VERSION "dbc-export 1 2026.26.6.5"

NS_ :

BS_:

BU_: APB APP APS DAS EPAS3S ESP GTW IBST PARK RADC RCM RCM2 RCM3 TPMS TRCM USM

BO_ 913 EPAS3S_alertMatrix: 8 EPAS3S
 SG_ EPAS3S_matrixIndex M : 0|4@1+ (1,0) [0|15] "" Vector__XXX
 SG_ EPAS3S_a001_sent1Mia m0 : 4|1@1+ (1,0) [0|1] "" Vector__XXX
 SG_ EPAS3S_a002_sent1Error m0 : 5|1@1+ (1,0) [0|1] "" Vector__XXX
 SG_ EPAS3S_a003_trqSens1Supply m0 : 6|1@1+ (1,0) [0|1] "" Vector__XXX
 SG_ EPAS3S_a004_trqSens1Eeprom m0 : 7|1@1+ (1,0) [0|1] "" Vector__XXX
 SG_ EPAS3S_a005_sent2Mia m0 : 8|1@1+ (1,0) [0|1] "" Vector__XXX
 SG_ EPAS3S_a006_sent2Error m0 : 9|1@1+ (1,0) [0|1] "" Vector__XXX
 SG_ EPAS3S_a007_trqSens2Supply m0 : 10|1@1+ (1,0) [0|1] "" Vector__XXX
 SG_ EPAS3S_a008_trqSens2Eeprom m0 : 11|1@1+ (1,0) [0|1] "" Vector__XXX
 SG_ EPAS3S_a009_sentDiff m0 : 12|1@1+ (1,0) [0|1] "" Vector__XXX
 SG_ EPAS3S_a010_trqSensCalError m0 : 13|1@1+ (1,0) [0|1] "" Vector__XXX
 SG_ EPAS3S_a011_currentSensError m0 : 14|1@1+ (1,0) [0|1] "" Vector__XXX
 SG_ EPAS3S_a012_currentSensCalError m0 : 15|1@1+ (1,0) [0|1] "" Vector__XXX
 SG_ EPAS3S_a013_gateDriveError m0 : 16|1@1+ (1,0) [0|1] "" Vector__XXX
 SG_ EPAS3S_a014_gateDriveTxError m0 : 17|1@1+ (1,0) [0|1] "" Vector__XXX
 SG_ EPAS3S_a015_gateDriveEeprom m0 : 18|1@1+ (1,0) [0|1] "" Vector__XXX
 SG_ EPAS3S_a016_phaseUhighUv m0 : 19|1@1+ (1,0) [0|1] "" Vector__XXX
 SG_ EPAS3S_a017_phaseUlowUv m0 : 20|1@1+ (1,0) [0|1] "" Vector__XXX
 SG_ EPAS3S_a018_phaseVhighUv m0 : 21|1@1+ (1,0) [0|1] "" Vector__XXX
 SG_ EPAS3S_a019_phaseVlowUv m0 : 22|1@1+ (1,0) [0|1] "" Vector__XXX
 SG_ EPAS3S_a020_phaseWhighUv m0 : 23|1@1+ (1,0) [0|1] "" Vector__XXX
 SG_ EPAS3S_a021_phaseWlowUv m0 : 24|1@1+ (1,0) [0|1] "" Vector__XXX
 SG_ EPAS3S_a022_phaseUhighOv m0 : 25|1@1+ (1,0) [0|1] "" Vector__XXX
 SG_ EPAS3S_a023_phaseUlowOv m0 : 26|1@1+ (1,0) [0|1] "" Vector__XXX
 SG_ EPAS3S_a024_phaseVhighOv m0 : 27|1@1+ (1,0) [0|1] "" Vector__XXX
 SG_ EPAS3S_a025_phaseVlowOv m0 : 28|1@1+ (1,0) [0|1] "" Vector__XXX
 SG_ EPAS3S_a026_phaseWhighOv m0 : 29|1@1+ (1,0) [0|1] "" Vector__XXX
 SG_ EPAS3S_a027_phaseWlowOv m0 : 30|1@1+ (1,0) [0|1] "" Vector__XXX
 SG_ EPAS3S_a028_phaseUbootUv m0 : 31|1@1+ (1,0) [0|1] "" Vector__XXX
 SG_ EPAS3S_a029_phaseVbootUv m0 : 32|1@1+ (1,0) [0|1] "" Vector__XXX
 SG_ EPAS3S_a030_phaseWbootUv m0 : 33|1@1+ (1,0) [0|1] "" Vector__XXX
 SG_ EPAS3S_a031_abnormalShutdown m0 : 34|1@1+ (1,0) [0|1] "" Vector__XXX
 SG_ EPAS3S_a032_vRegOutputUv m0 : 35|1@1+ (1,0) [0|1] "" Vector__XXX
 SG_ EPAS3S_a033_vRegOutputOv m0 : 36|1@1+ (1,0) [0|1] "" Vector__XXX
 SG_ EPAS3S_a034_vRegError m0 : 37|1@1+ (1,0) [0|1] "" Vector__XXX
 SG_ EPAS3S_a035_vbbSupplyUv m0 : 38|1@1+ (1,0) [0|1] "" Vector__XXX
 SG_ EPAS3S_a036_vbbSupplyOv m0 : 39|1@1+ (1,0) [0|1] "" Vector__XXX
 SG_ EPAS3S_a037_motPos1ParityError m0 : 40|1@1+ (1,0) [0|1] "" Vector__XXX
 SG_ EPAS3S_a038_motPos1Uv m0 : 41|1@1+ (1,0) [0|1] "" Vector__XXX
 SG_ EPAS3S_a039_motPos1MagnetMia m0 : 42|1@1+ (1,0) [0|1] "" Vector__XXX
 SG_ EPAS3S_a040_motPos1LogicError m0 : 43|1@1+ (1,0) [0|1] "" Vector__XXX
 SG_ EPAS3S_a041_motPos1tempError m0 : 44|1@1+ (1,0) [0|1] "" Vector__XXX
 SG_ EPAS3S_a042_motPos2ParityError m0 : 45|1@1+ (1,0) [0|1] "" Vector__XXX
 SG_ EPAS3S_a043_motPos2Uv m0 : 46|1@1+ (1,0) [0|1] "" Vector__XXX
 SG_ EPAS3S_a044_motPos2MagnetMia m0 : 47|1@1+ (1,0) [0|1] "" Vector__XXX
 SG_ EPAS3S_a045_motPos2LogicError m0 : 48|1@1+ (1,0) [0|1] "" Vector__XXX
 SG_ EPAS3S_a046_motPos2tempError m0 : 49|1@1+ (1,0) [0|1] "" Vector__XXX
 SG_ EPAS3S_a047_motPosCorrError m0 : 50|1@1+ (1,0) [0|1] "" Vector__XXX
 SG_ EPAS3S_a048_motPosCalError m0 : 51|1@1+ (1,0) [0|1] "" Vector__XXX
 SG_ EPAS3S_a049_piCtrlError m0 : 52|1@1+ (1,0) [0|1] "" Vector__XXX
 SG_ EPAS3S_a050_mcuSmuError m0 : 53|1@1+ (1,0) [0|1] "" Vector__XXX
 SG_ EPAS3S_a051_mcuSupError m0 : 54|1@1+ (1,0) [0|1] "" Vector__XXX
 SG_ EPAS3S_a052_intWatchdogError m0 : 55|1@1+ (1,0) [0|1] "" Vector__XXX
 SG_ EPAS3S_a053_extWatchdogError m0 : 56|1@1+ (1,0) [0|1] "" Vector__XXX
 SG_ EPAS3S_a054_memoryProtectError m0 : 57|1@1+ (1,0) [0|1] "" Vector__XXX
 SG_ EPAS3S_a055_floatPointError m0 : 58|1@1+ (1,0) [0|1] "" Vector__XXX
 SG_ EPAS3S_a056_battUv m0 : 59|1@1+ (1,0) [0|1] "" Vector__XXX
 SG_ EPAS3S_a057_battUvReduced m0 : 60|1@1+ (1,0) [0|1] "" Vector__XXX
 SG_ EPAS3S_a058_battOv m0 : 61|1@1+ (1,0) [0|1] "" Vector__XXX
 SG_ EPAS3S_a059_battOvReduced m0 : 62|1@1+ (1,0) [0|1] "" Vector__XXX
 SG_ EPAS3S_a060_battBridgeDiff m0 : 63|1@1+ (1,0) [0|1] "" Vector__XXX
 SG_ EPAS3S_a061_bridgeUv m1 : 4|1@1+ (1,0) [0|1] "" Vector__XXX
 SG_ EPAS3S_a062_assistCorrError m1 : 5|1@1+ (1,0) [0|1] "" Vector__XXX
 SG_ EPAS3S_a063_dampCorrError m1 : 6|1@1+ (1,0) [0|1] "" Vector__XXX
 SG_ EPAS3S_a064_phaseCompCorrError m1 : 7|1@1+ (1,0) [0|1] "" Vector__XXX
 SG_ EPAS3S_a065_trqTarCorrError m1 : 8|1@1+ (1,0) [0|1] "" Vector__XXX
 SG_ EPAS3S_a066_returnCorrError m1 : 9|1@1+ (1,0) [0|1] "" Vector__XXX
 SG_ EPAS3S_a067_yawDampCorrError m1 : 10|1@1+ (1,0) [0|1] "" Vector__XXX
 SG_ EPAS3S_a068_hystCorrError m1 : 11|1@1+ (1,0) [0|1] "" Vector__XXX
 SG_ EPAS3S_a069_eacCorrError m1 : 12|1@1+ (1,0) [0|1] "" Vector__XXX
 SG_ EPAS3S_a070_hodCorrError m1 : 13|1@1+ (1,0) [0|1] "" Vector__XXX
 SG_ EPAS3S_a071_vehSpdCorrError m1 : 14|1@1+ (1,0) [0|1] "" Vector__XXX
 SG_ EPAS3S_a072_motFeedFwdError m1 : 15|1@1+ (1,0) [0|1] "" Vector__XXX
 SG_ EPAS3S_a073_motParEstError m1 : 16|1@1+ (1,0) [0|1] "" Vector__XXX
 SG_ EPAS3S_a074_overHeatProtect m1 : 17|1@1+ (1,0) [0|1] "" Vector__XXX
 SG_ EPAS3S_a075_fspPwrCut m1 : 18|1@1+ (1,0) [0|1] "" Vector__XXX
 SG_ EPAS3S_a076_tempSensOutofRange m1 : 19|1@1+ (1,0) [0|1] "" Vector__XXX
 SG_ EPAS3S_a077_highSideFetError m1 : 20|1@1+ (1,0) [0|1] "" Vector__XXX
 SG_ EPAS3S_a078_phaseDisconnectError m1 : 21|1@1+ (1,0) [0|1] "" Vector__XXX
 SG_ EPAS3S_a079_backupCurrentPlaus m1 : 22|1@1+ (1,0) [0|1] "" Vector__XXX
 SG_ EPAS3S_a080_ecuInitArbError m1 : 23|1@1+ (1,0) [0|1] "" Vector__XXX
 SG_ EPAS3S_a081_coggCompError m1 : 24|1@1+ (1,0) [0|1] "" Vector__XXX
 SG_ EPAS3S_a082_polarityCalError m1 : 25|1@1+ (1,0) [0|1] "" Vector__XXX
 SG_ EPAS3S_a083_crcMismatch m1 : 26|1@1+ (1,0) [0|1] "" Vector__XXX
 SG_ EPAS3S_a084_eacCancelled m1 : 27|1@1+ (1,0) [0|1] "" Vector__XXX
 SG_ EPAS3S_a085_canBusOff m1 : 28|1@1+ (1,0) [0|1] "" Vector__XXX
 SG_ EPAS3S_a086_dasMia m1 : 29|1@1+ (1,0) [0|1] "" Vector__XXX
 SG_ EPAS3S_a087_dasCntError m1 : 30|1@1+ (1,0) [0|1] "" Vector__XXX
 SG_ EPAS3S_a088_dasCsError m1 : 31|1@1+ (1,0) [0|1] "" Vector__XXX
 SG_ EPAS3S_a089_espWsMia m1 : 32|1@1+ (1,0) [0|1] "" Vector__XXX
 SG_ EPAS3S_a090_espWsCntError m1 : 33|1@1+ (1,0) [0|1] "" Vector__XXX
 SG_ EPAS3S_a091_espWsCsError m1 : 34|1@1+ (1,0) [0|1] "" Vector__XXX
 SG_ EPAS3S_a092_espWrMia m1 : 35|1@1+ (1,0) [0|1] "" Vector__XXX
 SG_ EPAS3S_a093_espWrCntError m1 : 36|1@1+ (1,0) [0|1] "" Vector__XXX
 SG_ EPAS3S_a094_espWrCsError m1 : 37|1@1+ (1,0) [0|1] "" Vector__XXX
 SG_ EPAS3S_a095_espWsStatus m1 : 38|1@1+ (1,0) [0|1] "" Vector__XXX
 SG_ EPAS3S_a096_rcmMia m1 : 39|1@1+ (1,0) [0|1] "" Vector__XXX
 SG_ EPAS3S_a097_rcmCntError m1 : 40|1@1+ (1,0) [0|1] "" Vector__XXX
 SG_ EPAS3S_a098_rcmCsError m1 : 41|1@1+ (1,0) [0|1] "" Vector__XXX
 SG_ EPAS3S_a099_yawRateStatus m1 : 42|1@1+ (1,0) [0|1] "" Vector__XXX
 SG_ EPAS3S_a100_diMia m1 : 43|1@1+ (1,0) [0|1] "" Vector__XXX
 SG_ EPAS3S_a101_diCntError m1 : 44|1@1+ (1,0) [0|1] "" Vector__XXX
 SG_ EPAS3S_a102_diCsError m1 : 45|1@1+ (1,0) [0|1] "" Vector__XXX
 SG_ EPAS3S_a103_vcFrontMia m1 : 46|1@1+ (1,0) [0|1] "" Vector__XXX
 SG_ EPAS3S_a104_vcFrontCntError m1 : 47|1@1+ (1,0) [0|1] "" Vector__XXX
 SG_ EPAS3S_a105_vcFrontCsError m1 : 48|1@1+ (1,0) [0|1] "" Vector__XXX
 SG_ EPAS3S_a106_vcFrontTempMia m1 : 49|1@1+ (1,0) [0|1] "" Vector__XXX
 SG_ EPAS3S_a107_uiTuneReqMia m1 : 50|1@1+ (1,0) [0|1] "" Vector__XXX
 SG_ EPAS3S_a108_uiTuneReqCntError m1 : 51|1@1+ (1,0) [0|1] "" Vector__XXX
 SG_ EPAS3S_a109_uiTuneReqCsError m1 : 52|1@1+ (1,0) [0|1] "" Vector__XXX
 SG_ EPAS3S_a110_sasMia m1 : 53|1@1+ (1,0) [0|1] "" Vector__XXX
 SG_ EPAS3S_a111_sasCntError m1 : 54|1@1+ (1,0) [0|1] "" Vector__XXX
 SG_ EPAS3S_a112_sasCsError m1 : 55|1@1+ (1,0) [0|1] "" Vector__XXX
 SG_ EPAS3S_a113_sasStatusError m1 : 56|1@1+ (1,0) [0|1] "" Vector__XXX
 SG_ EPAS3S_a114_gtwConfigMia m1 : 57|1@1+ (1,0) [0|1] "" Vector__XXX
 SG_ EPAS3S_a115_ecuStatMia m1 : 58|1@1+ (1,0) [0|1] "" Vector__XXX
 SG_ EPAS3S_a116_ecuStatCntError m1 : 59|1@1+ (1,0) [0|1] "" Vector__XXX
 SG_ EPAS3S_a117_ecuStatCrcError m1 : 60|1@1+ (1,0) [0|1] "" Vector__XXX
 SG_ EPAS3S_a118_privateBusOff m1 : 61|1@1+ (1,0) [0|1] "" Vector__XXX
 SG_ EPAS3S_a119_pvtEcuStatMia m1 : 62|1@1+ (1,0) [0|1] "" Vector__XXX
 SG_ EPAS3S_a120_pvtEcuStatCntError m1 : 63|1@1+ (1,0) [0|1] "" Vector__XXX
 SG_ EPAS3S_a121_pvtEcuStatCrcError m2 : 4|1@1+ (1,0) [0|1] "" Vector__XXX
 SG_ EPAS3S_a122_olpActive m2 : 5|1@1+ (1,0) [0|1] "" Vector__XXX
 SG_ EPAS3S_a123_combEcu2StatFail m2 : 6|1@1+ (1,0) [0|1] "" Vector__XXX
 SG_ EPAS3S_a124_tempSensStuckInRange m2 : 7|1@1+ (1,0) [0|1] "" Vector__XXX
 SG_ EPAS3S_a125_trqSensTrimOutRange m2 : 8|1@1+ (1,0) [0|1] "" Vector__XXX
 SG_ EPAS3S_a126_apsMia m2 : 9|1@1+ (1,0) [0|1] "" Vector__XXX
 SG_ EPAS3S_a127_apsCntError m2 : 10|1@1+ (1,0) [0|1] "" Vector__XXX
 SG_ EPAS3S_a128_apsCsError m2 : 11|1@1+ (1,0) [0|1] "" Vector__XXX
 SG_ EPAS3S_a129_combEcu1StatFail m2 : 12|1@1+ (1,0) [0|1] "" Vector__XXX
 SG_ EPAS3S_a130_sasOffsetNotCal m2 : 13|1@1+ (1,0) [0|1] "" Vector__XXX
 SG_ EPAS3S_a131_phaseFeedbackError m2 : 14|1@1+ (1,0) [0|1] "" Vector__XXX
 SG_ EPAS3S_a132_motFeedFwdCounter25 m2 : 15|1@1+ (1,0) [0|1] "" Vector__XXX
 SG_ EPAS3S_a133_motFeedFwdCounter50 m2 : 16|1@1+ (1,0) [0|1] "" Vector__XXX
 SG_ EPAS3S_a134_motFeedFwdCounter85 m2 : 17|1@1+ (1,0) [0|1] "" Vector__XXX
 SG_ EPAS3S_a135_piCtrlCounter25 m2 : 18|1@1+ (1,0) [0|1] "" Vector__XXX
 SG_ EPAS3S_a136_piCtrlCounter50 m2 : 19|1@1+ (1,0) [0|1] "" Vector__XXX
 SG_ EPAS3S_a137_piCtrlCounter85 m2 : 20|1@1+ (1,0) [0|1] "" Vector__XXX
 SG_ EPAS3S_a144_diSpdMia m2 : 21|1@1+ (1,0) [0|1] "" Vector__XXX
 SG_ EPAS3S_a145_diSpdCntError m2 : 22|1@1+ (1,0) [0|1] "" Vector__XXX
 SG_ EPAS3S_a146_diSpdCsError m2 : 23|1@1+ (1,0) [0|1] "" Vector__XXX
 SG_ EPAS3S_a147_backupVehSpeed m2 : 24|1@1+ (1,0) [0|1] "" Vector__XXX
 SG_ EPAS3S_a148_vMaxAssist m2 : 25|1@1+ (1,0) [0|1] "" Vector__XXX
 SG_ EPAS3S_a149_currentSensPathSwitc m2 : 26|1@1+ (1,0) [0|1] "" Vector__XXX
 SG_ EPAS3S_a150_currentSensOffsetDet m2 : 27|1@1+ (1,0) [0|1] "" Vector__XXX
 SG_ EPAS3S_a151_dcsCboot m2 : 28|1@1+ (1,0) [0|1] "" Vector__XXX
 SG_ EPAS3S_a152_dcsDiagReg m2 : 29|1@1+ (1,0) [0|1] "" Vector__XXX
 SG_ EPAS3S_a153_dcsInitOffset m2 : 30|1@1+ (1,0) [0|1] "" Vector__XXX
 SG_ EPAS3S_a154_assistTorqueDisabled m2 : 31|1@1+ (1,0) [0|1] "" Vector__XXX
 SG_ EPAS3S_a155_backupEacActive m2 : 32|1@1+ (1,0) [0|1] "" Vector__XXX
 SG_ EPAS3S_a156_angleSensorDivergenc m2 : 33|1@1+ (1,0) [0|1] "" Vector__XXX
 SG_ EPAS3S_a157_pmState2Mia m2 : 34|1@1+ (1,0) [0|1] "" Vector__XXX
 SG_ EPAS3S_a158_pmState2CntError m2 : 35|1@1+ (1,0) [0|1] "" Vector__XXX
 SG_ EPAS3S_a159_pmState2CsError m2 : 36|1@1+ (1,0) [0|1] "" Vector__XXX
 SG_ EPAS3S_a160_latentFaultTestResul m2 : 37|1@1+ (1,0) [0|1] "" Vector__XXX
 SG_ EPAS3S_a161_initTestPhaDisconnIn m2 : 38|1@1+ (1,0) [0|1] "" Vector__XXX
 SG_ EPAS3S_a162_initTestHSDFetInfo m2 : 39|1@1+ (1,0) [0|1] "" Vector__XXX
 SG_ EPAS3S_a163_initTestGateDrvrInfo m2 : 40|1@1+ (1,0) [0|1] "" Vector__XXX
 SG_ EPAS3S_a164_initTestDCSInfo m2 : 41|1@1+ (1,0) [0|1] "" Vector__XXX
 SG_ EPAS3S_a165_epbStatusMia m2 : 42|1@1+ (1,0) [0|1] "" Vector__XXX
 SG_ EPAS3S_a166_epbStatusCntError m2 : 43|1@1+ (1,0) [0|1] "" Vector__XXX
 SG_ EPAS3S_a167_epbStatusCsError m2 : 44|1@1+ (1,0) [0|1] "" Vector__XXX
 SG_ EPAS3S_a168_torsionBarTorqueQfDe m2 : 45|1@1+ (1,0) [0|1] "" Vector__XXX

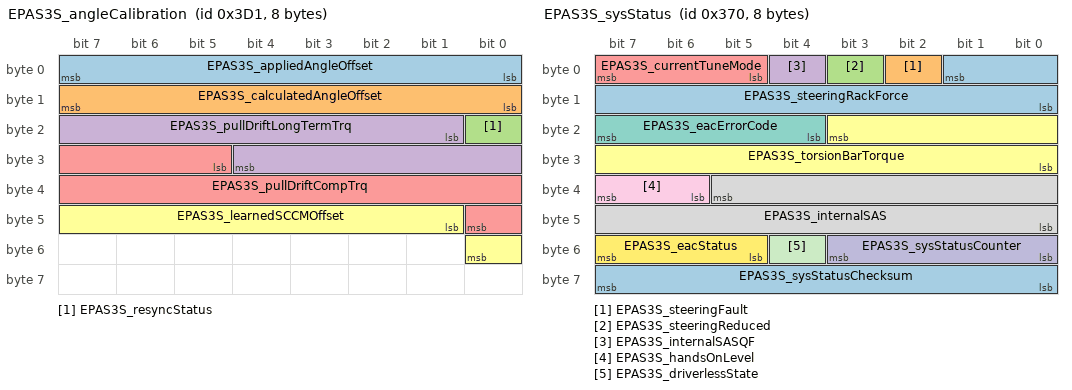
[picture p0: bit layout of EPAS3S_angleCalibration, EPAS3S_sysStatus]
BO_ 977 EPAS3S_angleCalibration: 8 EPAS3S
 SG_ EPAS3S_appliedAngleOffset : 0|8@1+ (0.1,-12.8) [-12.8|12.7] "deg" Vector__XXX
 SG_ EPAS3S_calculatedAngleOffset : 8|8@1+ (0.1,-12.8) [-12.8|12.7] "deg" Vector__XXX
 SG_ EPAS3S_resyncStatus : 16|1@1+ (1,0) [0|1] "" Vector__XXX
 SG_ EPAS3S_pullDriftLongTermTrq : 17|12@1+ (0.01,-10) [-10|10] "Nm" Vector__XXX
 SG_ EPAS3S_pullDriftCompTrq : 29|12@1+ (0.01,-10) [-10|10] "Nm" Vector__XXX
 SG_ EPAS3S_learnedSCCMOffset : 41|8@1+ (0.1,-12.8) [-12.8|12.7] "deg" Vector__XXX

BO_ 785 EPAS3S_info: 8 EPAS3S
 SG_ EPAS3S_infoIndex M : 0|8@1+ (1,0) [0|255] "" Vector__XXX
 SG_ EPAS3S_infoBuildType m10 : 8|8@1+ (1,0) [0|255] "" Vector__XXX
 SG_ EPAS3S_infoComponentID m10 : 48|16@1+ (1,0) [0|65535] "" Vector__XXX
 SG_ EPAS3S_infoPcbaID m11 : 16|8@1+ (1,0) [0|255] "" Vector__XXX
 SG_ EPAS3S_infoAssemblyID m11 : 24|8@1+ (1,0) [0|255] "" Vector__XXX
 SG_ EPAS3S_infoUsageID m11 : 32|16@1+ (1,0) [0|65535] "" Vector__XXX
 SG_ EPAS3S_infoApplicationCRC m13 : 32|32@1+ (1,0) [0|4294967295] "" Vector__XXX
 SG_ EPAS3S_infoBootUdsProtoVersion m20 : 8|8@1+ (1,0) [0|255] "" Vector__XXX
 SG_ EPAS3S_infoBootloaderCRC m20 : 32|32@1+ (1,0) [0|4294967295] "" Vector__XXX
 SG_ EPAS3S_infoSubcomponent2 m23 : 32|32@1+ (1,0) [0|4294967295] "" Vector__XXX

BO_ 880 EPAS3S_sysStatus: 8 EPAS3S
 SG_ EPAS3S_steeringRackForce : 1|10@0+ (50,-25575) [-25575|25525] "N" Vector__XXX
 SG_ EPAS3S_steeringFault : 2|1@1+ (1,0) [0|1] "" Vector__XXX
 SG_ EPAS3S_steeringReduced : 3|1@1+ (1,0) [0|1] "" Vector__XXX
 SG_ EPAS3S_internalSASQF : 4|1@1+ (1,0) [0|1] "" Vector__XXX
 SG_ EPAS3S_currentTuneMode : 5|3@1+ (1,0) [0|7] "" Vector__XXX
 SG_ EPAS3S_torsionBarTorque : 19|12@0+ (0.01,-20.5) [-20.5|20.44] "Nm" Vector__XXX
 SG_ EPAS3S_eacErrorCode : 20|4@1+ (1,0) [0|14] "" Vector__XXX
 SG_ EPAS3S_internalSAS : 37|14@0+ (0.1,-819.2) [-819.2|819] "deg" Vector__XXX
 SG_ EPAS3S_handsOnLevel : 38|2@1+ (1,0) [0|3] "" Vector__XXX
 SG_ EPAS3S_sysStatusCounter : 48|4@1+ (1,0) [0|15] "" Vector__XXX
 SG_ EPAS3S_driverlessState : 52|1@1+ (1,0) [0|1] "" Vector__XXX
 SG_ EPAS3S_eacStatus : 53|3@1+ (1,0) [0|7] "" Vector__XXX
 SG_ EPAS3S_sysStatusChecksum : 56|8@1+ (1,0) [0|255] "" Vector__XXX

BO_ 1848 EPAS3S_udsResponse: 8 EPAS3S
 SG_ EPAS3S_udsResponseData : 7|64@0+ (1,0) [0|1.84467440737e+19] "" Vector__XXX

BO_ 981 ESP_alertMatrix: 8 ESP
 SG_ ESP_matrixIndex M : 0|4@1+ (1,0) [0|15] "" Vector__XXX
 SG_ ESP_a001_ecuGenericFault m0 : 4|1@1+ (1,0) [0|1] "" Vector__XXX
 SG_ ESP_a002_valvesGenericFault m0 : 5|1@1+ (1,0) [0|1] "" Vector__XXX
 SG_ ESP_a003_outletValvesFault m0 : 6|1@1+ (1,0) [0|1] "" Vector__XXX
 SG_ ESP_a004_inletValvesFault m0 : 7|1@1+ (1,0) [0|1] "" Vector__XXX
 SG_ ESP_a005_HSVValvesFault m0 : 8|1@1+ (1,0) [0|1] "" Vector__XXX
 SG_ ESP_a006_USVValvesFault m0 : 9|1@1+ (1,0) [0|1] "" Vector__XXX
 SG_ ESP_a007_pumpMotorFault m0 : 10|1@1+ (1,0) [0|1] "" Vector__XXX
 SG_ ESP_a008_pumpMotor12VsupplyLow m0 : 11|1@1+ (1,0) [0|1] "" Vector__XXX
 SG_ ESP_a009_12VHardUndervoltage m0 : 12|1@1+ (1,0) [0|1] "" Vector__XXX
 SG_ ESP_a010_12VUndervoltage m0 : 13|1@1+ (1,0) [0|1] "" Vector__XXX
 SG_ ESP_a011_12VSystemUndervoltage m0 : 14|1@1+ (1,0) [0|1] "" Vector__XXX
 SG_ ESP_a012_netUndervoltage m0 : 15|1@1+ (1,0) [0|1] "" Vector__XXX
 SG_ ESP_a013_valveRelayUndervoltage m0 : 16|1@1+ (1,0) [0|1] "" Vector__XXX
 SG_ ESP_a014_WSSSupplyUndervoltage m0 : 17|1@1+ (1,0) [0|1] "" Vector__XXX
 SG_ ESP_a015_12VSupplyOvervoltage m0 : 18|1@1+ (1,0) [0|1] "" Vector__XXX
 SG_ ESP_a016_12VSystemOvervoltage m0 : 19|1@1+ (1,0) [0|1] "" Vector__XXX
 SG_ ESP_a017_netOvervoltage m0 : 20|1@1+ (1,0) [0|1] "" Vector__XXX
 SG_ ESP_a018_WSSSignFrontAxle m0 : 21|1@1+ (1,0) [0|1] "" Vector__XXX
 SG_ ESP_a019_WSSSignRearAxle m0 : 22|1@1+ (1,0) [0|1] "" Vector__XXX
 SG_ ESP_a020_WSSGenericTempFault m0 : 23|1@1+ (1,0) [0|1] "" Vector__XXX
 SG_ ESP_a021_WSSGeneralVDiffFault m0 : 24|1@1+ (1,0) [0|1] "" Vector__XXX
 SG_ ESP_a022_WSSDirectionFault m0 : 25|1@1+ (1,0) [0|1] "" Vector__XXX
 SG_ ESP_a023_WSSSeveralSuspected m0 : 26|1@1+ (1,0) [0|1] "" Vector__XXX
 SG_ ESP_a024_WSSReverseCurrent m0 : 27|1@1+ (1,0) [0|1] "" Vector__XXX
 SG_ ESP_a025_FrLWSSOpenOrShortToGnd m0 : 28|1@1+ (1,0) [0|1] "" Vector__XXX
 SG_ ESP_a026_FrLWSSShortTo12V m0 : 29|1@1+ (1,0) [0|1] "" Vector__XXX
 SG_ ESP_a027_FrLWSSLineInterruption m0 : 30|1@1+ (1,0) [0|1] "" Vector__XXX
 SG_ ESP_a028_FrLWSSMaxSpeedExceeded m0 : 31|1@1+ (1,0) [0|1] "" Vector__XXX
 SG_ ESP_a029_FrLWSSTooManyPulses m0 : 32|1@1+ (1,0) [0|1] "" Vector__XXX
 SG_ ESP_a030_FrLWSSLostSignal m0 : 33|1@1+ (1,0) [0|1] "" Vector__XXX
 SG_ ESP_a031_FrLWSSNoPulsesDetected m0 : 34|1@1+ (1,0) [0|1] "" Vector__XXX
 SG_ ESP_a032_FrLWSSWrongSensorType m0 : 35|1@1+ (1,0) [0|1] "" Vector__XXX
 SG_ ESP_a033_FrLWSSSignalNoise m0 : 36|1@1+ (1,0) [0|1] "" Vector__XXX
 SG_ ESP_a034_FrLWSSVDiffFault m0 : 37|1@1+ (1,0) [0|1] "" Vector__XXX
 SG_ ESP_a035_FrLWSSDirectionFault m0 : 38|1@1+ (1,0) [0|1] "" Vector__XXX
 SG_ ESP_a036_FrLWSSLargeAirGap m0 : 39|1@1+ (1,0) [0|1] "" Vector__XXX
 SG_ ESP_a037_FrLWSSSupplyShortToGnd m0 : 40|1@1+ (1,0) [0|1] "" Vector__XXX
 SG_ ESP_a038_FrLWSSGeneralFault m0 : 41|1@1+ (1,0) [0|1] "" Vector__XXX
 SG_ ESP_a039_FrRWSSOpenOrShortToGnd m0 : 42|1@1+ (1,0) [0|1] "" Vector__XXX
 SG_ ESP_a040_FrRWSSShortTo12V m0 : 43|1@1+ (1,0) [0|1] "" Vector__XXX
 SG_ ESP_a041_FrRWSSLineInterruption m0 : 44|1@1+ (1,0) [0|1] "" Vector__XXX
 SG_ ESP_a042_FrRWSSMaxSpeedExceeded m0 : 45|1@1+ (1,0) [0|1] "" Vector__XXX
 SG_ ESP_a043_FrRWSSTooManyPulses m0 : 46|1@1+ (1,0) [0|1] "" Vector__XXX
 SG_ ESP_a044_FrRWSSLostSignal m0 : 47|1@1+ (1,0) [0|1] "" Vector__XXX
 SG_ ESP_a045_FrRWSSNoPulsesDetected m0 : 48|1@1+ (1,0) [0|1] "" Vector__XXX
 SG_ ESP_a046_FrRWSSWrongSensorType m0 : 49|1@1+ (1,0) [0|1] "" Vector__XXX
 SG_ ESP_a047_FrRWSSSignalNoise m0 : 50|1@1+ (1,0) [0|1] "" Vector__XXX
 SG_ ESP_a048_FrRWSSVDiffFault m0 : 51|1@1+ (1,0) [0|1] "" Vector__XXX
 SG_ ESP_a049_FrRWSSDirectionFault m0 : 52|1@1+ (1,0) [0|1] "" Vector__XXX
 SG_ ESP_a050_FrRWSSLargeAirGap m0 : 53|1@1+ (1,0) [0|1] "" Vector__XXX
 SG_ ESP_a051_FrRWSSSupplyShortToGnd m0 : 54|1@1+ (1,0) [0|1] "" Vector__XXX
 SG_ ESP_a052_FrRWSSGeneralFault m0 : 55|1@1+ (1,0) [0|1] "" Vector__XXX
 SG_ ESP_a053_ReLWSSOpenOrShortToGnd m0 : 56|1@1+ (1,0) [0|1] "" Vector__XXX
 SG_ ESP_a054_ReLWSSShortTo12V m0 : 57|1@1+ (1,0) [0|1] "" Vector__XXX
 SG_ ESP_a055_ReLWSSLineInterruption m0 : 58|1@1+ (1,0) [0|1] "" Vector__XXX
 SG_ ESP_a056_ReLWSSMaxSpeedExceeded m0 : 59|1@1+ (1,0) [0|1] "" Vector__XXX
 SG_ ESP_a057_ReLWSSTooManyPulses m0 : 60|1@1+ (1,0) [0|1] "" Vector__XXX
 SG_ ESP_a058_ReLWSSLostSignal m0 : 61|1@1+ (1,0) [0|1] "" Vector__XXX
 SG_ ESP_a059_ReLWSSNoPulsesDetected m0 : 62|1@1+ (1,0) [0|1] "" Vector__XXX
 SG_ ESP_a060_ReLWSSWrongSensorType m0 : 63|1@1+ (1,0) [0|1] "" Vector__XXX
 SG_ ESP_a061_ReLWSSSignalNoise m1 : 4|1@1+ (1,0) [0|1] "" Vector__XXX
 SG_ ESP_a062_ReLWSSVDiffFault m1 : 5|1@1+ (1,0) [0|1] "" Vector__XXX
 SG_ ESP_a063_ReLWSSDirectionFault m1 : 6|1@1+ (1,0) [0|1] "" Vector__XXX
 SG_ ESP_a064_ReLWSSLargeAirGap m1 : 7|1@1+ (1,0) [0|1] "" Vector__XXX
 SG_ ESP_a065_ReLWSSSupplyShortToGnd m1 : 8|1@1+ (1,0) [0|1] "" Vector__XXX
 SG_ ESP_a066_ReLWSSGeneralFault m1 : 9|1@1+ (1,0) [0|1] "" Vector__XXX
 SG_ ESP_a067_ReRWSSOpenOrShortToGnd m1 : 10|1@1+ (1,0) [0|1] "" Vector__XXX
 SG_ ESP_a068_ReRWSSShortTo12V m1 : 11|1@1+ (1,0) [0|1] "" Vector__XXX
 SG_ ESP_a069_ReRWSSLineInterruption m1 : 12|1@1+ (1,0) [0|1] "" Vector__XXX
 SG_ ESP_a070_ReRWSSMaxSpeedExceeded m1 : 13|1@1+ (1,0) [0|1] "" Vector__XXX
 SG_ ESP_a071_ReRWSSTooManyPulses m1 : 14|1@1+ (1,0) [0|1] "" Vector__XXX
 SG_ ESP_a072_ReRWSSLostSignal m1 : 15|1@1+ (1,0) [0|1] "" Vector__XXX
 SG_ ESP_a073_ReRWSSNoPulsesDetected m1 : 16|1@1+ (1,0) [0|1] "" Vector__XXX
 SG_ ESP_a074_ReRWSSWrongSensorType m1 : 17|1@1+ (1,0) [0|1] "" Vector__XXX
 SG_ ESP_a075_ReRWSSSignalNoise m1 : 18|1@1+ (1,0) [0|1] "" Vector__XXX
 SG_ ESP_a076_ReRWSSVDiffFault m1 : 19|1@1+ (1,0) [0|1] "" Vector__XXX
 SG_ ESP_a077_ReRWSSDirectionFault m1 : 20|1@1+ (1,0) [0|1] "" Vector__XXX
 SG_ ESP_a078_ReRWSSLargeAirGap m1 : 21|1@1+ (1,0) [0|1] "" Vector__XXX
 SG_ ESP_a079_ReRWSSSupplyShortToGnd m1 : 22|1@1+ (1,0) [0|1] "" Vector__XXX
 SG_ ESP_a080_ReRWSSGeneralFault m1 : 23|1@1+ (1,0) [0|1] "" Vector__XXX
 SG_ ESP_a081_PressureSensorShort m1 : 24|1@1+ (1,0) [0|1] "" Vector__XXX
 SG_ ESP_a082_PMCSensorOffsetHigh m1 : 25|1@1+ (1,0) [0|1] "" Vector__XXX
 SG_ ESP_a083_PMCSensorFault m1 : 26|1@1+ (1,0) [0|1] "" Vector__XXX
 SG_ ESP_a084_BrakeFluidReservoirLow m1 : 27|1@1+ (1,0) [0|1] "" Vector__XXX
 SG_ ESP_a085_BrakeSwitchStuckHigh m1 : 28|1@1+ (1,0) [0|1] "" Vector__XXX
 SG_ ESP_a086_BrakeSwitchImplausible1 m1 : 29|1@1+ (1,0) [0|1] "" Vector__XXX
 SG_ ESP_a087_BrakeSwitchImplausible3 m1 : 30|1@1+ (1,0) [0|1] "" Vector__XXX
 SG_ ESP_a088_absContinuousControl m1 : 31|1@1+ (1,0) [0|1] "" Vector__XXX
 SG_ ESP_a089_absNoPressureIncrease m1 : 32|1@1+ (1,0) [0|1] "" Vector__XXX
 SG_ ESP_a090_vdcContinuousControl m1 : 33|1@1+ (1,0) [0|1] "" Vector__XXX
 SG_ ESP_a091_CANUndervoltage m1 : 34|1@1+ (1,0) [0|1] "" Vector__XXX
 SG_ ESP_a092_CANOvervoltage m1 : 35|1@1+ (1,0) [0|1] "" Vector__XXX
 SG_ ESP_a093_partyBusOff m1 : 36|1@1+ (1,0) [0|1] "" Vector__XXX
 SG_ ESP_a094_partyBusPassive m1 : 37|1@1+ (1,0) [0|1] "" Vector__XXX
 SG_ ESP_a095_chassisBusOff m1 : 38|1@1+ (1,0) [0|1] "" Vector__XXX
 SG_ ESP_a096_chassisBusPassive m1 : 39|1@1+ (1,0) [0|1] "" Vector__XXX
 SG_ ESP_a097_tcsRefSpeedNotInit m1 : 40|1@1+ (1,0) [0|1] "" Vector__XXX
 SG_ ESP_a098_vdcRefSpeedNotInit m1 : 41|1@1+ (1,0) [0|1] "" Vector__XXX
 SG_ ESP_a099_brakeTempModelOverheat m1 : 42|1@1+ (1,0) [0|1] "" Vector__XXX
 SG_ ESP_a100_brakeTempModelDisabled m1 : 43|1@1+ (1,0) [0|1] "" Vector__XXX
 SG_ ESP_a101_ebdFault m1 : 44|1@1+ (1,0) [0|1] "" Vector__XXX
 SG_ ESP_a102_absFault m1 : 45|1@1+ (1,0) [0|1] "" Vector__XXX
 SG_ ESP_a103_stabilityControlFault m1 : 46|1@1+ (1,0) [0|1] "" Vector__XXX
 SG_ ESP_a104_hbcEnabled m1 : 47|1@1+ (1,0) [0|1] "" Vector__XXX
 SG_ ESP_a105_ebrFault m1 : 48|1@1+ (1,0) [0|1] "" Vector__XXX
 SG_ ESP_a106_vdcActuatorFault m1 : 49|1@1+ (1,0) [0|1] "" Vector__XXX
 SG_ ESP_a107_reserved107 m1 : 50|1@1+ (1,0) [0|1] "" Vector__XXX
 SG_ ESP_a108_reserved108 m1 : 51|1@1+ (1,0) [0|1] "" Vector__XXX
 SG_ ESP_a109_reserved109 m1 : 52|1@1+ (1,0) [0|1] "" Vector__XXX
 SG_ ESP_a110_rollerBenchActive m1 : 53|1@1+ (1,0) [0|1] "" Vector__XXX
 SG_ ESP_a111_absActive m1 : 54|1@1+ (1,0) [0|1] "" Vector__XXX
 SG_ ESP_a112_espActive m1 : 55|1@1+ (1,0) [0|1] "" Vector__XXX
 SG_ ESP_a113_btcActive m1 : 56|1@1+ (1,0) [0|1] "" Vector__XXX
 SG_ ESP_a114_tvdcActive m1 : 57|1@1+ (1,0) [0|1] "" Vector__XXX
 SG_ ESP_a115_ebdActive m1 : 58|1@1+ (1,0) [0|1] "" Vector__XXX
 SG_ ESP_a116_tsmActive m1 : 59|1@1+ (1,0) [0|1] "" Vector__XXX
 SG_ ESP_a117_hbaActive m1 : 60|1@1+ (1,0) [0|1] "" Vector__XXX
 SG_ ESP_a118_hfcActive m1 : 61|1@1+ (1,0) [0|1] "" Vector__XXX
 SG_ ESP_a119_hbbActive m1 : 62|1@1+ (1,0) [0|1] "" Vector__XXX
 SG_ ESP_a120_rmiActive m1 : 63|1@1+ (1,0) [0|1] "" Vector__XXX
 SG_ ESP_a121_regenTcActive m2 : 4|1@1+ (1,0) [0|1] "" Vector__XXX
 SG_ ESP_a122_bdwActive m2 : 5|1@1+ (1,0) [0|1] "" Vector__XXX
 SG_ ESP_a123_ebrActive m2 : 6|1@1+ (1,0) [0|1] "" Vector__XXX
 SG_ ESP_a124_ebrSkidActive m2 : 7|1@1+ (1,0) [0|1] "" Vector__XXX
 SG_ ESP_a125_reserved125 m2 : 8|1@1+ (1,0) [0|1] "" Vector__XXX
 SG_ ESP_a126_reserved126 m2 : 9|1@1+ (1,0) [0|1] "" Vector__XXX
 SG_ ESP_a127_reserved127 m2 : 10|1@1+ (1,0) [0|1] "" Vector__XXX
 SG_ ESP_a128_reserved128 m2 : 11|1@1+ (1,0) [0|1] "" Vector__XXX
 SG_ ESP_a129_reserved129 m2 : 12|1@1+ (1,0) [0|1] "" Vector__XXX
 SG_ ESP_a130_EPAS3PsysStatusTimeout m2 : 13|1@1+ (1,0) [0|1] "" Vector__XXX
 SG_ ESP_a131_EPAS3PsysStatusDLC m2 : 14|1@1+ (1,0) [0|1] "" Vector__XXX
 SG_ ESP_a132_EPAS3PsysStatusChecksum m2 : 15|1@1+ (1,0) [0|1] "" Vector__XXX
 SG_ ESP_a133_EPAS3PsysStatusCounter m2 : 16|1@1+ (1,0) [0|1] "" Vector__XXX
 SG_ ESP_a134_steeringAngleInvalid m2 : 17|1@1+ (1,0) [0|1] "" Vector__XXX
 SG_ ESP_a135_steeringAngleNoCenter m2 : 18|1@1+ (1,0) [0|1] "" Vector__XXX
 SG_ ESP_a136_steeringAngleFrozen m2 : 19|1@1+ (1,0) [0|1] "" Vector__XXX
 SG_ ESP_a137_steeringOffsetTooLarge m2 : 20|1@1+ (1,0) [0|1] "" Vector__XXX
 SG_ ESP_a138_steeringAngleImplaus m2 : 21|1@1+ (1,0) [0|1] "" Vector__XXX
 SG_ ESP_a139_steeringAngleWrongSign m2 : 22|1@1+ (1,0) [0|1] "" Vector__XXX
 SG_ ESP_a140_RCMInertial1Timeout m2 : 23|1@1+ (1,0) [0|1] "" Vector__XXX
 SG_ ESP_a141_RCMInertial1DLC m2 : 24|1@1+ (1,0) [0|1] "" Vector__XXX
 SG_ ESP_a142_RCMInertial1Checksum m2 : 25|1@1+ (1,0) [0|1] "" Vector__XXX
 SG_ ESP_a143_RCMInertial1Counter m2 : 26|1@1+ (1,0) [0|1] "" Vector__XXX
 SG_ ESP_a144_yawMaxLatency m2 : 27|1@1+ (1,0) [0|1] "" Vector__XXX
 SG_ ESP_a145_yawInitFault m2 : 28|1@1+ (1,0) [0|1] "" Vector__XXX
 SG_ ESP_a146_yawInvalidValue m2 : 29|1@1+ (1,0) [0|1] "" Vector__XXX
 SG_ ESP_a147_yawSensorNotAvailable m2 : 30|1@1+ (1,0) [0|1] "" Vector__XXX
 SG_ ESP_a148_yawSignalFault m2 : 31|1@1+ (1,0) [0|1] "" Vector__XXX
 SG_ ESP_a149_yawInvalidSign m2 : 32|1@1+ (1,0) [0|1] "" Vector__XXX
 SG_ ESP_a150_yawImplausible m2 : 33|1@1+ (1,0) [0|1] "" Vector__XXX
 SG_ ESP_a151_RCMInertial2Timeout m2 : 34|1@1+ (1,0) [0|1] "" Vector__XXX
 SG_ ESP_a152_RCMInertial2DLC m2 : 35|1@1+ (1,0) [0|1] "" Vector__XXX
 SG_ ESP_a153_RCMInertial2Checksum m2 : 36|1@1+ (1,0) [0|1] "" Vector__XXX
 SG_ ESP_a154_RCMInertial2Counter m2 : 37|1@1+ (1,0) [0|1] "" Vector__XXX
 SG_ ESP_a155_ayMaxLatency m2 : 38|1@1+ (1,0) [0|1] "" Vector__XXX
 SG_ ESP_a156_ayInitFault m2 : 39|1@1+ (1,0) [0|1] "" Vector__XXX
 SG_ ESP_a157_ayInvalidValue m2 : 40|1@1+ (1,0) [0|1] "" Vector__XXX
 SG_ ESP_a158_aySensorNotAvailable m2 : 41|1@1+ (1,0) [0|1] "" Vector__XXX
 SG_ ESP_a159_aySignalFault m2 : 42|1@1+ (1,0) [0|1] "" Vector__XXX
 SG_ ESP_a160_ayRangeExceeded m2 : 43|1@1+ (1,0) [0|1] "" Vector__XXX
 SG_ ESP_a161_ayOffsetExceeded m2 : 44|1@1+ (1,0) [0|1] "" Vector__XXX
 SG_ ESP_a162_ayImplausible m2 : 45|1@1+ (1,0) [0|1] "" Vector__XXX
 SG_ ESP_a163_axMaxLatency m2 : 46|1@1+ (1,0) [0|1] "" Vector__XXX
 SG_ ESP_a164_axInitFault m2 : 47|1@1+ (1,0) [0|1] "" Vector__XXX
 SG_ ESP_a165_axInvalidValue m2 : 48|1@1+ (1,0) [0|1] "" Vector__XXX
 SG_ ESP_a166_axSensorNotAvailable m2 : 49|1@1+ (1,0) [0|1] "" Vector__XXX
 SG_ ESP_a167_axSignalFault m2 : 50|1@1+ (1,0) [0|1] "" Vector__XXX
 SG_ ESP_a168_axRangeExceeded m2 : 51|1@1+ (1,0) [0|1] "" Vector__XXX
 SG_ ESP_a169_axOffsetExceeded m2 : 52|1@1+ (1,0) [0|1] "" Vector__XXX
 SG_ ESP_a170_axSignalFrozen m2 : 53|1@1+ (1,0) [0|1] "" Vector__XXX
 SG_ ESP_a171_axImplausible m2 : 54|1@1+ (1,0) [0|1] "" Vector__XXX
 SG_ ESP_a172_IBSTparty1Timeout m2 : 55|1@1+ (1,0) [0|1] "" Vector__XXX
 SG_ ESP_a173_IBSTparty1DLC m2 : 56|1@1+ (1,0) [0|1] "" Vector__XXX
 SG_ ESP_a174_IBSTparty1Checksum m2 : 57|1@1+ (1,0) [0|1] "" Vector__XXX
 SG_ ESP_a175_IBSTparty1Counter m2 : 58|1@1+ (1,0) [0|1] "" Vector__XXX
 SG_ ESP_a176_IBSTEBRNotAvailable m2 : 59|1@1+ (1,0) [0|1] "" Vector__XXX
 SG_ ESP_a177_IBSTOutputRodDrvInvalid m2 : 60|1@1+ (1,0) [0|1] "" Vector__XXX
 SG_ ESP_a178_IBSTOutputRodActInvalid m2 : 61|1@1+ (1,0) [0|1] "" Vector__XXX
 SG_ ESP_a179_IBSTparty2Timeout m2 : 62|1@1+ (1,0) [0|1] "" Vector__XXX
 SG_ ESP_a180_IBSTparty2Checksum m2 : 63|1@1+ (1,0) [0|1] "" Vector__XXX
 SG_ ESP_a181_IBSTparty2DLC m3 : 4|1@1+ (1,0) [0|1] "" Vector__XXX
 SG_ ESP_a182_IBSTparty2Counter m3 : 5|1@1+ (1,0) [0|1] "" Vector__XXX
 SG_ ESP_a183_IBSTStatusOff m3 : 6|1@1+ (1,0) [0|1] "" Vector__XXX
 SG_ ESP_a184_IBSTpRunoutInvalid m3 : 7|1@1+ (1,0) [0|1] "" Vector__XXX
 SG_ ESP_a185_IBSTFeedforwardBackup m3 : 8|1@1+ (1,0) [0|1] "" Vector__XXX
 SG_ ESP_a186_IBSTBrakeAppliedInvalid m3 : 9|1@1+ (1,0) [0|1] "" Vector__XXX
 SG_ ESP_a187_DIbtcRequestTimeout m3 : 10|1@1+ (1,0) [0|1] "" Vector__XXX
 SG_ ESP_a188_DIbtcRequestDLC m3 : 11|1@1+ (1,0) [0|1] "" Vector__XXX
 SG_ ESP_a189_DIbtcRequestChecksum m3 : 12|1@1+ (1,0) [0|1] "" Vector__XXX
 SG_ ESP_a190_DIbtcRequestCounter m3 : 13|1@1+ (1,0) [0|1] "" Vector__XXX
 SG_ ESP_a191_DIchassisControlTimeout m3 : 14|1@1+ (1,0) [0|1] "" Vector__XXX
 SG_ ESP_a192_DIchassisControlDLC m3 : 15|1@1+ (1,0) [0|1] "" Vector__XXX
 SG_ ESP_a193_DIchassisControlChecksu m3 : 16|1@1+ (1,0) [0|1] "" Vector__XXX
 SG_ ESP_a194_DIchassisControlCounter m3 : 17|1@1+ (1,0) [0|1] "" Vector__XXX
 SG_ ESP_a195_ptcStateInvalid m3 : 18|1@1+ (1,0) [0|1] "" Vector__XXX
 SG_ ESP_a196_DIsystemStatusTimeout m3 : 19|1@1+ (1,0) [0|1] "" Vector__XXX
 SG_ ESP_a197_DIsystemStatusDLC m3 : 20|1@1+ (1,0) [0|1] "" Vector__XXX
 SG_ ESP_a198_DIsystemStatusChecksum m3 : 21|1@1+ (1,0) [0|1] "" Vector__XXX
 SG_ ESP_a199_DIsystemStatusCounter m3 : 22|1@1+ (1,0) [0|1] "" Vector__XXX
 SG_ ESP_a200_reverseGearStuckHigh m3 : 23|1@1+ (1,0) [0|1] "" Vector__XXX
 SG_ ESP_a201_reverseGearStuckLow m3 : 24|1@1+ (1,0) [0|1] "" Vector__XXX
 SG_ ESP_a202_accelPedalInvalid m3 : 25|1@1+ (1,0) [0|1] "" Vector__XXX
 SG_ ESP_a203_DItorqueTimeout m3 : 26|1@1+ (1,0) [0|1] "" Vector__XXX
 SG_ ESP_a204_DItorqueDLC m3 : 27|1@1+ (1,0) [0|1] "" Vector__XXX
 SG_ ESP_a205_DItorqueChecksum m3 : 28|1@1+ (1,0) [0|1] "" Vector__XXX
 SG_ ESP_a206_DItorqueCounter m3 : 29|1@1+ (1,0) [0|1] "" Vector__XXX
 SG_ ESP_a207_DITorqueCommandInvalid m3 : 30|1@1+ (1,0) [0|1] "" Vector__XXX
 SG_ ESP_a208_DIRPMInvalid m3 : 31|1@1+ (1,0) [0|1] "" Vector__XXX
 SG_ ESP_a209_DITorqueActualInvalid m3 : 32|1@1+ (1,0) [0|1] "" Vector__XXX
 SG_ ESP_a210_DIStorqueTimeout m3 : 33|1@1+ (1,0) [0|1] "" Vector__XXX
 SG_ ESP_a211_DIStorqueDLC m3 : 34|1@1+ (1,0) [0|1] "" Vector__XXX
 SG_ ESP_a212_DIStorqueChecksum m3 : 35|1@1+ (1,0) [0|1] "" Vector__XXX
 SG_ ESP_a213_DIStorqueCounter m3 : 36|1@1+ (1,0) [0|1] "" Vector__XXX
 SG_ ESP_a214_DISTorqueCommandInvalid m3 : 37|1@1+ (1,0) [0|1] "" Vector__XXX
 SG_ ESP_a215_DISRPMInvalid m3 : 38|1@1+ (1,0) [0|1] "" Vector__XXX
 SG_ ESP_a216_DISTorqueActualInvalid m3 : 39|1@1+ (1,0) [0|1] "" Vector__XXX
 SG_ ESP_a217_DIvdcLeftTimeout m3 : 40|1@1+ (1,0) [0|1] "" Vector__XXX
 SG_ ESP_a218_DIvdcLeftDLC m3 : 41|1@1+ (1,0) [0|1] "" Vector__XXX
 SG_ ESP_a219_DIvdcLeftChecksum m3 : 42|1@1+ (1,0) [0|1] "" Vector__XXX
 SG_ ESP_a220_DIvdcLeftCounter m3 : 43|1@1+ (1,0) [0|1] "" Vector__XXX
 SG_ ESP_a221_DIvdcRightTimeout m3 : 44|1@1+ (1,0) [0|1] "" Vector__XXX
 SG_ ESP_a222_DIvdcRightDLC m3 : 45|1@1+ (1,0) [0|1] "" Vector__XXX
 SG_ ESP_a223_DIvdcRightChecksum m3 : 46|1@1+ (1,0) [0|1] "" Vector__XXX
 SG_ ESP_a224_DIvdcRightCounter m3 : 47|1@1+ (1,0) [0|1] "" Vector__XXX
 SG_ ESP_a225_configMismatch m3 : 48|1@1+ (1,0) [0|1] "" Vector__XXX
 SG_ ESP_a226_bdwRequestInvalid m3 : 49|1@1+ (1,0) [0|1] "" Vector__XXX
 SG_ ESP_a227_bdwRequestActiveInvalid m3 : 50|1@1+ (1,0) [0|1] "" Vector__XXX
 SG_ ESP_a228_GTWvinTimeout m3 : 51|1@1+ (1,0) [0|1] "" Vector__XXX
 SG_ ESP_a229_GTWvinDLC m3 : 52|1@1+ (1,0) [0|1] "" Vector__XXX
 SG_ ESP_a230_vinNotLearned m3 : 53|1@1+ (1,0) [0|1] "" Vector__XXX
 SG_ ESP_a231_storedVINMismatch m3 : 54|1@1+ (1,0) [0|1] "" Vector__XXX
 SG_ ESP_a232_PMstate2Timeout m3 : 55|1@1+ (1,0) [0|1] "" Vector__XXX
 SG_ ESP_a233_PMstate2Checksum m3 : 56|1@1+ (1,0) [0|1] "" Vector__XXX
 SG_ ESP_a234_PMstate2DLC m3 : 57|1@1+ (1,0) [0|1] "" Vector__XXX
 SG_ ESP_a235_PMstate2Counter m3 : 58|1@1+ (1,0) [0|1] "" Vector__XXX
 SG_ ESP_a236_ebrCommandStateInvalid m3 : 59|1@1+ (1,0) [0|1] "" Vector__XXX
 SG_ ESP_a237_vdcCommandStateInvalid m3 : 60|1@1+ (1,0) [0|1] "" Vector__XXX
 SG_ ESP_a238_UIodoTimeout m3 : 61|1@1+ (1,0) [0|1] "" Vector__XXX
 SG_ ESP_a239_UIodoDLC m3 : 62|1@1+ (1,0) [0|1] "" Vector__XXX
 SG_ ESP_a240_LVPowerStateTimeout m3 : 63|1@1+ (1,0) [0|1] "" Vector__XXX
 SG_ ESP_a241_LVPowerStateChecksum m4 : 4|1@1+ (1,0) [0|1] "" Vector__XXX
 SG_ ESP_a242_LVPowerStateDLC m4 : 5|1@1+ (1,0) [0|1] "" Vector__XXX
 SG_ ESP_a243_LVPowerStateCounter m4 : 6|1@1+ (1,0) [0|1] "" Vector__XXX
 SG_ ESP_a244_LVOffStateInvalid m4 : 7|1@1+ (1,0) [0|1] "" Vector__XXX
 SG_ ESP_a245_LVGoingDownStateInvalid m4 : 8|1@1+ (1,0) [0|1] "" Vector__XXX
 SG_ ESP_a246_VCFRONTsensorTimeout m4 : 9|1@1+ (1,0) [0|1] "" Vector__XXX
 SG_ ESP_a247_VCFRONTsensorDLC m4 : 10|1@1+ (1,0) [0|1] "" Vector__XXX
 SG_ ESP_a248_vdcBrkeTrqTarFrLInvalid m4 : 11|1@1+ (1,0) [0|1] "" Vector__XXX
 SG_ ESP_a249_vdcBrkeTrqTarFrRInvalid m4 : 12|1@1+ (1,0) [0|1] "" Vector__XXX
 SG_ ESP_a250_vdcBrkeTrqTarReLInvalid m4 : 13|1@1+ (1,0) [0|1] "" Vector__XXX
 SG_ ESP_a251_vdcBrkeTrqTarReRInvalid m4 : 14|1@1+ (1,0) [0|1] "" Vector__XXX
 SG_ ESP_a252_vdcWhlSlipLimFrLInvalid m4 : 15|1@1+ (1,0) [0|1] "" Vector__XXX
 SG_ ESP_a253_vdcWhlSlipLimFrRInvalid m4 : 16|1@1+ (1,0) [0|1] "" Vector__XXX
 SG_ ESP_a254_vdcWhlSlipLimReLInvalid m4 : 17|1@1+ (1,0) [0|1] "" Vector__XXX
 SG_ ESP_a255_vdcWhlSlipLimReRInvalid m4 : 18|1@1+ (1,0) [0|1] "" Vector__XXX
 SG_ ESP_a256_epbmStatusTimeout m4 : 19|1@1+ (1,0) [0|1] "" Vector__XXX
 SG_ ESP_a257_epbmStatusChecksum m4 : 20|1@1+ (1,0) [0|1] "" Vector__XXX
 SG_ ESP_a258_epbmStatusDLC m4 : 21|1@1+ (1,0) [0|1] "" Vector__XXX
 SG_ ESP_a259_epbmStatusCounter m4 : 22|1@1+ (1,0) [0|1] "" Vector__XXX
 SG_ ESP_a260_epblStatusTimeout m4 : 23|1@1+ (1,0) [0|1] "" Vector__XXX
 SG_ ESP_a261_epblStatusChecksum m4 : 24|1@1+ (1,0) [0|1] "" Vector__XXX
 SG_ ESP_a262_epblStatusDLC m4 : 25|1@1+ (1,0) [0|1] "" Vector__XXX
 SG_ ESP_a263_epblStatusCounter m4 : 26|1@1+ (1,0) [0|1] "" Vector__XXX
 SG_ ESP_a264_pumpSpeedLimitInvalid m4 : 27|1@1+ (1,0) [0|1] "" Vector__XXX
 SG_ ESP_a265_DIRELtorqueTimeout m4 : 28|1@1+ (1,0) [0|1] "" Vector__XXX
 SG_ ESP_a266_DIRELtorqueDLC m4 : 29|1@1+ (1,0) [0|1] "" Vector__XXX
 SG_ ESP_a267_DIRELtorqueChecksum m4 : 30|1@1+ (1,0) [0|1] "" Vector__XXX
 SG_ ESP_a268_DIRELtorqueCounter m4 : 31|1@1+ (1,0) [0|1] "" Vector__XXX
 SG_ ESP_a269_DIRELTorqueCommandInval m4 : 32|1@1+ (1,0) [0|1] "" Vector__XXX
 SG_ ESP_a270_DIRELRPMInvalid m4 : 33|1@1+ (1,0) [0|1] "" Vector__XXX
 SG_ ESP_a271_DIRELTorqueActualInvali m4 : 34|1@1+ (1,0) [0|1] "" Vector__XXX
 SG_ ESP_a272_DIRERtorqueTimeout m4 : 35|1@1+ (1,0) [0|1] "" Vector__XXX
 SG_ ESP_a273_DIRERtorqueDLC m4 : 36|1@1+ (1,0) [0|1] "" Vector__XXX
 SG_ ESP_a274_DIRERtorqueChecksum m4 : 37|1@1+ (1,0) [0|1] "" Vector__XXX
 SG_ ESP_a275_DIRERtorqueCounter m4 : 38|1@1+ (1,0) [0|1] "" Vector__XXX
 SG_ ESP_a276_DIRERTorqueCommandInval m4 : 39|1@1+ (1,0) [0|1] "" Vector__XXX
 SG_ ESP_a277_DIRERRPMInvalid m4 : 40|1@1+ (1,0) [0|1] "" Vector__XXX
 SG_ ESP_a278_DIRERTorqueActualInvali m4 : 41|1@1+ (1,0) [0|1] "" Vector__XXX
 SG_ ESP_a279_lifetimeManagementOverr m4 : 42|1@1+ (1,0) [0|1] "" Vector__XXX
 SG_ ESP_a280_trackModeABSEnabled m4 : 43|1@1+ (1,0) [0|1] "" Vector__XXX
 SG_ ESP_a281_trackModeABSdisabled m4 : 44|1@1+ (1,0) [0|1] "" Vector__XXX
 SG_ ESP_a282_trackModeABSRequestInva m4 : 45|1@1+ (1,0) [0|1] "" Vector__XXX
 SG_ ESP_a283_secondaryCollisionMitig m4 : 46|1@1+ (1,0) [0|1] "" Vector__XXX
 SG_ ESP_a284_scmRequestInvalidChecks m4 : 47|1@1+ (1,0) [0|1] "" Vector__XXX
 SG_ ESP_a285_scmRequestDLC m4 : 48|1@1+ (1,0) [0|1] "" Vector__XXX
 SG_ ESP_a286_hydroplaneDetected m4 : 49|1@1+ (1,0) [0|1] "" Vector__XXX
 SG_ ESP_a287_failedBrakeCircuitDetec m4 : 50|1@1+ (1,0) [0|1] "" Vector__XXX
 SG_ ESP_a288_leftBusOff m4 : 51|1@1+ (1,0) [0|1] "" Vector__XXX
 SG_ ESP_a289_leftBusPassive m4 : 52|1@1+ (1,0) [0|1] "" Vector__XXX
 SG_ ESP_a290_brakeBusOff m4 : 53|1@1+ (1,0) [0|1] "" Vector__XXX
 SG_ ESP_a291_brakeBusPassive m4 : 54|1@1+ (1,0) [0|1] "" Vector__XXX
 SG_ ESP_a292_PEPSstatusTimeout m4 : 55|1@1+ (1,0) [0|1] "" Vector__XXX
 SG_ ESP_a293_PEPSstatusDLC m4 : 56|1@1+ (1,0) [0|1] "" Vector__XXX
 SG_ ESP_a294_PEPSstatusChecksum m4 : 57|1@1+ (1,0) [0|1] "" Vector__XXX
 SG_ ESP_a295_PEPSstatusCounter m4 : 58|1@1+ (1,0) [0|1] "" Vector__XXX
 SG_ ESP_a296_roadWheelAngleHealthDeg m4 : 59|1@1+ (1,0) [0|1] "" Vector__XXX
 SG_ ESP_a297_roadWheelAngleHealthFau m4 : 60|1@1+ (1,0) [0|1] "" Vector__XXX
 SG_ ESP_a298_RSArearSteerStatusTimeo m4 : 61|1@1+ (1,0) [0|1] "" Vector__XXX
 SG_ ESP_a299_RSArearSteerStatusDLC m4 : 62|1@1+ (1,0) [0|1] "" Vector__XXX
 SG_ ESP_a300_RSArearSteerStatusCheck m4 : 63|1@1+ (1,0) [0|1] "" Vector__XXX
 SG_ ESP_a301_PEPSstatusCounter m5 : 4|1@1+ (1,0) [0|1] "" Vector__XXX
 SG_ ESP_a302_rearRoadWheelAngleHealt m5 : 5|1@1+ (1,0) [0|1] "" Vector__XXX
 SG_ ESP_a303_rearRoadWheelAngleHealt m5 : 6|1@1+ (1,0) [0|1] "" Vector__XXX
 SG_ ESP_a304_rearVCLVPowerStateTimeo m5 : 7|1@1+ (1,0) [0|1] "" Vector__XXX
 SG_ ESP_a305_rearVCLVPowerStateDLC m5 : 8|1@1+ (1,0) [0|1] "" Vector__XXX
 SG_ ESP_a306_rearVCLVPowerStateCheck m5 : 9|1@1+ (1,0) [0|1] "" Vector__XXX
 SG_ ESP_a307_rearVCLVPowerStateCount m5 : 10|1@1+ (1,0) [0|1] "" Vector__XXX
 SG_ ESP_a308_evacFillNotComplete m5 : 11|1@1+ (1,0) [0|1] "" Vector__XXX
 SG_ ESP_a309_factoryModeActive m5 : 12|1@1+ (1,0) [0|1] "" Vector__XXX
 SG_ ESP_a310_brakeLatencyReductionAc m5 : 13|1@1+ (1,0) [0|1] "" Vector__XXX
 SG_ ESP_a311_aesActive m5 : 14|1@1+ (1,0) [0|1] "" Vector__XXX
 SG_ ESP_a312_undefinedAlertDetected m5 : 15|1@1+ (1,0) [0|1] "" Vector__XXX
 SG_ ESP_a313_cdpRequestStateInvalid m5 : 16|1@1+ (1,0) [0|1] "" Vector__XXX
 SG_ ESP_a314_aesFault m5 : 17|1@1+ (1,0) [0|1] "" Vector__XXX
 SG_ ESP_a315_EMCBackup11Timeout m5 : 18|1@1+ (1,0) [0|1] "" Vector__XXX
 SG_ ESP_a316_EMCBackup11DLC m5 : 19|1@1+ (1,0) [0|1] "" Vector__XXX
 SG_ ESP_a317_EMCBackup11Checksum m5 : 20|1@1+ (1,0) [0|1] "" Vector__XXX
 SG_ ESP_a318_EMCBackup11Counter m5 : 21|1@1+ (1,0) [0|1] "" Vector__XXX
 SG_ ESP_a319_AES_BackupActuatorActiv m5 : 22|1@1+ (1,0) [0|1] "" Vector__XXX
 SG_ ESP_a320_DPB_actuator1Counter m5 : 23|1@1+ (1,0) [0|1] "" Vector__XXX
 SG_ ESP_a321_DPB_actuator1Checksum m5 : 24|1@1+ (1,0) [0|1] "" Vector__XXX
 SG_ ESP_a322_DPB_actuator1DLC m5 : 25|1@1+ (1,0) [0|1] "" Vector__XXX
 SG_ ESP_a323_DPB_actuator1Timeout m5 : 26|1@1+ (1,0) [0|1] "" Vector__XXX
 SG_ ESP_a324_DPB_actuator2Counter m5 : 27|1@1+ (1,0) [0|1] "" Vector__XXX
 SG_ ESP_a325_DPB_actuator2Checksum m5 : 28|1@1+ (1,0) [0|1] "" Vector__XXX
 SG_ ESP_a326_DPB_actuator2DLC m5 : 29|1@1+ (1,0) [0|1] "" Vector__XXX
 SG_ ESP_a327_DPB_actuator2Timeout m5 : 30|1@1+ (1,0) [0|1] "" Vector__XXX
 SG_ ESP_a328_DPB_actuator3Counter m5 : 31|1@1+ (1,0) [0|1] "" Vector__XXX
 SG_ ESP_a329_DPB_actuator3Checksum m5 : 32|1@1+ (1,0) [0|1] "" Vector__XXX
 SG_ ESP_a330_DPB_actuator3DLC m5 : 33|1@1+ (1,0) [0|1] "" Vector__XXX
 SG_ ESP_a331_DPB_actuator3Timeout m5 : 34|1@1+ (1,0) [0|1] "" Vector__XXX
 SG_ ESP_a332_PressureSensorValHigh m5 : 35|1@1+ (1,0) [0|1] "" Vector__XXX
 SG_ ESP_a333_ActCircuitNoPressure m5 : 36|1@1+ (1,0) [0|1] "" Vector__XXX
 SG_ ESP_a334_BrakePedalAppliedInvali m5 : 37|1@1+ (1,0) [0|1] "" Vector__XXX
 SG_ ESP_a335_LdmFxTarBrakeActInvalid m5 : 38|1@1+ (1,0) [0|1] "" Vector__XXX
 SG_ ESP_a336_FxTargetDriverInvalid m5 : 39|1@1+ (1,0) [0|1] "" Vector__XXX
 SG_ ESP_a337_pReductionPotentialInva m5 : 40|1@1+ (1,0) [0|1] "" Vector__XXX
 SG_ ESP_a338_pRunoutInvalid m5 : 41|1@1+ (1,0) [0|1] "" Vector__XXX
 SG_ ESP_a339_sInputRodInvalid m5 : 42|1@1+ (1,0) [0|1] "" Vector__XXX
 SG_ ESP_a340_RollerBenchMisuse m5 : 43|1@1+ (1,0) [0|1] "" Vector__XXX
 SG_ ESP_a341_EnhancedPressureBuildAc m5 : 44|1@1+ (1,0) [0|1] "" Vector__XXX
 SG_ ESP_a342_EnhancedPressureBuildNo m5 : 45|1@1+ (1,0) [0|1] "" Vector__XXX
 SG_ ESP_a343_EnhancedPressureBuildLt m5 : 46|1@1+ (1,0) [0|1] "" Vector__XXX
 SG_ ESP_a344_DIbrakeCommandCounter m5 : 47|1@1+ (1,0) [0|1] "" Vector__XXX
 SG_ ESP_a345_DIbrakeCommandChecksum m5 : 48|1@1+ (1,0) [0|1] "" Vector__XXX
 SG_ ESP_a346_DIbrakeCommandDLC m5 : 49|1@1+ (1,0) [0|1] "" Vector__XXX
 SG_ ESP_a347_DIbrakeCommandTimeout m5 : 50|1@1+ (1,0) [0|1] "" Vector__XXX
 SG_ ESP_a348_brakeCmdStateInvalid m5 : 51|1@1+ (1,0) [0|1] "" Vector__XXX
 SG_ ESP_a349_ForceLampToRed m5 : 52|1@1+ (1,0) [0|1] "" Vector__XXX
 SG_ ESP_a350_ActuatorOff m5 : 53|1@1+ (1,0) [0|1] "" Vector__XXX
 SG_ ESP_a351_ActuatorYellowLampReque m5 : 54|1@1+ (1,0) [0|1] "" Vector__XXX
 SG_ ESP_a352_ActuatorLDMFailure m5 : 55|1@1+ (1,0) [0|1] "" Vector__XXX
 SG_ ESP_a353_PressureSensorImplausHi m5 : 56|1@1+ (1,0) [0|1] "" Vector__XXX
 SG_ ESP_a354_HBCRequestInvalid m5 : 57|1@1+ (1,0) [0|1] "" Vector__XXX
 SG_ ESP_a355_RecuStatusActInvalid m5 : 58|1@1+ (1,0) [0|1] "" Vector__XXX
 SG_ ESP_a356_DIFAxleTorqueInvalid m5 : 59|1@1+ (1,0) [0|1] "" Vector__XXX
 SG_ ESP_a357_DIRAxleTorqueInvalid m5 : 60|1@1+ (1,0) [0|1] "" Vector__XXX
 SG_ ESP_a358_externalActuatorFallbac m5 : 61|1@1+ (1,0) [0|1] "" Vector__XXX
 SG_ ESP_a359_externalActuatorNoExtRe m5 : 62|1@1+ (1,0) [0|1] "" Vector__XXX
 SG_ ESP_a360_BBbrakeActuationTimeout m5 : 63|1@1+ (1,0) [0|1] "" Vector__XXX
 SG_ ESP_a361_BBbrakeActuationDLC m6 : 4|1@1+ (1,0) [0|1] "" Vector__XXX
 SG_ ESP_a362_BBbrakeActuationChecksu m6 : 5|1@1+ (1,0) [0|1] "" Vector__XXX
 SG_ ESP_a363_BBbrakeActuationCounter m6 : 6|1@1+ (1,0) [0|1] "" Vector__XXX
 SG_ ESP_a364_DIgearInvalid m6 : 7|1@1+ (1,0) [0|1] "" Vector__XXX
 SG_ ESP_a365_TCSInputQualityTooLow m6 : 8|1@1+ (1,0) [0|1] "" Vector__XXX
 SG_ ESP_a366_ActuatorBlendingModeReq m6 : 9|1@1+ (1,0) [0|1] "" Vector__XXX
 SG_ ESP_a367_CBDS_fillBufferThreshol m6 : 10|1@1+ (1,0) [0|1] "" Vector__XXX
 SG_ ESP_a368_CBDS_fmeInternalEvent m6 : 11|1@1+ (1,0) [0|1] "" Vector__XXX
 SG_ ESP_a369_LargeLeakageDetectedByD m6 : 12|1@1+ (1,0) [0|1] "" Vector__XXX
 SG_ ESP_a370_DPB_actuator4Timeout m6 : 13|1@1+ (1,0) [0|1] "" Vector__XXX
 SG_ ESP_a371_DPB_actuator4DLC m6 : 14|1@1+ (1,0) [0|1] "" Vector__XXX
 SG_ ESP_a372_DPB_actuator4Checksum m6 : 15|1@1+ (1,0) [0|1] "" Vector__XXX
 SG_ ESP_a373_DPB_actuator4Counter m6 : 16|1@1+ (1,0) [0|1] "" Vector__XXX
 SG_ ESP_a374_StatInvalid_DI_FullSNA m6 : 17|1@1+ (1,0) [0|1] "" Vector__XXX
 SG_ ESP_a375_PM_locStateCounter m6 : 18|1@1+ (1,0) [0|1] "" Vector__XXX
 SG_ ESP_a376_PM_locStateChecksum m6 : 19|1@1+ (1,0) [0|1] "" Vector__XXX
 SG_ ESP_a377_PM_locStateDLC m6 : 20|1@1+ (1,0) [0|1] "" Vector__XXX
 SG_ ESP_a378_PM_locStateTimeout m6 : 21|1@1+ (1,0) [0|1] "" Vector__XXX
 SG_ ESP_a379_DASredundantBrakingCont m6 : 22|1@1+ (1,0) [0|1] "" Vector__XXX
 SG_ ESP_a380_DASredundantBrakingCont m6 : 23|1@1+ (1,0) [0|1] "" Vector__XXX
 SG_ ESP_a381_DASredundantBrakingCont m6 : 24|1@1+ (1,0) [0|1] "" Vector__XXX
 SG_ ESP_a382_DASredundantBrakingCont m6 : 25|1@1+ (1,0) [0|1] "" Vector__XXX
 SG_ ESP_a383_DASredundantBrakingCont m6 : 26|1@1+ (1,0) [0|1] "" Vector__XXX
 SG_ ESP_a384_DASredundantBrakingCont m6 : 27|1@1+ (1,0) [0|1] "" Vector__XXX
 SG_ ESP_a385_DASredundantBrakingCont m6 : 28|1@1+ (1,0) [0|1] "" Vector__XXX
 SG_ ESP_a386_DASredundantBrakingCont m6 : 29|1@1+ (1,0) [0|1] "" Vector__XXX
 SG_ ESP_a387_DIlocStatus2Checksum m6 : 30|1@1+ (1,0) [0|1] "" Vector__XXX
 SG_ ESP_a388_DIlocStatus2Counter m6 : 31|1@1+ (1,0) [0|1] "" Vector__XXX
 SG_ ESP_a389_DIlocStatus2DLC m6 : 32|1@1+ (1,0) [0|1] "" Vector__XXX
 SG_ ESP_a390_DIlocStatus2Timeout m6 : 33|1@1+ (1,0) [0|1] "" Vector__XXX
 SG_ ESP_a391_standaloneEBRActive m6 : 34|1@1+ (1,0) [0|1] "" Vector__XXX
 SG_ ESP_a392_driverlessArmingUnavail m6 : 35|1@1+ (1,0) [0|1] "" Vector__XXX
 SG_ ESP_a393_EMCBackup21Checksum m6 : 36|1@1+ (1,0) [0|1] "" Vector__XXX
 SG_ ESP_a394_EMCBackup21Counter m6 : 37|1@1+ (1,0) [0|1] "" Vector__XXX
 SG_ ESP_a395_EMCBackup21DLC m6 : 38|1@1+ (1,0) [0|1] "" Vector__XXX
 SG_ ESP_a396_EMCBackup21Timeout m6 : 39|1@1+ (1,0) [0|1] "" Vector__XXX
 SG_ ESP_a397_epbrStatusTimeout m6 : 40|1@1+ (1,0) [0|1] "" Vector__XXX
 SG_ ESP_a398_epbrStatusChecksum m6 : 41|1@1+ (1,0) [0|1] "" Vector__XXX
 SG_ ESP_a399_epbrStatusDLC m6 : 42|1@1+ (1,0) [0|1] "" Vector__XXX
 SG_ ESP_a400_epbrStatusCounter m6 : 43|1@1+ (1,0) [0|1] "" Vector__XXX
 SG_ ESP_a401_bsmCircuitFailure m6 : 44|1@1+ (1,0) [0|1] "" Vector__XXX
 SG_ ESP_a402_bsmPtsPlausToPsTooHigh m6 : 45|1@1+ (1,0) [0|1] "" Vector__XXX
 SG_ ESP_a403_batMotorVoltage m6 : 46|1@1+ (1,0) [0|1] "" Vector__XXX
 SG_ ESP_a404_batPressureCircuit1 m6 : 47|1@1+ (1,0) [0|1] "" Vector__XXX
 SG_ ESP_a405_batPressureCircuit2 m6 : 48|1@1+ (1,0) [0|1] "" Vector__XXX
 SG_ ESP_a406_DIespActuatorTestTimeou m6 : 49|1@1+ (1,0) [0|1] "" Vector__XXX
 SG_ ESP_a407_DIespActuatorTestChecks m6 : 50|1@1+ (1,0) [0|1] "" Vector__XXX
 SG_ ESP_a408_DIespActuatorTestDLC m6 : 51|1@1+ (1,0) [0|1] "" Vector__XXX
 SG_ ESP_a409_DIespActuatorTestCounte m6 : 52|1@1+ (1,0) [0|1] "" Vector__XXX

BO_ 805 ESP_info: 8 ESP
 SG_ ESP_infoIndex M : 0|8@1+ (1,0) [0|255] "" Vector__XXX
 SG_ ESP_infoBuildType m10 : 8|8@1+ (1,0) [0|255] "" Vector__XXX
 SG_ ESP_vehFlashMode m10 : 24|1@1+ (1,0) [0|1] "" Vector__XXX
 SG_ ESP_infoComponentID m10 : 48|16@1+ (1,0) [0|65535] "" Vector__XXX
 SG_ ESP_infoPcbaID m11 : 16|8@1+ (1,0) [0|255] "" Vector__XXX
 SG_ ESP_infoAssemblyID m11 : 24|8@1+ (1,0) [0|255] "" Vector__XXX
 SG_ ESP_infoUsageID m11 : 32|16@1+ (1,0) [0|65535] "" Vector__XXX
 SG_ ESP_infoSubUsageID m11 : 48|16@1+ (1,0) [0|65535] "" Vector__XXX
 SG_ ESP_infoApplicationCRC m13 : 39|32@0+ (1,0) [0|4294967295] "" Vector__XXX
 SG_ ESP_infoVehicleVariant m16 : 16|8@1+ (1,0) [0|255] "" Vector__XXX
 SG_ ESP_infoSubcomponent1 m16 : 32|32@1+ (1,0) [0|4294967295] "" Vector__XXX
 SG_ ESP_infoBootUdsProtoVersion m20 : 8|8@1+ (1,0) [0|255] "" Vector__XXX
 SG_ ESP_infoBootloaderCRC m20 : 32|32@1+ (1,0) [0|4294967295] "" Vector__XXX
 SG_ ESP_infoVariantCRC m22 : 39|32@0+ (1,0) [0|4294967295] "" Vector__XXX

BO_ 1621 ESP_udsResponse: 8 ESP
 SG_ ESP_udsResponseData : 7|64@0+ (1,0) [0|1.84467440737e+19] "" Vector__XXX

BO_ 861 IBST_alertMatrix: 8 IBST
 SG_ IBST_matrixIndex M : 0|4@1+ (1,0) [0|15] "" Vector__XXX
 SG_ IBST_a001_microSupplyError m0 : 4|1@1+ (1,0) [0|1] "" Vector__XXX
 SG_ IBST_a002_HWBISTError m0 : 5|1@1+ (1,0) [0|1] "" Vector__XXX
 SG_ IBST_a003_RAMFault m0 : 6|1@1+ (1,0) [0|1] "" Vector__XXX
 SG_ IBST_a004_flashFault m0 : 7|1@1+ (1,0) [0|1] "" Vector__XXX
 SG_ IBST_a005_microSafetyFault m0 : 8|1@1+ (1,0) [0|1] "" Vector__XXX
 SG_ IBST_a006_microSafetyLogicFault m0 : 9|1@1+ (1,0) [0|1] "" Vector__XXX
 SG_ IBST_a007_RBCPUException m0 : 10|1@1+ (1,0) [0|1] "" Vector__XXX
 SG_ IBST_a008_stackOverUnderFlow m0 : 11|1@1+ (1,0) [0|1] "" Vector__XXX
 SG_ IBST_a009_systemErrorHook m0 : 12|1@1+ (1,0) [0|1] "" Vector__XXX
 SG_ IBST_a010_OSErrorHook m0 : 13|1@1+ (1,0) [0|1] "" Vector__XXX
 SG_ IBST_a011_systemTaskOverRun m0 : 14|1@1+ (1,0) [0|1] "" Vector__XXX
 SG_ IBST_a012_OSTaskSchemeError m0 : 15|1@1+ (1,0) [0|1] "" Vector__XXX
 SG_ IBST_a013_systemTaskJitter m0 : 16|1@1+ (1,0) [0|1] "" Vector__XXX
 SG_ IBST_a014_DMATransferError m0 : 17|1@1+ (1,0) [0|1] "" Vector__XXX
 SG_ IBST_a015_asicOscillatorError m0 : 18|1@1+ (1,0) [0|1] "" Vector__XXX
 SG_ IBST_a016_RBBLMShaftShiftError m0 : 19|1@1+ (1,0) [0|1] "" Vector__XXX
 SG_ IBST_a017_assertionFault m0 : 20|1@1+ (1,0) [0|1] "" Vector__XXX
 SG_ IBST_a018_unsupportedHW m0 : 21|1@1+ (1,0) [0|1] "" Vector__XXX
 SG_ IBST_a019_supplyASICInitFault m0 : 22|1@1+ (1,0) [0|1] "" Vector__XXX
 SG_ IBST_a020_VPREU5VOutOfRange m0 : 23|1@1+ (1,0) [0|1] "" Vector__XXX
 SG_ IBST_a021_IREFOutOfRange m0 : 24|1@1+ (1,0) [0|1] "" Vector__XXX
 SG_ IBST_a022_U5VTestFault m0 : 25|1@1+ (1,0) [0|1] "" Vector__XXX
 SG_ IBST_a023_U5VOutOfRange m0 : 26|1@1+ (1,0) [0|1] "" Vector__XXX
 SG_ IBST_a024_chargePumpFault m0 : 27|1@1+ (1,0) [0|1] "" Vector__XXX
 SG_ IBST_a025_ecuClockTestFault m0 : 28|1@1+ (1,0) [0|1] "" Vector__XXX
 SG_ IBST_a026_ecuBistCmdTestFault m0 : 29|1@1+ (1,0) [0|1] "" Vector__XXX
 SG_ IBST_a027_ecuFastWdTestFault m0 : 30|1@1+ (1,0) [0|1] "" Vector__XXX
 SG_ IBST_a028_ecuBistFaultCtrFault m0 : 31|1@1+ (1,0) [0|1] "" Vector__XXX
 SG_ IBST_a029_ecuErrpinCounterFault m0 : 32|1@1+ (1,0) [0|1] "" Vector__XXX
 SG_ IBST_a030_ecuEnableElLowFault m0 : 33|1@1+ (1,0) [0|1] "" Vector__XXX
 SG_ IBST_a031_decoupleBitTestFault m0 : 34|1@1+ (1,0) [0|1] "" Vector__XXX
 SG_ IBST_a032_ecuEnableElHighFault m0 : 35|1@1+ (1,0) [0|1] "" Vector__XXX
 SG_ IBST_a033_ecuWdStartuptestFault m0 : 36|1@1+ (1,0) [0|1] "" Vector__XXX
 SG_ IBST_a034_ecuEnableHyHighFault m0 : 37|1@1+ (1,0) [0|1] "" Vector__XXX
 SG_ IBST_a035_ecuEnableHyLowFault m0 : 38|1@1+ (1,0) [0|1] "" Vector__XXX
 SG_ IBST_a036_MRGPathTestFault m0 : 39|1@1+ (1,0) [0|1] "" Vector__XXX
 SG_ IBST_a037_ecuWdSContinuousError m0 : 40|1@1+ (1,0) [0|1] "" Vector__XXX
 SG_ IBST_a038_ecuEnContinuousError m0 : 41|1@1+ (1,0) [0|1] "" Vector__XXX
 SG_ IBST_a039_GTMRefFrequencyError m0 : 42|1@1+ (1,0) [0|1] "" Vector__XXX
 SG_ IBST_a040_GTMTbuMonError m0 : 43|1@1+ (1,0) [0|1] "" Vector__XXX
 SG_ IBST_a041_micAsicClkInError m0 : 44|1@1+ (1,0) [0|1] "" Vector__XXX
 SG_ IBST_a042_micAsicInitTestError m0 : 45|1@1+ (1,0) [0|1] "" Vector__XXX
 SG_ IBST_a043_micSpiTransferError m0 : 46|1@1+ (1,0) [0|1] "" Vector__XXX
 SG_ IBST_a044_NvMEepromWIP m0 : 47|1@1+ (1,0) [0|1] "" Vector__XXX
 SG_ IBST_a045_WdhAsicWdErrorCntStuck m0 : 48|1@1+ (1,0) [0|1] "" Vector__XXX
 SG_ IBST_a046_WdhAsicWdErrorCntLimit m0 : 49|1@1+ (1,0) [0|1] "" Vector__XXX
 SG_ IBST_a047_WdhAsicWdCmdMissing m0 : 50|1@1+ (1,0) [0|1] "" Vector__XXX
 SG_ IBST_a048_WdhSwBistConCnt m0 : 51|1@1+ (1,0) [0|1] "" Vector__XXX
 SG_ IBST_a049_WdhTaskMonConCnt m0 : 52|1@1+ (1,0) [0|1] "" Vector__XXX
 SG_ IBST_a050_VPreExternalFeeding m0 : 53|1@1+ (1,0) [0|1] "" Vector__XXX
 SG_ IBST_a051_ecuBandgap m0 : 54|1@1+ (1,0) [0|1] "" Vector__XXX
 SG_ IBST_a052_AdcPinTest m0 : 55|1@1+ (1,0) [0|1] "" Vector__XXX
 SG_ IBST_a053_AdcSelftestC5P m0 : 56|1@1+ (1,0) [0|1] "" Vector__XXX
 SG_ IBST_a054_AdcPeripheralFault m0 : 57|1@1+ (1,0) [0|1] "" Vector__XXX
 SG_ IBST_a055_UB6SupplyPathFault m0 : 58|1@1+ (1,0) [0|1] "" Vector__XXX
 SG_ IBST_a056_UB6PlausiMonFault m0 : 59|1@1+ (1,0) [0|1] "" Vector__XXX
 SG_ IBST_a057_microRegisterFault m0 : 60|1@1+ (1,0) [0|1] "" Vector__XXX
 SG_ IBST_a058_NvMWriteCycleExceed m0 : 61|1@1+ (1,0) [0|1] "" Vector__XXX
 SG_ IBST_a059_NvMEepromSize m0 : 62|1@1+ (1,0) [0|1] "" Vector__XXX
 SG_ IBST_a060_NvMMigrationFault m0 : 63|1@1+ (1,0) [0|1] "" Vector__XXX
 SG_ IBST_a061_AswSystemTimeOut m1 : 4|1@1+ (1,0) [0|1] "" Vector__XXX
 SG_ IBST_a062_MICB6TransferError m1 : 5|1@1+ (1,0) [0|1] "" Vector__XXX
 SG_ IBST_a063_tempSens2ShortToSupply m1 : 6|1@1+ (1,0) [0|1] "" Vector__XXX
 SG_ IBST_a064_tempSens1ShortToGround m1 : 7|1@1+ (1,0) [0|1] "" Vector__XXX
 SG_ IBST_a065_tempSens2ShortToGround m1 : 8|1@1+ (1,0) [0|1] "" Vector__XXX
 SG_ IBST_a066_tempSens1ShortToSupply m1 : 9|1@1+ (1,0) [0|1] "" Vector__XXX
 SG_ IBST_a067_tempSensImplausVoltage m1 : 10|1@1+ (1,0) [0|1] "" Vector__XXX
 SG_ IBST_a068_chargePumpUndervoltage m1 : 11|1@1+ (1,0) [0|1] "" Vector__XXX
 SG_ IBST_a069_greasingRoutineFault m1 : 12|1@1+ (1,0) [0|1] "" Vector__XXX
 SG_ IBST_a070_notShutDownNvMWrite m1 : 13|1@1+ (1,0) [0|1] "" Vector__XXX
 SG_ IBST_a071_notShutDownNvMRead m1 : 14|1@1+ (1,0) [0|1] "" Vector__XXX
 SG_ IBST_a072_notShutDownRight m1 : 15|1@1+ (1,0) [0|1] "" Vector__XXX
 SG_ IBST_a073_jumpInAdjustNvMRead m1 : 16|1@1+ (1,0) [0|1] "" Vector__XXX
 SG_ IBST_a074_FindIdleDataNvMWrite m1 : 17|1@1+ (1,0) [0|1] "" Vector__XXX
 SG_ IBST_a075_FindIdleRoutineFault m1 : 18|1@1+ (1,0) [0|1] "" Vector__XXX
 SG_ IBST_a076_masterCylLengthRead m1 : 19|1@1+ (1,0) [0|1] "" Vector__XXX
 SG_ IBST_a077_runOutMotorSaturated m1 : 20|1@1+ (1,0) [0|1] "" Vector__XXX
 SG_ IBST_a078_wearOffsetCompNVMRead m1 : 21|1@1+ (1,0) [0|1] "" Vector__XXX
 SG_ IBST_a079_motorTempHighLevel1 m1 : 22|1@1+ (1,0) [0|1] "" Vector__XXX
 SG_ IBST_a080_motorTempHighLevel2 m1 : 23|1@1+ (1,0) [0|1] "" Vector__XXX
 SG_ IBST_a081_travelDeviation m1 : 24|1@1+ (1,0) [0|1] "" Vector__XXX
 SG_ IBST_a082_motorSpeedDeviation m1 : 25|1@1+ (1,0) [0|1] "" Vector__XXX
 SG_ IBST_a083_spindlePositionTooHigh m1 : 26|1@1+ (1,0) [0|1] "" Vector__XXX
 SG_ IBST_a084_CANTransceiverHWFault m1 : 27|1@1+ (1,0) [0|1] "" Vector__XXX
 SG_ IBST_a085_supplyUndervoltageLvl3 m1 : 28|1@1+ (1,0) [0|1] "" Vector__XXX
 SG_ IBST_a086_supplyOvervoltageLvl3 m1 : 29|1@1+ (1,0) [0|1] "" Vector__XXX
 SG_ IBST_a087_rotorSinOutOfRangeLow m1 : 30|1@1+ (1,0) [0|1] "" Vector__XXX
 SG_ IBST_a088_rotorCosOutOfRangeLow m1 : 31|1@1+ (1,0) [0|1] "" Vector__XXX
 SG_ IBST_a089_rotorSinOutOfRangeHigh m1 : 32|1@1+ (1,0) [0|1] "" Vector__XXX
 SG_ IBST_a090_rotorCosOutOfRangeHigh m1 : 33|1@1+ (1,0) [0|1] "" Vector__XXX
 SG_ IBST_a091_SMMOneRequestsInit m1 : 34|1@1+ (1,0) [0|1] "" Vector__XXX
 SG_ IBST_a092_systemStartTimeOut m1 : 35|1@1+ (1,0) [0|1] "" Vector__XXX
 SG_ IBST_a093_UEXSOvertemperature m1 : 36|1@1+ (1,0) [0|1] "" Vector__XXX
 SG_ IBST_a094_XPASSEchoTimeDeviation m1 : 37|1@1+ (1,0) [0|1] "" Vector__XXX
 SG_ IBST_a095_XPASSTimeOut m1 : 38|1@1+ (1,0) [0|1] "" Vector__XXX
 SG_ IBST_a096_bridgeDriverMonError m1 : 39|1@1+ (1,0) [0|1] "" Vector__XXX
 SG_ IBST_a097_bridgeDriverError m1 : 40|1@1+ (1,0) [0|1] "" Vector__XXX
 SG_ IBST_a098_bridgeShortedPhase m1 : 41|1@1+ (1,0) [0|1] "" Vector__XXX
 SG_ IBST_a099_bridgeSwitchInitError m1 : 42|1@1+ (1,0) [0|1] "" Vector__XXX
 SG_ IBST_a100_current2OffsetHigh m1 : 43|1@1+ (1,0) [0|1] "" Vector__XXX
 SG_ IBST_a101_current2OffsetLow m1 : 44|1@1+ (1,0) [0|1] "" Vector__XXX
 SG_ IBST_a102_current1OffsetHigh m1 : 45|1@1+ (1,0) [0|1] "" Vector__XXX
 SG_ IBST_a103_current1OffsetLow m1 : 46|1@1+ (1,0) [0|1] "" Vector__XXX
 SG_ IBST_a104_bridgeDriverShort m1 : 47|1@1+ (1,0) [0|1] "" Vector__XXX
 SG_ IBST_a105_LiPSUndervoltage m1 : 48|1@1+ (1,0) [0|1] "" Vector__XXX
 SG_ IBST_a106_LiPS5VSupply m1 : 49|1@1+ (1,0) [0|1] "" Vector__XXX
 SG_ IBST_a107_LiPS2PwmLineHigh m1 : 50|1@1+ (1,0) [0|1] "" Vector__XXX
 SG_ IBST_a108_LiPS2PwmLineLow m1 : 51|1@1+ (1,0) [0|1] "" Vector__XXX
 SG_ IBST_a109_LiPS2PwmTransmission m1 : 52|1@1+ (1,0) [0|1] "" Vector__XXX
 SG_ IBST_a110_LiPS1SentLineHigh m1 : 53|1@1+ (1,0) [0|1] "" Vector__XXX
 SG_ IBST_a111_LiPS1SentLineLow m1 : 54|1@1+ (1,0) [0|1] "" Vector__XXX
 SG_ IBST_a112_LiPS1SentTransmission m1 : 55|1@1+ (1,0) [0|1] "" Vector__XXX
 SG_ IBST_a113_LiPS1SentSensor m1 : 56|1@1+ (1,0) [0|1] "" Vector__XXX
 SG_ IBST_a114_partyBusOff m1 : 57|1@1+ (1,0) [0|1] "" Vector__XXX
 SG_ IBST_a115_chassisBusOff m1 : 58|1@1+ (1,0) [0|1] "" Vector__XXX
 SG_ IBST_a116_supplyUndervoltageLvl2 m1 : 59|1@1+ (1,0) [0|1] "" Vector__XXX
 SG_ IBST_a117_supplyOvervoltageLvl2 m1 : 60|1@1+ (1,0) [0|1] "" Vector__XXX
 SG_ IBST_a118_RPSNvMReadFault m1 : 61|1@1+ (1,0) [0|1] "" Vector__XXX
 SG_ IBST_a119_RPSWrongCalibData m1 : 62|1@1+ (1,0) [0|1] "" Vector__XXX
 SG_ IBST_a120_RPSVectorRangeHigh m1 : 63|1@1+ (1,0) [0|1] "" Vector__XXX
 SG_ IBST_a121_RPSVectorRangeLow m2 : 4|1@1+ (1,0) [0|1] "" Vector__XXX
 SG_ IBST_a122_RPSVectorOscillating m2 : 5|1@1+ (1,0) [0|1] "" Vector__XXX
 SG_ IBST_a123_bridgeDriverUnavail m2 : 6|1@1+ (1,0) [0|1] "" Vector__XXX
 SG_ IBST_a124_OBDCurrent1OORHigh m2 : 7|1@1+ (1,0) [0|1] "" Vector__XXX
 SG_ IBST_a125_OBDCurrent2OORHigh m2 : 8|1@1+ (1,0) [0|1] "" Vector__XXX
 SG_ IBST_a126_OBDCurrent1OORLow m2 : 9|1@1+ (1,0) [0|1] "" Vector__XXX
 SG_ IBST_a127_OBDCurrent2OORLow m2 : 10|1@1+ (1,0) [0|1] "" Vector__XXX
 SG_ IBST_a128_BLMMuxerTimeoutError m2 : 11|1@1+ (1,0) [0|1] "" Vector__XXX
 SG_ IBST_a129_loadDumpOnFSLTest m2 : 12|1@1+ (1,0) [0|1] "" Vector__XXX
 SG_ IBST_a130_DTSFunctionalRangeLow m2 : 13|1@1+ (1,0) [0|1] "" Vector__XXX
 SG_ IBST_a131_DTSFunctionalRangeHigh m2 : 14|1@1+ (1,0) [0|1] "" Vector__XXX
 SG_ IBST_a132_DTSPlausiCheck1vs2 m2 : 15|1@1+ (1,0) [0|1] "" Vector__XXX
 SG_ IBST_a133_DTSOffsetTooLow m2 : 16|1@1+ (1,0) [0|1] "" Vector__XXX
 SG_ IBST_a134_DTSOffsetTooHigh m2 : 17|1@1+ (1,0) [0|1] "" Vector__XXX
 SG_ IBST_a135_ESPparty1DLC m2 : 18|1@1+ (1,0) [0|1] "" Vector__XXX
 SG_ IBST_a136_ESPparty1Timeout m2 : 19|1@1+ (1,0) [0|1] "" Vector__XXX
 SG_ IBST_a137_ESPparty1Checksum m2 : 20|1@1+ (1,0) [0|1] "" Vector__XXX
 SG_ IBST_a138_ESPparty1Counter m2 : 21|1@1+ (1,0) [0|1] "" Vector__XXX
 SG_ IBST_a139_ESPparty2DLC m2 : 22|1@1+ (1,0) [0|1] "" Vector__XXX
 SG_ IBST_a140_ESPparty2Timeout m2 : 23|1@1+ (1,0) [0|1] "" Vector__XXX
 SG_ IBST_a141_ESPparty2Checksum m2 : 24|1@1+ (1,0) [0|1] "" Vector__XXX
 SG_ IBST_a142_ESPparty2Counter m2 : 25|1@1+ (1,0) [0|1] "" Vector__XXX
 SG_ IBST_a143_ESPparty3DLC m2 : 26|1@1+ (1,0) [0|1] "" Vector__XXX
 SG_ IBST_a144_ESPparty3Timeout m2 : 27|1@1+ (1,0) [0|1] "" Vector__XXX
 SG_ IBST_a145_ESPparty3Checksum m2 : 28|1@1+ (1,0) [0|1] "" Vector__XXX
 SG_ IBST_a146_ESPparty3Counter m2 : 29|1@1+ (1,0) [0|1] "" Vector__XXX
 SG_ IBST_a147_PSCMotorSizeReadFault m2 : 30|1@1+ (1,0) [0|1] "" Vector__XXX
 SG_ IBST_a148_MLIGainMechReadFault m2 : 31|1@1+ (1,0) [0|1] "" Vector__XXX
 SG_ IBST_a149_MLITMCAreaReadFault m2 : 32|1@1+ (1,0) [0|1] "" Vector__XXX
 SG_ IBST_a150_motorTestFault m2 : 33|1@1+ (1,0) [0|1] "" Vector__XXX
 SG_ IBST_a151_PSCGearRatioReadFault m2 : 34|1@1+ (1,0) [0|1] "" Vector__XXX
 SG_ IBST_a152_PSCVoltageImplausible m2 : 35|1@1+ (1,0) [0|1] "" Vector__XXX
 SG_ IBST_a153_unused m2 : 36|1@1+ (1,0) [0|1] "" Vector__XXX
 SG_ IBST_a154_unused m2 : 37|1@1+ (1,0) [0|1] "" Vector__XXX
 SG_ IBST_a155_supplyUndervoltageLvl1 m2 : 38|1@1+ (1,0) [0|1] "" Vector__XXX
 SG_ IBST_a156_supplyOvervoltageLvl1 m2 : 39|1@1+ (1,0) [0|1] "" Vector__XXX
 SG_ IBST_a157_masterCylPressInvalid m2 : 40|1@1+ (1,0) [0|1] "" Vector__XXX
 SG_ IBST_a158_DTSOffsHighSuspicious m2 : 41|1@1+ (1,0) [0|1] "" Vector__XXX
 SG_ IBST_a159_FindIdleNvMReadError m2 : 42|1@1+ (1,0) [0|1] "" Vector__XXX
 SG_ IBST_a160_DTSIDTimeOut m2 : 43|1@1+ (1,0) [0|1] "" Vector__XXX
 SG_ IBST_a161_powerPackMismatch m2 : 44|1@1+ (1,0) [0|1] "" Vector__XXX
 SG_ IBST_a162_idlePosNotDetected m2 : 45|1@1+ (1,0) [0|1] "" Vector__XXX
 SG_ IBST_a163_ESPpEstMaxInvalid m2 : 46|1@1+ (1,0) [0|1] "" Vector__XXX
 SG_ IBST_a164_ESPVehicleSpeedInvalid m2 : 47|1@1+ (1,0) [0|1] "" Vector__XXX
 SG_ IBST_a165_ESPpForceBlendInvalid m2 : 48|1@1+ (1,0) [0|1] "" Vector__XXX
 SG_ IBST_a166_ESPpMcVirtualInvalid m2 : 49|1@1+ (1,0) [0|1] "" Vector__XXX
 SG_ IBST_a167_ESPqTargetExterInvalid m2 : 50|1@1+ (1,0) [0|1] "" Vector__XXX
 SG_ IBST_a168_CANOvervoltage m2 : 51|1@1+ (1,0) [0|1] "" Vector__XXX
 SG_ IBST_a169_CANUndervoltage m2 : 52|1@1+ (1,0) [0|1] "" Vector__XXX
 SG_ IBST_a170_LVPowerStateTimeout m2 : 53|1@1+ (1,0) [0|1] "" Vector__XXX
 SG_ IBST_a171_LVPowerStateChecksum m2 : 54|1@1+ (1,0) [0|1] "" Vector__XXX
 SG_ IBST_a172_LVPowerStateDLC m2 : 55|1@1+ (1,0) [0|1] "" Vector__XXX
 SG_ IBST_a173_LVPowerStateCounter m2 : 56|1@1+ (1,0) [0|1] "" Vector__XXX
 SG_ IBST_a174_LVOffStateInvalid m2 : 57|1@1+ (1,0) [0|1] "" Vector__XXX
 SG_ IBST_a175_LVGoingDownInvalid m2 : 58|1@1+ (1,0) [0|1] "" Vector__XXX
 SG_ IBST_a176_blockedPedalDetected m2 : 59|1@1+ (1,0) [0|1] "" Vector__XXX
 SG_ IBST_a177_EPBLsystemStatusMIA m2 : 60|1@1+ (1,0) [0|1] "" Vector__XXX
 SG_ IBST_a178_EPBRsystemStatusMIA m2 : 61|1@1+ (1,0) [0|1] "" Vector__XXX
 SG_ IBST_a179_VCLEFTepbmStatusMIA m2 : 62|1@1+ (1,0) [0|1] "" Vector__XXX
 SG_ IBST_a180_VCRIGHTepbmStatusMIA m2 : 63|1@1+ (1,0) [0|1] "" Vector__XXX
 SG_ IBST_a181_DIchassisControlDLC m3 : 4|1@1+ (1,0) [0|1] "" Vector__XXX
 SG_ IBST_a182_DIchassisControlTimeou m3 : 5|1@1+ (1,0) [0|1] "" Vector__XXX
 SG_ IBST_a183_DIchassisControlChecks m3 : 6|1@1+ (1,0) [0|1] "" Vector__XXX
 SG_ IBST_a184_DIchassisControlCounte m3 : 7|1@1+ (1,0) [0|1] "" Vector__XXX
 SG_ IBST_a185_rightBusOff m3 : 8|1@1+ (1,0) [0|1] "" Vector__XXX
 SG_ IBST_a186_rightBusPassive m3 : 9|1@1+ (1,0) [0|1] "" Vector__XXX
 SG_ IBST_a187_brakeBusOff m3 : 10|1@1+ (1,0) [0|1] "" Vector__XXX
 SG_ IBST_a188_brakeBusPassive m3 : 11|1@1+ (1,0) [0|1] "" Vector__XXX
 SG_ IBST_a189_rightVCLVPowerStateTim m3 : 12|1@1+ (1,0) [0|1] "" Vector__XXX
 SG_ IBST_a190_rightVCLVPowerStateDLC m3 : 13|1@1+ (1,0) [0|1] "" Vector__XXX
 SG_ IBST_a191_rightVCLVPowerStateChe m3 : 14|1@1+ (1,0) [0|1] "" Vector__XXX
 SG_ IBST_a192_rightVCLVPowerStateCou m3 : 15|1@1+ (1,0) [0|1] "" Vector__XXX
 SG_ IBST_a193_leftVCLVPowerStateTime m3 : 16|1@1+ (1,0) [0|1] "" Vector__XXX
 SG_ IBST_a194_leftVCLVPowerStateChec m3 : 17|1@1+ (1,0) [0|1] "" Vector__XXX
 SG_ IBST_a195_leftVCLVPowerStateDLC m3 : 18|1@1+ (1,0) [0|1] "" Vector__XXX
 SG_ IBST_a196_leftVCLVPowerStateCoun m3 : 19|1@1+ (1,0) [0|1] "" Vector__XXX
 SG_ IBST_a197_brakeLatencyReductionA m3 : 20|1@1+ (1,0) [0|1] "" Vector__XXX
 SG_ IBST_a198_aesActive m3 : 21|1@1+ (1,0) [0|1] "" Vector__XXX
 SG_ IBST_a199_undefinedAlertDetected m3 : 22|1@1+ (1,0) [0|1] "" Vector__XXX
 SG_ IBST_a200_aesFault m3 : 23|1@1+ (1,0) [0|1] "" Vector__XXX
 SG_ IBST_a201_EGGREAR1wheelSpeedsRea m3 : 24|1@1+ (1,0) [0|1] "" Vector__XXX
 SG_ IBST_a202_EGGREAR1wheelSpeedsRea m3 : 25|1@1+ (1,0) [0|1] "" Vector__XXX
 SG_ IBST_a203_EGGREAR1wheelSpeedsRea m3 : 26|1@1+ (1,0) [0|1] "" Vector__XXX
 SG_ IBST_a204_EGGREAR1wheelSpeedsRea m3 : 27|1@1+ (1,0) [0|1] "" Vector__XXX
 SG_ IBST_a205_EGGRIGHT1wheelSpeedsFr m3 : 28|1@1+ (1,0) [0|1] "" Vector__XXX
 SG_ IBST_a206_EGGRIGHT1wheelSpeedsFr m3 : 29|1@1+ (1,0) [0|1] "" Vector__XXX
 SG_ IBST_a207_EGGRIGHT1wheelSpeedsFr m3 : 30|1@1+ (1,0) [0|1] "" Vector__XXX
 SG_ IBST_a208_EGGRIGHT1wheelSpeedsFr m3 : 31|1@1+ (1,0) [0|1] "" Vector__XXX
 SG_ IBST_a209_reducedBrakePowerActiv m3 : 32|1@1+ (1,0) [0|1] "" Vector__XXX
 SG_ IBST_a210_reducedBrakePowerNotAv m3 : 33|1@1+ (1,0) [0|1] "" Vector__XXX
 SG_ IBST_a211_DETReportError m3 : 34|1@1+ (1,0) [0|1] "" Vector__XXX
 SG_ IBST_a212_infoFailureWrongCUBASH m3 : 35|1@1+ (1,0) [0|1] "" Vector__XXX
 SG_ IBST_a213_PDURouterinitializatio m3 : 36|1@1+ (1,0) [0|1] "" Vector__XXX
 SG_ IBST_a214_LossOfPDUInstanceDetec m3 : 37|1@1+ (1,0) [0|1] "" Vector__XXX
 SG_ IBST_a215_UnsupportedSeriesHWDet m3 : 38|1@1+ (1,0) [0|1] "" Vector__XXX
 SG_ IBST_a216_AsicMalfunctionDetecte m3 : 39|1@1+ (1,0) [0|1] "" Vector__XXX
 SG_ IBST_a217_AsicTrimmingNotComplet m3 : 40|1@1+ (1,0) [0|1] "" Vector__XXX
 SG_ IBST_a218_uCSafetyNotificationGR m3 : 41|1@1+ (1,0) [0|1] "" Vector__XXX
 SG_ IBST_a219_uCSafetyNotification m3 : 42|1@1+ (1,0) [0|1] "" Vector__XXX
 SG_ IBST_a220_ASICOvercurrentOnGPIO2 m3 : 43|1@1+ (1,0) [0|1] "" Vector__XXX
 SG_ IBST_a221_ASICOvercurrentOnGPIO2 m3 : 44|1@1+ (1,0) [0|1] "" Vector__XXX
 SG_ IBST_a222_ASICOvercurrentOnGPIO5 m3 : 45|1@1+ (1,0) [0|1] "" Vector__XXX
 SG_ IBST_a223_ASICOvercurrentOnGPIO5 m3 : 46|1@1+ (1,0) [0|1] "" Vector__XXX
 SG_ IBST_a224_ASICOvercurrentOnGPIO5 m3 : 47|1@1+ (1,0) [0|1] "" Vector__XXX
 SG_ IBST_a225_ASICOvercurrentOnGPIO5 m3 : 48|1@1+ (1,0) [0|1] "" Vector__XXX
 SG_ IBST_a226_ASICOvercurrentOnWRHS m3 : 49|1@1+ (1,0) [0|1] "" Vector__XXX
 SG_ IBST_a227_wakeRequestMismatchDet m3 : 50|1@1+ (1,0) [0|1] "" Vector__XXX
 SG_ IBST_a228_BlockedPedalDetectedDu m3 : 51|1@1+ (1,0) [0|1] "" Vector__XXX
 SG_ IBST_a229_BlockedPedalDetected m3 : 52|1@1+ (1,0) [0|1] "" Vector__XXX
 SG_ IBST_a230_DTS2FunctionalRangeLow m3 : 53|1@1+ (1,0) [0|1] "" Vector__XXX
 SG_ IBST_a231_DTS2FunctionalRangeLow m3 : 54|1@1+ (1,0) [0|1] "" Vector__XXX
 SG_ IBST_a232_PostAssemblyRoutineFai m3 : 55|1@1+ (1,0) [0|1] "" Vector__XXX
 SG_ IBST_a233_ReferenceRunAbortByECU m3 : 56|1@1+ (1,0) [0|1] "" Vector__XXX
 SG_ IBST_a234_LiPSOutOfRangeHigh m3 : 57|1@1+ (1,0) [0|1] "" Vector__XXX
 SG_ IBST_a235_LiPSOutOfRangeLow m3 : 58|1@1+ (1,0) [0|1] "" Vector__XXX
 SG_ IBST_a246_DASredundantBrakingCon m4 : 9|1@1+ (1,0) [0|1] "" Vector__XXX
 SG_ IBST_a247_DASredundantBrakingCon m4 : 10|1@1+ (1,0) [0|1] "" Vector__XXX
 SG_ IBST_a248_DASredundantBrakingCon m4 : 11|1@1+ (1,0) [0|1] "" Vector__XXX
 SG_ IBST_a249_DASredundantBrakingCon m4 : 12|1@1+ (1,0) [0|1] "" Vector__XXX
 SG_ IBST_a250_DASredundantBrakingCon m4 : 13|1@1+ (1,0) [0|1] "" Vector__XXX
 SG_ IBST_a251_DASredundantBrakingCon m4 : 14|1@1+ (1,0) [0|1] "" Vector__XXX
 SG_ IBST_a252_DASredundantBrakingCon m4 : 15|1@1+ (1,0) [0|1] "" Vector__XXX
 SG_ IBST_a253_DASredundantBrakingCon m4 : 16|1@1+ (1,0) [0|1] "" Vector__XXX
 SG_ IBST_a254_DIlocStatus2Checksum m4 : 17|1@1+ (1,0) [0|1] "" Vector__XXX
 SG_ IBST_a255_DIlocStatus2Counter m4 : 18|1@1+ (1,0) [0|1] "" Vector__XXX
 SG_ IBST_a256_DIlocStatus2DLC m4 : 19|1@1+ (1,0) [0|1] "" Vector__XXX
 SG_ IBST_a257_DIlocStatus2Timeout m4 : 20|1@1+ (1,0) [0|1] "" Vector__XXX
 SG_ IBST_a258_standaloneEBRActive m4 : 21|1@1+ (1,0) [0|1] "" Vector__XXX
 SG_ IBST_a259_EMCMain11Checksum m4 : 22|1@1+ (1,0) [0|1] "" Vector__XXX
 SG_ IBST_a260_EMCMain11Counter m4 : 23|1@1+ (1,0) [0|1] "" Vector__XXX
 SG_ IBST_a261_EMCMain11DLC m4 : 24|1@1+ (1,0) [0|1] "" Vector__XXX
 SG_ IBST_a262_EMCMain11Timeout m4 : 25|1@1+ (1,0) [0|1] "" Vector__XXX
 SG_ IBST_a263_EMCMain21Checksum m4 : 26|1@1+ (1,0) [0|1] "" Vector__XXX
 SG_ IBST_a264_EMCMain21Counter m4 : 27|1@1+ (1,0) [0|1] "" Vector__XXX
 SG_ IBST_a265_EMCMain21DLC m4 : 28|1@1+ (1,0) [0|1] "" Vector__XXX
 SG_ IBST_a266_EMCMain21Timeout m4 : 29|1@1+ (1,0) [0|1] "" Vector__XXX

BO_ 813 IBST_info: 8 IBST
 SG_ IBST_infoIndex M : 0|8@1+ (1,0) [0|255] "" Vector__XXX
 SG_ IBST_infoBuildType m10 : 8|8@1+ (1,0) [0|255] "" Vector__XXX
 SG_ IBST_infoComponentID m10 : 55|16@0+ (1,0) [0|65535] "" Vector__XXX
 SG_ IBST_infoPcbaID m11 : 16|8@1+ (1,0) [0|255] "" Vector__XXX
 SG_ IBST_infoAssemblyID m11 : 24|8@1+ (1,0) [0|255] "" Vector__XXX
 SG_ IBST_infoUsageID m11 : 32|16@1+ (1,0) [0|65535] "" Vector__XXX
 SG_ IBST_infoSubUsageID m11 : 48|16@1+ (1,0) [0|65535] "" Vector__XXX
 SG_ IBST_infoApplicationCRC m13 : 32|32@1+ (1,0) [0|4294967295] "" Vector__XXX
 SG_ IBST_infoBootUdsProtoVersion m20 : 8|8@1+ (1,0) [0|255] "" Vector__XXX
 SG_ IBST_infoBootloaderCRC m20 : 32|32@1+ (1,0) [0|4294967295] "" Vector__XXX
 SG_ IBST_infoVariantCRC m22 : 32|32@1+ (1,0) [0|4294967295] "" Vector__XXX

BO_ 1629 IBST_udsResponse: 8 IBST
 SG_ IBST_udsResponseData : 7|64@0+ (1,0) [0|1.84467440737e+19] "" Vector__XXX

BO_TX_BU_ 913 : EPAS3S;
BO_TX_BU_ 977 : EPAS3S;
BO_TX_BU_ 785 : EPAS3S;
BO_TX_BU_ 880 : EPAS3S;
BO_TX_BU_ 1848 : EPAS3S;
BO_TX_BU_ 981 : ESP;
BO_TX_BU_ 805 : ESP;
BO_TX_BU_ 1621 : ESP;
BO_TX_BU_ 861 : IBST;
BO_TX_BU_ 813 : IBST;
BO_TX_BU_ 1629 : IBST;
CM_ BO_ 913 "Electric power steering (secondary) message: alert matrix; frame length from the layout, not yet observed on a vehicle bus";
CM_ SG_ 913 EPAS3S_matrixIndex "Electric power steering (secondary): matrix index";
CM_ SG_ 913 EPAS3S_a001_sent1Mia "Electric power steering (secondary): a001 sent1 mia";
CM_ SG_ 913 EPAS3S_a002_sent1Error "Electric power steering (secondary): a002 sent1 error";
CM_ SG_ 913 EPAS3S_a003_trqSens1Supply "Electric power steering (secondary): a003 trq sens1 supply";
CM_ SG_ 913 EPAS3S_a004_trqSens1Eeprom "Electric power steering (secondary): a004 trq sens1 eeprom";
CM_ SG_ 913 EPAS3S_a005_sent2Mia "Electric power steering (secondary): a005 sent2 mia";
CM_ SG_ 913 EPAS3S_a006_sent2Error "Electric power steering (secondary): a006 sent2 error";
CM_ SG_ 913 EPAS3S_a007_trqSens2Supply "Electric power steering (secondary): a007 trq sens2 supply";
CM_ SG_ 913 EPAS3S_a008_trqSens2Eeprom "Electric power steering (secondary): a008 trq sens2 eeprom";
CM_ SG_ 913 EPAS3S_a009_sentDiff "Electric power steering (secondary): a009 sent diff";
CM_ SG_ 913 EPAS3S_a010_trqSensCalError "Electric power steering (secondary): a010 trq sens cal error";
CM_ SG_ 913 EPAS3S_a011_currentSensError "Electric power steering (secondary): a011 current sens error";
CM_ SG_ 913 EPAS3S_a012_currentSensCalError "Electric power steering (secondary): a012 current sens cal error";
CM_ SG_ 913 EPAS3S_a013_gateDriveError "Electric power steering (secondary): a013 gate drive error";
CM_ SG_ 913 EPAS3S_a014_gateDriveTxError "Electric power steering (secondary): a014 gate drive tx error";
CM_ SG_ 913 EPAS3S_a015_gateDriveEeprom "Electric power steering (secondary): a015 gate drive eeprom";
CM_ SG_ 913 EPAS3S_a016_phaseUhighUv "Electric power steering (secondary): a016 phase uhigh uv";
CM_ SG_ 913 EPAS3S_a017_phaseUlowUv "Electric power steering (secondary): a017 phase ulow uv";
CM_ SG_ 913 EPAS3S_a018_phaseVhighUv "Electric power steering (secondary): a018 phase vhigh uv";
CM_ SG_ 913 EPAS3S_a019_phaseVlowUv "Electric power steering (secondary): a019 phase vlow uv";
CM_ SG_ 913 EPAS3S_a020_phaseWhighUv "Electric power steering (secondary): a020 phase whigh uv";
CM_ SG_ 913 EPAS3S_a021_phaseWlowUv "Electric power steering (secondary): a021 phase wlow uv";
CM_ SG_ 913 EPAS3S_a022_phaseUhighOv "Electric power steering (secondary): a022 phase uhigh ov";
CM_ SG_ 913 EPAS3S_a023_phaseUlowOv "Electric power steering (secondary): a023 phase ulow ov";
CM_ SG_ 913 EPAS3S_a024_phaseVhighOv "Electric power steering (secondary): a024 phase vhigh ov";
CM_ SG_ 913 EPAS3S_a025_phaseVlowOv "Electric power steering (secondary): a025 phase vlow ov";
CM_ SG_ 913 EPAS3S_a026_phaseWhighOv "Electric power steering (secondary): a026 phase whigh ov";
CM_ SG_ 913 EPAS3S_a027_phaseWlowOv "Electric power steering (secondary): a027 phase wlow ov";
CM_ SG_ 913 EPAS3S_a028_phaseUbootUv "Electric power steering (secondary): a028 phase uboot uv";
CM_ SG_ 913 EPAS3S_a029_phaseVbootUv "Electric power steering (secondary): a029 phase vboot uv";
CM_ SG_ 913 EPAS3S_a030_phaseWbootUv "Electric power steering (secondary): a030 phase wboot uv";
CM_ SG_ 913 EPAS3S_a031_abnormalShutdown "Electric power steering (secondary): a031 abnormal shutdown";
CM_ SG_ 913 EPAS3S_a032_vRegOutputUv "Electric power steering (secondary): a032 v reg output uv";
CM_ SG_ 913 EPAS3S_a033_vRegOutputOv "Electric power steering (secondary): a033 v reg output ov";
CM_ SG_ 913 EPAS3S_a034_vRegError "Electric power steering (secondary): a034 v reg error";
CM_ SG_ 913 EPAS3S_a035_vbbSupplyUv "Electric power steering (secondary): a035 vbb supply uv";
CM_ SG_ 913 EPAS3S_a036_vbbSupplyOv "Electric power steering (secondary): a036 vbb supply ov";
CM_ SG_ 913 EPAS3S_a037_motPos1ParityError "Electric power steering (secondary): a037 mot pos1 parity error";
CM_ SG_ 913 EPAS3S_a038_motPos1Uv "Electric power steering (secondary): a038 mot pos1 uv";
CM_ SG_ 913 EPAS3S_a039_motPos1MagnetMia "Electric power steering (secondary): a039 mot pos1 magnet mia";
CM_ SG_ 913 EPAS3S_a040_motPos1LogicError "Electric power steering (secondary): a040 mot pos1 logic error";
CM_ SG_ 913 EPAS3S_a041_motPos1tempError "Electric power steering (secondary): a041 mot pos1temp error";
CM_ SG_ 913 EPAS3S_a042_motPos2ParityError "Electric power steering (secondary): a042 mot pos2 parity error";
CM_ SG_ 913 EPAS3S_a043_motPos2Uv "Electric power steering (secondary): a043 mot pos2 uv";
CM_ SG_ 913 EPAS3S_a044_motPos2MagnetMia "Electric power steering (secondary): a044 mot pos2 magnet mia";
CM_ SG_ 913 EPAS3S_a045_motPos2LogicError "Electric power steering (secondary): a045 mot pos2 logic error";
CM_ SG_ 913 EPAS3S_a046_motPos2tempError "Electric power steering (secondary): a046 mot pos2temp error";
CM_ SG_ 913 EPAS3S_a047_motPosCorrError "Electric power steering (secondary): a047 mot pos corr error";
CM_ SG_ 913 EPAS3S_a048_motPosCalError "Electric power steering (secondary): a048 mot pos cal error";
CM_ SG_ 913 EPAS3S_a049_piCtrlError "Electric power steering (secondary): a049 pi ctrl error";
CM_ SG_ 913 EPAS3S_a050_mcuSmuError "Electric power steering (secondary): a050 mcu smu error";
CM_ SG_ 913 EPAS3S_a051_mcuSupError "Electric power steering (secondary): a051 mcu sup error";
CM_ SG_ 913 EPAS3S_a052_intWatchdogError "Electric power steering (secondary): a052 int watchdog error";
CM_ SG_ 913 EPAS3S_a053_extWatchdogError "Electric power steering (secondary): a053 ext watchdog error";
CM_ SG_ 913 EPAS3S_a054_memoryProtectError "Electric power steering (secondary): a054 memory protect error";
CM_ SG_ 913 EPAS3S_a055_floatPointError "Electric power steering (secondary): a055 float point error";
CM_ SG_ 913 EPAS3S_a056_battUv "Electric power steering (secondary): a056 batt uv";
CM_ SG_ 913 EPAS3S_a057_battUvReduced "Electric power steering (secondary): a057 batt uv reduced";
CM_ SG_ 913 EPAS3S_a058_battOv "Electric power steering (secondary): a058 batt ov";
CM_ SG_ 913 EPAS3S_a059_battOvReduced "Electric power steering (secondary): a059 batt ov reduced";
CM_ SG_ 913 EPAS3S_a060_battBridgeDiff "Electric power steering (secondary): a060 batt bridge diff";
CM_ SG_ 913 EPAS3S_a061_bridgeUv "Electric power steering (secondary): a061 bridge uv";
CM_ SG_ 913 EPAS3S_a062_assistCorrError "Electric power steering (secondary): a062 assist corr error";
CM_ SG_ 913 EPAS3S_a063_dampCorrError "Electric power steering (secondary): a063 damp corr error";
CM_ SG_ 913 EPAS3S_a064_phaseCompCorrError "Electric power steering (secondary): a064 phase comp corr error";
CM_ SG_ 913 EPAS3S_a065_trqTarCorrError "Electric power steering (secondary): a065 trq tar corr error";
CM_ SG_ 913 EPAS3S_a066_returnCorrError "Electric power steering (secondary): a066 return corr error";
CM_ SG_ 913 EPAS3S_a067_yawDampCorrError "Electric power steering (secondary): a067 yaw damp corr error";
CM_ SG_ 913 EPAS3S_a068_hystCorrError "Electric power steering (secondary): a068 hyst corr error";
CM_ SG_ 913 EPAS3S_a069_eacCorrError "Electric power steering (secondary): a069 eac corr error";
CM_ SG_ 913 EPAS3S_a070_hodCorrError "Electric power steering (secondary): a070 hod corr error";
CM_ SG_ 913 EPAS3S_a071_vehSpdCorrError "Electric power steering (secondary): a071 veh spd corr error";
CM_ SG_ 913 EPAS3S_a072_motFeedFwdError "Electric power steering (secondary): a072 mot feed fwd error";
CM_ SG_ 913 EPAS3S_a073_motParEstError "Electric power steering (secondary): a073 mot par est error";
CM_ SG_ 913 EPAS3S_a074_overHeatProtect "Electric power steering (secondary): a074 over heat protect";
CM_ SG_ 913 EPAS3S_a075_fspPwrCut "Electric power steering (secondary): a075 fsp pwr cut";
CM_ SG_ 913 EPAS3S_a076_tempSensOutofRange "Electric power steering (secondary): a076 temp sens outof range";
CM_ SG_ 913 EPAS3S_a077_highSideFetError "Electric power steering (secondary): a077 high side fet error";
CM_ SG_ 913 EPAS3S_a078_phaseDisconnectError "Electric power steering (secondary): a078 phase disconnect error";
CM_ SG_ 913 EPAS3S_a079_backupCurrentPlaus "Electric power steering (secondary): a079 backup current plaus";
CM_ SG_ 913 EPAS3S_a080_ecuInitArbError "Electric power steering (secondary): a080 ecu init arb error";
CM_ SG_ 913 EPAS3S_a081_coggCompError "Electric power steering (secondary): a081 cogg comp error";
CM_ SG_ 913 EPAS3S_a082_polarityCalError "Electric power steering (secondary): a082 polarity cal error";
CM_ SG_ 913 EPAS3S_a083_crcMismatch "Electric power steering (secondary): a083 crc mismatch";
CM_ SG_ 913 EPAS3S_a084_eacCancelled "Electric power steering (secondary): a084 eac cancelled";
CM_ SG_ 913 EPAS3S_a085_canBusOff "Electric power steering (secondary): a085 can bus off";
CM_ SG_ 913 EPAS3S_a086_dasMia "Electric power steering (secondary): a086 das mia";
CM_ SG_ 913 EPAS3S_a087_dasCntError "Electric power steering (secondary): a087 das cnt error";
CM_ SG_ 913 EPAS3S_a088_dasCsError "Electric power steering (secondary): a088 das cs error";
CM_ SG_ 913 EPAS3S_a089_espWsMia "Electric power steering (secondary): a089 esp ws mia";
CM_ SG_ 913 EPAS3S_a090_espWsCntError "Electric power steering (secondary): a090 esp ws cnt error";
CM_ SG_ 913 EPAS3S_a091_espWsCsError "Electric power steering (secondary): a091 esp ws cs error";
CM_ SG_ 913 EPAS3S_a092_espWrMia "Electric power steering (secondary): a092 esp wr mia";
CM_ SG_ 913 EPAS3S_a093_espWrCntError "Electric power steering (secondary): a093 esp wr cnt error";
CM_ SG_ 913 EPAS3S_a094_espWrCsError "Electric power steering (secondary): a094 esp wr cs error";
CM_ SG_ 913 EPAS3S_a095_espWsStatus "Electric power steering (secondary): a095 esp ws status";
CM_ SG_ 913 EPAS3S_a096_rcmMia "Electric power steering (secondary): a096 rcm mia";
CM_ SG_ 913 EPAS3S_a097_rcmCntError "Electric power steering (secondary): a097 rcm cnt error";
CM_ SG_ 913 EPAS3S_a098_rcmCsError "Electric power steering (secondary): a098 rcm cs error";
CM_ SG_ 913 EPAS3S_a099_yawRateStatus "Electric power steering (secondary): a099 yaw rate status";
CM_ SG_ 913 EPAS3S_a100_diMia "Electric power steering (secondary): a100 di mia";
CM_ SG_ 913 EPAS3S_a101_diCntError "Electric power steering (secondary): a101 di cnt error";
CM_ SG_ 913 EPAS3S_a102_diCsError "Electric power steering (secondary): a102 di cs error";
CM_ SG_ 913 EPAS3S_a103_vcFrontMia "Electric power steering (secondary): a103 vc front mia";
CM_ SG_ 913 EPAS3S_a104_vcFrontCntError "Electric power steering (secondary): a104 vc front cnt error";
CM_ SG_ 913 EPAS3S_a105_vcFrontCsError "Electric power steering (secondary): a105 vc front cs error";
CM_ SG_ 913 EPAS3S_a106_vcFrontTempMia "Electric power steering (secondary): a106 vc front temp mia";
CM_ SG_ 913 EPAS3S_a107_uiTuneReqMia "Electric power steering (secondary): a107 ui tune req mia";
CM_ SG_ 913 EPAS3S_a108_uiTuneReqCntError "Electric power steering (secondary): a108 ui tune req cnt error";
CM_ SG_ 913 EPAS3S_a109_uiTuneReqCsError "Electric power steering (secondary): a109 ui tune req cs error";
CM_ SG_ 913 EPAS3S_a110_sasMia "Electric power steering (secondary): a110 sas mia";
CM_ SG_ 913 EPAS3S_a111_sasCntError "Electric power steering (secondary): a111 sas cnt error";
CM_ SG_ 913 EPAS3S_a112_sasCsError "Electric power steering (secondary): a112 sas cs error";
CM_ SG_ 913 EPAS3S_a113_sasStatusError "Electric power steering (secondary): a113 sas status error";
CM_ SG_ 913 EPAS3S_a114_gtwConfigMia "Electric power steering (secondary): a114 gtw config mia";
CM_ SG_ 913 EPAS3S_a115_ecuStatMia "Electric power steering (secondary): a115 ecu stat mia";
CM_ SG_ 913 EPAS3S_a116_ecuStatCntError "Electric power steering (secondary): a116 ecu stat cnt error";
CM_ SG_ 913 EPAS3S_a117_ecuStatCrcError "Electric power steering (secondary): a117 ecu stat crc error";
CM_ SG_ 913 EPAS3S_a118_privateBusOff "Electric power steering (secondary): a118 private bus off";
CM_ SG_ 913 EPAS3S_a119_pvtEcuStatMia "Electric power steering (secondary): a119 pvt ecu stat mia";
CM_ SG_ 913 EPAS3S_a120_pvtEcuStatCntError "Electric power steering (secondary): a120 pvt ecu stat cnt error";
CM_ SG_ 913 EPAS3S_a121_pvtEcuStatCrcError "Electric power steering (secondary): a121 pvt ecu stat crc error";
CM_ SG_ 913 EPAS3S_a122_olpActive "Electric power steering (secondary): a122 olp active";
CM_ SG_ 913 EPAS3S_a123_combEcu2StatFail "Electric power steering (secondary): a123 comb ecu2 stat fail";
CM_ SG_ 913 EPAS3S_a124_tempSensStuckInRange "Electric power steering (secondary): a124 temp sens stuck in range";
CM_ SG_ 913 EPAS3S_a125_trqSensTrimOutRange "Electric power steering (secondary): a125 trq sens trim out range";
CM_ SG_ 913 EPAS3S_a126_apsMia "Electric power steering (secondary): a126 aps mia";
CM_ SG_ 913 EPAS3S_a127_apsCntError "Electric power steering (secondary): a127 aps cnt error";
CM_ SG_ 913 EPAS3S_a128_apsCsError "Electric power steering (secondary): a128 aps cs error";
CM_ SG_ 913 EPAS3S_a129_combEcu1StatFail "Electric power steering (secondary): a129 comb ecu1 stat fail";
CM_ SG_ 913 EPAS3S_a130_sasOffsetNotCal "Electric power steering (secondary): a130 sas offset not cal";
CM_ SG_ 913 EPAS3S_a131_phaseFeedbackError "Electric power steering (secondary): a131 phase feedback error";
CM_ SG_ 913 EPAS3S_a132_motFeedFwdCounter25 "Electric power steering (secondary): a132 mot feed fwd counter25";
CM_ SG_ 913 EPAS3S_a133_motFeedFwdCounter50 "Electric power steering (secondary): a133 mot feed fwd counter50";
CM_ SG_ 913 EPAS3S_a134_motFeedFwdCounter85 "Electric power steering (secondary): a134 mot feed fwd counter85";
CM_ SG_ 913 EPAS3S_a135_piCtrlCounter25 "Electric power steering (secondary): a135 pi ctrl counter25";
CM_ SG_ 913 EPAS3S_a136_piCtrlCounter50 "Electric power steering (secondary): a136 pi ctrl counter50";
CM_ SG_ 913 EPAS3S_a137_piCtrlCounter85 "Electric power steering (secondary): a137 pi ctrl counter85";
CM_ SG_ 913 EPAS3S_a144_diSpdMia "Electric power steering (secondary): a144 di spd mia";
CM_ SG_ 913 EPAS3S_a145_diSpdCntError "Electric power steering (secondary): a145 di spd cnt error";
CM_ SG_ 913 EPAS3S_a146_diSpdCsError "Electric power steering (secondary): a146 di spd cs error";
CM_ SG_ 913 EPAS3S_a147_backupVehSpeed "Electric power steering (secondary): a147 backup veh speed";
CM_ SG_ 913 EPAS3S_a148_vMaxAssist "Electric power steering (secondary): a148 v max assist";
CM_ SG_ 913 EPAS3S_a149_currentSensPathSwitc "Electric power steering (secondary): a149 current sens path switch";
CM_ SG_ 913 EPAS3S_a150_currentSensOffsetDet "Electric power steering (secondary): a150 current sens offset detect";
CM_ SG_ 913 EPAS3S_a151_dcsCboot "Electric power steering (secondary): a151 dcs cboot";
CM_ SG_ 913 EPAS3S_a152_dcsDiagReg "Electric power steering (secondary): a152 dcs diag reg";
CM_ SG_ 913 EPAS3S_a153_dcsInitOffset "Electric power steering (secondary): a153 dcs init offset";
CM_ SG_ 913 EPAS3S_a154_assistTorqueDisabled "Electric power steering (secondary): a154 assist torque disabled";
CM_ SG_ 913 EPAS3S_a155_backupEacActive "Electric power steering (secondary): a155 backup eac active";
CM_ SG_ 913 EPAS3S_a156_angleSensorDivergenc "Electric power steering (secondary): a156 angle sensor divergence";
CM_ SG_ 913 EPAS3S_a157_pmState2Mia "Electric power steering (secondary): a157 pm state2 mia";
CM_ SG_ 913 EPAS3S_a158_pmState2CntError "Electric power steering (secondary): a158 pm state2 cnt error";
CM_ SG_ 913 EPAS3S_a159_pmState2CsError "Electric power steering (secondary): a159 pm state2 cs error";
CM_ SG_ 913 EPAS3S_a160_latentFaultTestResul "Electric power steering (secondary): a160 latent fault test result";
CM_ SG_ 913 EPAS3S_a161_initTestPhaDisconnIn "Electric power steering (secondary): a161 init test pha disconn info";
CM_ SG_ 913 EPAS3S_a162_initTestHSDFetInfo "Electric power steering (secondary): a162 init test HSD fet info";
CM_ SG_ 913 EPAS3S_a163_initTestGateDrvrInfo "Electric power steering (secondary): a163 init test gate drvr info";
CM_ SG_ 913 EPAS3S_a164_initTestDCSInfo "Electric power steering (secondary): a164 init test DCS info";
CM_ SG_ 913 EPAS3S_a165_epbStatusMia "Electric power steering (secondary): a165 epb status mia";
CM_ SG_ 913 EPAS3S_a166_epbStatusCntError "Electric power steering (secondary): a166 epb status cnt error";
CM_ SG_ 913 EPAS3S_a167_epbStatusCsError "Electric power steering (secondary): a167 epb status cs error";
CM_ SG_ 913 EPAS3S_a168_torsionBarTorqueQfDe "Electric power steering (secondary): a168 torsion bar torque qf degraded";
CM_ BO_ 977 "Electric power steering (secondary) message: angle calibration; frame length from the layout, not yet observed on a vehicle bus";
CM_ SG_ 977 EPAS3S_appliedAngleOffset "This represents the angle delta between the absolute steering angle reference and what EPAS estimates to be straight ahead. The steering angle offset can change up to 5deg at the beginning of each drive cycle.";
CM_ SG_ 977 EPAS3S_calculatedAngleOffset "Reports the calculated steering angle offset learned between the Steering Column Control Module (SCCM) and the Electronic Power Assist Steering (EPAS) steering angle.";
CM_ SG_ 977 EPAS3S_resyncStatus "Electric power steering (secondary): resync status";
CM_ SG_ 977 EPAS3S_pullDriftLongTermTrq "The learned, long term pull drift or road crown compensation torque that the rack is applying to the steering wheel.";
CM_ SG_ 977 EPAS3S_pullDriftCompTrq "The current pull drift or road crown compensation torque that the rack is applying to the steering wheel.";
CM_ SG_ 977 EPAS3S_learnedSCCMOffset "Electric power steering (secondary): learned SCCM offset";
CM_ BO_ 785 "Electric power steering (secondary) message: info; frame length from the layout, not yet observed on a vehicle bus";
CM_ SG_ 785 EPAS3S_infoIndex "Electric power steering (secondary): info index";
CM_ SG_ 785 EPAS3S_infoBuildType "Electric power steering (secondary): info build type";
CM_ SG_ 785 EPAS3S_infoComponentID "Electric power steering (secondary): info component ID";
CM_ SG_ 785 EPAS3S_infoPcbaID "Electric power steering (secondary): info pcba ID";
CM_ SG_ 785 EPAS3S_infoAssemblyID "Electric power steering (secondary): info assembly ID";
CM_ SG_ 785 EPAS3S_infoUsageID "Electric power steering (secondary): info usage ID";
CM_ SG_ 785 EPAS3S_infoApplicationCRC "Electric power steering (secondary): info application CRC";
CM_ SG_ 785 EPAS3S_infoBootUdsProtoVersion "Electric power steering (secondary): info boot uds proto version";
CM_ SG_ 785 EPAS3S_infoBootloaderCRC "Electric power steering (secondary): info bootloader CRC";
CM_ SG_ 785 EPAS3S_infoSubcomponent2 "Electric power steering (secondary): info subcomponent2";
CM_ BO_ 880 "Electric power steering (secondary) message: sys status; frame length from the layout, not yet observed on a vehicle bus";
CM_ SG_ 880 EPAS3S_steeringRackForce "The real time, estimated force applied by the steering rack to the tie rods; raw 1023 = signal not available (SNA)";
CM_ SG_ 880 EPAS3S_steeringFault "Electric power steering (secondary): steering fault";
CM_ SG_ 880 EPAS3S_steeringReduced "Electric power steering (secondary): steering reduced";
CM_ SG_ 880 EPAS3S_internalSASQF "This signal identifies the validity of the EPAS3P_internalSAS signal.";
CM_ SG_ 880 EPAS3S_currentTuneMode "Electric power steering (secondary): current tune mode";
CM_ SG_ 880 EPAS3S_torsionBarTorque "The measurement of the steering wheel torque input. If the value is positive the steering wheel torque is applied in the clockwise direction; raw 4095 = signal not available (SNA)";
CM_ SG_ 880 EPAS3S_eacErrorCode "Electric power steering (secondary): eac error code; raw 15 = signal not available (SNA)";
CM_ SG_ 880 EPAS3S_internalSAS "The measurement of the steering wheel angle that is calculated by electronic power steering assist steering. Clockwise positive.";
CM_ SG_ 880 EPAS3S_handsOnLevel "Electric power steering (secondary): hands on level";
CM_ SG_ 880 EPAS3S_sysStatusCounter "Electric power steering (secondary): sys status counter";
CM_ SG_ 880 EPAS3S_driverlessState "Electric power steering (secondary): driverless state";
CM_ SG_ 880 EPAS3S_eacStatus "Electric power steering (secondary): eac status";
CM_ SG_ 880 EPAS3S_sysStatusChecksum "Electric power steering (secondary): sys status checksum";
CM_ BO_ 1848 "Electric power steering (secondary) message: uds response; frame length from the layout, not yet observed on a vehicle bus";
CM_ SG_ 1848 EPAS3S_udsResponseData "Electric power steering (secondary): uds response data";
CM_ BO_ 981 "Electronic stability control message: alert matrix; frame length from the layout, not yet observed on a vehicle bus";
CM_ SG_ 981 ESP_matrixIndex "Electronic stability control: matrix index";
CM_ SG_ 981 ESP_a001_ecuGenericFault "Electronic stability control: a001 ecu generic fault";
CM_ SG_ 981 ESP_a002_valvesGenericFault "Electronic stability control: a002 valves generic fault";
CM_ SG_ 981 ESP_a003_outletValvesFault "Electronic stability control: a003 outlet valves fault";
CM_ SG_ 981 ESP_a004_inletValvesFault "Electronic stability control: a004 inlet valves fault";
CM_ SG_ 981 ESP_a005_HSVValvesFault "Electronic stability control: a005 HSV valves fault";
CM_ SG_ 981 ESP_a006_USVValvesFault "Electronic stability control: a006 USV valves fault";
CM_ SG_ 981 ESP_a007_pumpMotorFault "Electronic stability control: a007 pump motor fault";
CM_ SG_ 981 ESP_a008_pumpMotor12VsupplyLow "Electronic stability control: a008 pump motor12 vsupply low";
CM_ SG_ 981 ESP_a009_12VHardUndervoltage "Electronic stability control: a009 12 v hard undervoltage";
CM_ SG_ 981 ESP_a010_12VUndervoltage "Electronic stability control: a010 12 v undervoltage";
CM_ SG_ 981 ESP_a011_12VSystemUndervoltage "Electronic stability control: a011 12 v system undervoltage";
CM_ SG_ 981 ESP_a012_netUndervoltage "Electronic stability control: a012 net undervoltage";
CM_ SG_ 981 ESP_a013_valveRelayUndervoltage "Electronic stability control: a013 valve relay undervoltage";
CM_ SG_ 981 ESP_a014_WSSSupplyUndervoltage "Electronic stability control: a014 WSS supply undervoltage";
CM_ SG_ 981 ESP_a015_12VSupplyOvervoltage "Electronic stability control: a015 12 v supply overvoltage";
CM_ SG_ 981 ESP_a016_12VSystemOvervoltage "Electronic stability control: a016 12 v system overvoltage";
CM_ SG_ 981 ESP_a017_netOvervoltage "Electronic stability control: a017 net overvoltage";
CM_ SG_ 981 ESP_a018_WSSSignFrontAxle "Electronic stability control: a018 WSS sign front axle";
CM_ SG_ 981 ESP_a019_WSSSignRearAxle "Electronic stability control: a019 WSS sign rear axle";
CM_ SG_ 981 ESP_a020_WSSGenericTempFault "Electronic stability control: a020 WSS generic temp fault";
CM_ SG_ 981 ESP_a021_WSSGeneralVDiffFault "Electronic stability control: a021 WSS general v diff fault";
CM_ SG_ 981 ESP_a022_WSSDirectionFault "Electronic stability control: a022 WSS direction fault";
CM_ SG_ 981 ESP_a023_WSSSeveralSuspected "Electronic stability control: a023 WSS several suspected";
CM_ SG_ 981 ESP_a024_WSSReverseCurrent "Electronic stability control: a024 WSS reverse current";
CM_ SG_ 981 ESP_a025_FrLWSSOpenOrShortToGnd "Electronic stability control: a025 fr LWSS open or short to gnd";
CM_ SG_ 981 ESP_a026_FrLWSSShortTo12V "Electronic stability control: a026 fr LWSS short to12 v";
CM_ SG_ 981 ESP_a027_FrLWSSLineInterruption "Electronic stability control: a027 fr LWSS line interruption";
CM_ SG_ 981 ESP_a028_FrLWSSMaxSpeedExceeded "Electronic stability control: a028 fr LWSS max speed exceeded";
CM_ SG_ 981 ESP_a029_FrLWSSTooManyPulses "Electronic stability control: a029 fr LWSS too many pulses";
CM_ SG_ 981 ESP_a030_FrLWSSLostSignal "Electronic stability control: a030 fr LWSS lost signal";
CM_ SG_ 981 ESP_a031_FrLWSSNoPulsesDetected "Electronic stability control: a031 fr LWSS no pulses detected";
CM_ SG_ 981 ESP_a032_FrLWSSWrongSensorType "Electronic stability control: a032 fr LWSS wrong sensor type";
CM_ SG_ 981 ESP_a033_FrLWSSSignalNoise "Electronic stability control: a033 fr LWSS signal noise";
CM_ SG_ 981 ESP_a034_FrLWSSVDiffFault "Electronic stability control: a034 fr LWSSV diff fault";
CM_ SG_ 981 ESP_a035_FrLWSSDirectionFault "Electronic stability control: a035 fr LWSS direction fault";
CM_ SG_ 981 ESP_a036_FrLWSSLargeAirGap "Electronic stability control: a036 fr LWSS large air gap";
CM_ SG_ 981 ESP_a037_FrLWSSSupplyShortToGnd "Electronic stability control: a037 fr LWSS supply short to gnd";
CM_ SG_ 981 ESP_a038_FrLWSSGeneralFault "Electronic stability control: a038 fr LWSS general fault";
CM_ SG_ 981 ESP_a039_FrRWSSOpenOrShortToGnd "Electronic stability control: a039 fr RWSS open or short to gnd";
CM_ SG_ 981 ESP_a040_FrRWSSShortTo12V "Electronic stability control: a040 fr RWSS short to12 v";
CM_ SG_ 981 ESP_a041_FrRWSSLineInterruption "Electronic stability control: a041 fr RWSS line interruption";
CM_ SG_ 981 ESP_a042_FrRWSSMaxSpeedExceeded "Electronic stability control: a042 fr RWSS max speed exceeded";
CM_ SG_ 981 ESP_a043_FrRWSSTooManyPulses "Electronic stability control: a043 fr RWSS too many pulses";
CM_ SG_ 981 ESP_a044_FrRWSSLostSignal "Electronic stability control: a044 fr RWSS lost signal";
CM_ SG_ 981 ESP_a045_FrRWSSNoPulsesDetected "Electronic stability control: a045 fr RWSS no pulses detected";
CM_ SG_ 981 ESP_a046_FrRWSSWrongSensorType "Electronic stability control: a046 fr RWSS wrong sensor type";
CM_ SG_ 981 ESP_a047_FrRWSSSignalNoise "Electronic stability control: a047 fr RWSS signal noise";
CM_ SG_ 981 ESP_a048_FrRWSSVDiffFault "Electronic stability control: a048 fr RWSSV diff fault";
CM_ SG_ 981 ESP_a049_FrRWSSDirectionFault "Electronic stability control: a049 fr RWSS direction fault";
CM_ SG_ 981 ESP_a050_FrRWSSLargeAirGap "Electronic stability control: a050 fr RWSS large air gap";
CM_ SG_ 981 ESP_a051_FrRWSSSupplyShortToGnd "Electronic stability control: a051 fr RWSS supply short to gnd";
CM_ SG_ 981 ESP_a052_FrRWSSGeneralFault "Electronic stability control: a052 fr RWSS general fault";
CM_ SG_ 981 ESP_a053_ReLWSSOpenOrShortToGnd "Electronic stability control: a053 re LWSS open or short to gnd";
CM_ SG_ 981 ESP_a054_ReLWSSShortTo12V "Electronic stability control: a054 re LWSS short to12 v";
CM_ SG_ 981 ESP_a055_ReLWSSLineInterruption "Electronic stability control: a055 re LWSS line interruption";
CM_ SG_ 981 ESP_a056_ReLWSSMaxSpeedExceeded "Electronic stability control: a056 re LWSS max speed exceeded";
CM_ SG_ 981 ESP_a057_ReLWSSTooManyPulses "Electronic stability control: a057 re LWSS too many pulses";
CM_ SG_ 981 ESP_a058_ReLWSSLostSignal "Electronic stability control: a058 re LWSS lost signal";
CM_ SG_ 981 ESP_a059_ReLWSSNoPulsesDetected "Electronic stability control: a059 re LWSS no pulses detected";
CM_ SG_ 981 ESP_a060_ReLWSSWrongSensorType "Electronic stability control: a060 re LWSS wrong sensor type";
CM_ SG_ 981 ESP_a061_ReLWSSSignalNoise "Electronic stability control: a061 re LWSS signal noise";
CM_ SG_ 981 ESP_a062_ReLWSSVDiffFault "Electronic stability control: a062 re LWSSV diff fault";
CM_ SG_ 981 ESP_a063_ReLWSSDirectionFault "Electronic stability control: a063 re LWSS direction fault";
CM_ SG_ 981 ESP_a064_ReLWSSLargeAirGap "Electronic stability control: a064 re LWSS large air gap";
CM_ SG_ 981 ESP_a065_ReLWSSSupplyShortToGnd "Electronic stability control: a065 re LWSS supply short to gnd";
CM_ SG_ 981 ESP_a066_ReLWSSGeneralFault "Electronic stability control: a066 re LWSS general fault";
CM_ SG_ 981 ESP_a067_ReRWSSOpenOrShortToGnd "Electronic stability control: a067 re RWSS open or short to gnd";
CM_ SG_ 981 ESP_a068_ReRWSSShortTo12V "Electronic stability control: a068 re RWSS short to12 v";
CM_ SG_ 981 ESP_a069_ReRWSSLineInterruption "Electronic stability control: a069 re RWSS line interruption";
CM_ SG_ 981 ESP_a070_ReRWSSMaxSpeedExceeded "Electronic stability control: a070 re RWSS max speed exceeded";
CM_ SG_ 981 ESP_a071_ReRWSSTooManyPulses "Electronic stability control: a071 re RWSS too many pulses";
CM_ SG_ 981 ESP_a072_ReRWSSLostSignal "Electronic stability control: a072 re RWSS lost signal";
CM_ SG_ 981 ESP_a073_ReRWSSNoPulsesDetected "Electronic stability control: a073 re RWSS no pulses detected";
CM_ SG_ 981 ESP_a074_ReRWSSWrongSensorType "Electronic stability control: a074 re RWSS wrong sensor type";
CM_ SG_ 981 ESP_a075_ReRWSSSignalNoise "Electronic stability control: a075 re RWSS signal noise";
CM_ SG_ 981 ESP_a076_ReRWSSVDiffFault "Electronic stability control: a076 re RWSSV diff fault";
CM_ SG_ 981 ESP_a077_ReRWSSDirectionFault "Electronic stability control: a077 re RWSS direction fault";
CM_ SG_ 981 ESP_a078_ReRWSSLargeAirGap "Electronic stability control: a078 re RWSS large air gap";
CM_ SG_ 981 ESP_a079_ReRWSSSupplyShortToGnd "Electronic stability control: a079 re RWSS supply short to gnd";
CM_ SG_ 981 ESP_a080_ReRWSSGeneralFault "Electronic stability control: a080 re RWSS general fault";
CM_ SG_ 981 ESP_a081_PressureSensorShort "Electronic stability control: a081 pressure sensor short";
CM_ SG_ 981 ESP_a082_PMCSensorOffsetHigh "Electronic stability control: a082 PMC sensor offset high";
CM_ SG_ 981 ESP_a083_PMCSensorFault "Electronic stability control: a083 PMC sensor fault";
CM_ SG_ 981 ESP_a084_BrakeFluidReservoirLow "Electronic stability control: a084 brake fluid reservoir low";
CM_ SG_ 981 ESP_a085_BrakeSwitchStuckHigh "Electronic stability control: a085 brake switch stuck high";
CM_ SG_ 981 ESP_a086_BrakeSwitchImplausible1 "Electronic stability control: a086 brake switch implausible1";
CM_ SG_ 981 ESP_a087_BrakeSwitchImplausible3 "Electronic stability control: a087 brake switch implausible3";
CM_ SG_ 981 ESP_a088_absContinuousControl "Electronic stability control: a088 abs continuous control";
CM_ SG_ 981 ESP_a089_absNoPressureIncrease "Electronic stability control: a089 abs no pressure increase";
CM_ SG_ 981 ESP_a090_vdcContinuousControl "Electronic stability control: a090 vdc continuous control";
CM_ SG_ 981 ESP_a091_CANUndervoltage "Electronic stability control: a091 CAN undervoltage";
CM_ SG_ 981 ESP_a092_CANOvervoltage "Electronic stability control: a092 CAN overvoltage";
CM_ SG_ 981 ESP_a093_partyBusOff "Electronic stability control: a093 party bus off";
CM_ SG_ 981 ESP_a094_partyBusPassive "Electronic stability control: a094 party bus passive";
CM_ SG_ 981 ESP_a095_chassisBusOff "Electronic stability control: a095 chassis bus off";
CM_ SG_ 981 ESP_a096_chassisBusPassive "Electronic stability control: a096 chassis bus passive";
CM_ SG_ 981 ESP_a097_tcsRefSpeedNotInit "Electronic stability control: a097 tcs ref speed not init";
CM_ SG_ 981 ESP_a098_vdcRefSpeedNotInit "Electronic stability control: a098 vdc ref speed not init";
CM_ SG_ 981 ESP_a099_brakeTempModelOverheat "Electronic stability control: a099 brake temp model overheat";
CM_ SG_ 981 ESP_a100_brakeTempModelDisabled "Electronic stability control: a100 brake temp model disabled";
CM_ SG_ 981 ESP_a101_ebdFault "Electronic stability control: a101 ebd fault";
CM_ SG_ 981 ESP_a102_absFault "Electronic stability control: a102 abs fault";
CM_ SG_ 981 ESP_a103_stabilityControlFault "Electronic stability control: a103 stability control fault";
CM_ SG_ 981 ESP_a104_hbcEnabled "Electronic stability control: a104 hbc enabled";
CM_ SG_ 981 ESP_a105_ebrFault "Electronic stability control: a105 ebr fault";
CM_ SG_ 981 ESP_a106_vdcActuatorFault "Electronic stability control: a106 vdc actuator fault";
CM_ SG_ 981 ESP_a107_reserved107 "Electronic stability control: a107 reserved107";
CM_ SG_ 981 ESP_a108_reserved108 "Electronic stability control: a108 reserved108";
CM_ SG_ 981 ESP_a109_reserved109 "Electronic stability control: a109 reserved109";
CM_ SG_ 981 ESP_a110_rollerBenchActive "Electronic stability control: a110 roller bench active";
CM_ SG_ 981 ESP_a111_absActive "Electronic stability control: a111 abs active";
CM_ SG_ 981 ESP_a112_espActive "Electronic stability control: a112 esp active";
CM_ SG_ 981 ESP_a113_btcActive "Electronic stability control: a113 btc active";
CM_ SG_ 981 ESP_a114_tvdcActive "Electronic stability control: a114 tvdc active";
CM_ SG_ 981 ESP_a115_ebdActive "Electronic stability control: a115 ebd active";
CM_ SG_ 981 ESP_a116_tsmActive "Electronic stability control: a116 tsm active";
CM_ SG_ 981 ESP_a117_hbaActive "Electronic stability control: a117 hba active";
CM_ SG_ 981 ESP_a118_hfcActive "Electronic stability control: a118 hfc active";
CM_ SG_ 981 ESP_a119_hbbActive "Electronic stability control: a119 hbb active";
CM_ SG_ 981 ESP_a120_rmiActive "Electronic stability control: a120 rmi active";
CM_ SG_ 981 ESP_a121_regenTcActive "Electronic stability control: a121 regen tc active";
CM_ SG_ 981 ESP_a122_bdwActive "Electronic stability control: a122 bdw active";
CM_ SG_ 981 ESP_a123_ebrActive "Electronic stability control: a123 ebr active";
CM_ SG_ 981 ESP_a124_ebrSkidActive "Electronic stability control: a124 ebr skid active";
CM_ SG_ 981 ESP_a125_reserved125 "Electronic stability control: a125 reserved125";
CM_ SG_ 981 ESP_a126_reserved126 "Electronic stability control: a126 reserved126";
CM_ SG_ 981 ESP_a127_reserved127 "Electronic stability control: a127 reserved127";
CM_ SG_ 981 ESP_a128_reserved128 "Electronic stability control: a128 reserved128";
CM_ SG_ 981 ESP_a129_reserved129 "Electronic stability control: a129 reserved129";
CM_ SG_ 981 ESP_a130_EPAS3PsysStatusTimeout "Electronic stability control: a130 EPAS3 psys status timeout";
CM_ SG_ 981 ESP_a131_EPAS3PsysStatusDLC "Electronic stability control: a131 EPAS3 psys status DLC";
CM_ SG_ 981 ESP_a132_EPAS3PsysStatusChecksum "Electronic stability control: a132 EPAS3 psys status checksum";
CM_ SG_ 981 ESP_a133_EPAS3PsysStatusCounter "Electronic stability control: a133 EPAS3 psys status counter";
CM_ SG_ 981 ESP_a134_steeringAngleInvalid "Electronic stability control: a134 steering angle invalid";
CM_ SG_ 981 ESP_a135_steeringAngleNoCenter "Electronic stability control: a135 steering angle no center";
CM_ SG_ 981 ESP_a136_steeringAngleFrozen "Electronic stability control: a136 steering angle frozen";
CM_ SG_ 981 ESP_a137_steeringOffsetTooLarge "Electronic stability control: a137 steering offset too large";
CM_ SG_ 981 ESP_a138_steeringAngleImplaus "Electronic stability control: a138 steering angle implaus";
CM_ SG_ 981 ESP_a139_steeringAngleWrongSign "Electronic stability control: a139 steering angle wrong sign";
CM_ SG_ 981 ESP_a140_RCMInertial1Timeout "Electronic stability control: a140 RCM inertial1 timeout";
CM_ SG_ 981 ESP_a141_RCMInertial1DLC "Electronic stability control: a141 RCM inertial1 DLC";
CM_ SG_ 981 ESP_a142_RCMInertial1Checksum "Electronic stability control: a142 RCM inertial1 checksum";
CM_ SG_ 981 ESP_a143_RCMInertial1Counter "Electronic stability control: a143 RCM inertial1 counter";
CM_ SG_ 981 ESP_a144_yawMaxLatency "Electronic stability control: a144 yaw max latency";
CM_ SG_ 981 ESP_a145_yawInitFault "Electronic stability control: a145 yaw init fault";
CM_ SG_ 981 ESP_a146_yawInvalidValue "Electronic stability control: a146 yaw invalid value";
CM_ SG_ 981 ESP_a147_yawSensorNotAvailable "Electronic stability control: a147 yaw sensor not available";
CM_ SG_ 981 ESP_a148_yawSignalFault "Electronic stability control: a148 yaw signal fault";
CM_ SG_ 981 ESP_a149_yawInvalidSign "Electronic stability control: a149 yaw invalid sign";
CM_ SG_ 981 ESP_a150_yawImplausible "Electronic stability control: a150 yaw implausible";
CM_ SG_ 981 ESP_a151_RCMInertial2Timeout "Electronic stability control: a151 RCM inertial2 timeout";
CM_ SG_ 981 ESP_a152_RCMInertial2DLC "Electronic stability control: a152 RCM inertial2 DLC";
CM_ SG_ 981 ESP_a153_RCMInertial2Checksum "Electronic stability control: a153 RCM inertial2 checksum";
CM_ SG_ 981 ESP_a154_RCMInertial2Counter "Electronic stability control: a154 RCM inertial2 counter";
CM_ SG_ 981 ESP_a155_ayMaxLatency "Electronic stability control: a155 ay max latency";
CM_ SG_ 981 ESP_a156_ayInitFault "Electronic stability control: a156 ay init fault";
CM_ SG_ 981 ESP_a157_ayInvalidValue "Electronic stability control: a157 ay invalid value";
CM_ SG_ 981 ESP_a158_aySensorNotAvailable "Electronic stability control: a158 ay sensor not available";
CM_ SG_ 981 ESP_a159_aySignalFault "Electronic stability control: a159 ay signal fault";
CM_ SG_ 981 ESP_a160_ayRangeExceeded "Electronic stability control: a160 ay range exceeded";
CM_ SG_ 981 ESP_a161_ayOffsetExceeded "Electronic stability control: a161 ay offset exceeded";
CM_ SG_ 981 ESP_a162_ayImplausible "Electronic stability control: a162 ay implausible";
CM_ SG_ 981 ESP_a163_axMaxLatency "Electronic stability control: a163 ax max latency";
CM_ SG_ 981 ESP_a164_axInitFault "Electronic stability control: a164 ax init fault";
CM_ SG_ 981 ESP_a165_axInvalidValue "Electronic stability control: a165 ax invalid value";
CM_ SG_ 981 ESP_a166_axSensorNotAvailable "Electronic stability control: a166 ax sensor not available";
CM_ SG_ 981 ESP_a167_axSignalFault "Electronic stability control: a167 ax signal fault";
CM_ SG_ 981 ESP_a168_axRangeExceeded "Electronic stability control: a168 ax range exceeded";
CM_ SG_ 981 ESP_a169_axOffsetExceeded "Electronic stability control: a169 ax offset exceeded";
CM_ SG_ 981 ESP_a170_axSignalFrozen "Electronic stability control: a170 ax signal frozen";
CM_ SG_ 981 ESP_a171_axImplausible "Electronic stability control: a171 ax implausible";
CM_ SG_ 981 ESP_a172_IBSTparty1Timeout "Electronic stability control: a172 IBS tparty1 timeout";
CM_ SG_ 981 ESP_a173_IBSTparty1DLC "Electronic stability control: a173 IBS tparty1 DLC";
CM_ SG_ 981 ESP_a174_IBSTparty1Checksum "Electronic stability control: a174 IBS tparty1 checksum";
CM_ SG_ 981 ESP_a175_IBSTparty1Counter "Electronic stability control: a175 IBS tparty1 counter";
CM_ SG_ 981 ESP_a176_IBSTEBRNotAvailable "Electronic stability control: a176 IBSTEBR not available";
CM_ SG_ 981 ESP_a177_IBSTOutputRodDrvInvalid "Electronic stability control: a177 IBST output rod drv invalid";
CM_ SG_ 981 ESP_a178_IBSTOutputRodActInvalid "Electronic stability control: a178 IBST output rod act invalid";
CM_ SG_ 981 ESP_a179_IBSTparty2Timeout "Electronic stability control: a179 IBS tparty2 timeout";
CM_ SG_ 981 ESP_a180_IBSTparty2Checksum "Electronic stability control: a180 IBS tparty2 checksum";
CM_ SG_ 981 ESP_a181_IBSTparty2DLC "Electronic stability control: a181 IBS tparty2 DLC";
CM_ SG_ 981 ESP_a182_IBSTparty2Counter "Electronic stability control: a182 IBS tparty2 counter";
CM_ SG_ 981 ESP_a183_IBSTStatusOff "Electronic stability control: a183 IBST status off";
CM_ SG_ 981 ESP_a184_IBSTpRunoutInvalid "Electronic stability control: a184 IBS tp runout invalid";
CM_ SG_ 981 ESP_a185_IBSTFeedforwardBackup "Electronic stability control: a185 IBST feedforward backup";
CM_ SG_ 981 ESP_a186_IBSTBrakeAppliedInvalid "Electronic stability control: a186 IBST brake applied invalid";
CM_ SG_ 981 ESP_a187_DIbtcRequestTimeout "Electronic stability control: a187 d ibtc request timeout";
CM_ SG_ 981 ESP_a188_DIbtcRequestDLC "Electronic stability control: a188 d ibtc request DLC";
CM_ SG_ 981 ESP_a189_DIbtcRequestChecksum "Electronic stability control: a189 d ibtc request checksum";
CM_ SG_ 981 ESP_a190_DIbtcRequestCounter "Electronic stability control: a190 d ibtc request counter";
CM_ SG_ 981 ESP_a191_DIchassisControlTimeout "Electronic stability control: a191 d ichassis control timeout";
CM_ SG_ 981 ESP_a192_DIchassisControlDLC "Electronic stability control: a192 d ichassis control DLC";
CM_ SG_ 981 ESP_a193_DIchassisControlChecksu "Electronic stability control: a193 d ichassis control checksum";
CM_ SG_ 981 ESP_a194_DIchassisControlCounter "Electronic stability control: a194 d ichassis control counter";
CM_ SG_ 981 ESP_a195_ptcStateInvalid "Electronic stability control: a195 ptc state invalid";
CM_ SG_ 981 ESP_a196_DIsystemStatusTimeout "Electronic stability control: a196 d isystem status timeout";
CM_ SG_ 981 ESP_a197_DIsystemStatusDLC "Electronic stability control: a197 d isystem status DLC";
CM_ SG_ 981 ESP_a198_DIsystemStatusChecksum "Electronic stability control: a198 d isystem status checksum";
CM_ SG_ 981 ESP_a199_DIsystemStatusCounter "Electronic stability control: a199 d isystem status counter";
CM_ SG_ 981 ESP_a200_reverseGearStuckHigh "Electronic stability control: a200 reverse gear stuck high";
CM_ SG_ 981 ESP_a201_reverseGearStuckLow "Electronic stability control: a201 reverse gear stuck low";
CM_ SG_ 981 ESP_a202_accelPedalInvalid "Electronic stability control: a202 accel pedal invalid";
CM_ SG_ 981 ESP_a203_DItorqueTimeout "Electronic stability control: a203 d itorque timeout";
CM_ SG_ 981 ESP_a204_DItorqueDLC "Electronic stability control: a204 d itorque DLC";
CM_ SG_ 981 ESP_a205_DItorqueChecksum "Electronic stability control: a205 d itorque checksum";
CM_ SG_ 981 ESP_a206_DItorqueCounter "Electronic stability control: a206 d itorque counter";
CM_ SG_ 981 ESP_a207_DITorqueCommandInvalid "Electronic stability control: a207 DI torque command invalid";
CM_ SG_ 981 ESP_a208_DIRPMInvalid "Electronic stability control: a208 DIRPM invalid";
CM_ SG_ 981 ESP_a209_DITorqueActualInvalid "Electronic stability control: a209 DI torque actual invalid";
CM_ SG_ 981 ESP_a210_DIStorqueTimeout "Electronic stability control: a210 DI storque timeout";
CM_ SG_ 981 ESP_a211_DIStorqueDLC "Electronic stability control: a211 DI storque DLC";
CM_ SG_ 981 ESP_a212_DIStorqueChecksum "Electronic stability control: a212 DI storque checksum";
CM_ SG_ 981 ESP_a213_DIStorqueCounter "Electronic stability control: a213 DI storque counter";
CM_ SG_ 981 ESP_a214_DISTorqueCommandInvalid "Electronic stability control: a214 DIS torque command invalid";
CM_ SG_ 981 ESP_a215_DISRPMInvalid "Electronic stability control: a215 DISRPM invalid";
CM_ SG_ 981 ESP_a216_DISTorqueActualInvalid "Electronic stability control: a216 DIS torque actual invalid";
CM_ SG_ 981 ESP_a217_DIvdcLeftTimeout "Electronic stability control: a217 d ivdc left timeout";
CM_ SG_ 981 ESP_a218_DIvdcLeftDLC "Electronic stability control: a218 d ivdc left DLC";
CM_ SG_ 981 ESP_a219_DIvdcLeftChecksum "Electronic stability control: a219 d ivdc left checksum";
CM_ SG_ 981 ESP_a220_DIvdcLeftCounter "Electronic stability control: a220 d ivdc left counter";
CM_ SG_ 981 ESP_a221_DIvdcRightTimeout "Electronic stability control: a221 d ivdc right timeout";
CM_ SG_ 981 ESP_a222_DIvdcRightDLC "Electronic stability control: a222 d ivdc right DLC";
CM_ SG_ 981 ESP_a223_DIvdcRightChecksum "Electronic stability control: a223 d ivdc right checksum";
CM_ SG_ 981 ESP_a224_DIvdcRightCounter "Electronic stability control: a224 d ivdc right counter";
CM_ SG_ 981 ESP_a225_configMismatch "Electronic stability control: a225 config mismatch";
CM_ SG_ 981 ESP_a226_bdwRequestInvalid "Electronic stability control: a226 bdw request invalid";
CM_ SG_ 981 ESP_a227_bdwRequestActiveInvalid "Electronic stability control: a227 bdw request active invalid";
CM_ SG_ 981 ESP_a228_GTWvinTimeout "Electronic stability control: a228 GT wvin timeout";
CM_ SG_ 981 ESP_a229_GTWvinDLC "Electronic stability control: a229 GT wvin DLC";
CM_ SG_ 981 ESP_a230_vinNotLearned "Electronic stability control: a230 vin not learned";
CM_ SG_ 981 ESP_a231_storedVINMismatch "Electronic stability control: a231 stored VIN mismatch";
CM_ SG_ 981 ESP_a232_PMstate2Timeout "Electronic stability control: a232 p mstate2 timeout";
CM_ SG_ 981 ESP_a233_PMstate2Checksum "Electronic stability control: a233 p mstate2 checksum";
CM_ SG_ 981 ESP_a234_PMstate2DLC "Electronic stability control: a234 p mstate2 DLC";
CM_ SG_ 981 ESP_a235_PMstate2Counter "Electronic stability control: a235 p mstate2 counter";
CM_ SG_ 981 ESP_a236_ebrCommandStateInvalid "Electronic stability control: a236 ebr command state invalid";
CM_ SG_ 981 ESP_a237_vdcCommandStateInvalid "Electronic stability control: a237 vdc command state invalid";
CM_ SG_ 981 ESP_a238_UIodoTimeout "Electronic stability control: a238 u iodo timeout";
CM_ SG_ 981 ESP_a239_UIodoDLC "Electronic stability control: a239 u iodo DLC";
CM_ SG_ 981 ESP_a240_LVPowerStateTimeout "Electronic stability control: a240 LV power state timeout";
CM_ SG_ 981 ESP_a241_LVPowerStateChecksum "Electronic stability control: a241 LV power state checksum";
CM_ SG_ 981 ESP_a242_LVPowerStateDLC "Electronic stability control: a242 LV power state DLC";
CM_ SG_ 981 ESP_a243_LVPowerStateCounter "Electronic stability control: a243 LV power state counter";
CM_ SG_ 981 ESP_a244_LVOffStateInvalid "Electronic stability control: a244 LV off state invalid";
CM_ SG_ 981 ESP_a245_LVGoingDownStateInvalid "Electronic stability control: a245 LV going down state invalid";
CM_ SG_ 981 ESP_a246_VCFRONTsensorTimeout "Electronic stability control: a246 VCFRON tsensor timeout";
CM_ SG_ 981 ESP_a247_VCFRONTsensorDLC "Electronic stability control: a247 VCFRON tsensor DLC";
CM_ SG_ 981 ESP_a248_vdcBrkeTrqTarFrLInvalid "Electronic stability control: a248 vdc brke trq tar fr l invalid";
CM_ SG_ 981 ESP_a249_vdcBrkeTrqTarFrRInvalid "Electronic stability control: a249 vdc brke trq tar fr r invalid";
CM_ SG_ 981 ESP_a250_vdcBrkeTrqTarReLInvalid "Electronic stability control: a250 vdc brke trq tar re l invalid";
CM_ SG_ 981 ESP_a251_vdcBrkeTrqTarReRInvalid "Electronic stability control: a251 vdc brke trq tar re r invalid";
CM_ SG_ 981 ESP_a252_vdcWhlSlipLimFrLInvalid "Electronic stability control: a252 vdc whl slip lim fr l invalid";
CM_ SG_ 981 ESP_a253_vdcWhlSlipLimFrRInvalid "Electronic stability control: a253 vdc whl slip lim fr r invalid";
CM_ SG_ 981 ESP_a254_vdcWhlSlipLimReLInvalid "Electronic stability control: a254 vdc whl slip lim re l invalid";
CM_ SG_ 981 ESP_a255_vdcWhlSlipLimReRInvalid "Electronic stability control: a255 vdc whl slip lim re r invalid";
CM_ SG_ 981 ESP_a256_epbmStatusTimeout "Electronic stability control: a256 epbm status timeout";
CM_ SG_ 981 ESP_a257_epbmStatusChecksum "Electronic stability control: a257 epbm status checksum";
CM_ SG_ 981 ESP_a258_epbmStatusDLC "Electronic stability control: a258 epbm status DLC";
CM_ SG_ 981 ESP_a259_epbmStatusCounter "Electronic stability control: a259 epbm status counter";
CM_ SG_ 981 ESP_a260_epblStatusTimeout "Electronic stability control: a260 epbl status timeout";
CM_ SG_ 981 ESP_a261_epblStatusChecksum "Electronic stability control: a261 epbl status checksum";
CM_ SG_ 981 ESP_a262_epblStatusDLC "Electronic stability control: a262 epbl status DLC";
CM_ SG_ 981 ESP_a263_epblStatusCounter "Electronic stability control: a263 epbl status counter";
CM_ SG_ 981 ESP_a264_pumpSpeedLimitInvalid "Electronic stability control: a264 pump speed limit invalid";
CM_ SG_ 981 ESP_a265_DIRELtorqueTimeout "Electronic stability control: a265 DIRE ltorque timeout";
CM_ SG_ 981 ESP_a266_DIRELtorqueDLC "Electronic stability control: a266 DIRE ltorque DLC";
CM_ SG_ 981 ESP_a267_DIRELtorqueChecksum "Electronic stability control: a267 DIRE ltorque checksum";
CM_ SG_ 981 ESP_a268_DIRELtorqueCounter "Electronic stability control: a268 DIRE ltorque counter";
CM_ SG_ 981 ESP_a269_DIRELTorqueCommandInval "Electronic stability control: a269 DIREL torque command invalid";
CM_ SG_ 981 ESP_a270_DIRELRPMInvalid "Electronic stability control: a270 DIRELRPM invalid";
CM_ SG_ 981 ESP_a271_DIRELTorqueActualInvali "Electronic stability control: a271 DIREL torque actual invalid";
CM_ SG_ 981 ESP_a272_DIRERtorqueTimeout "Electronic stability control: a272 DIRE rtorque timeout";
CM_ SG_ 981 ESP_a273_DIRERtorqueDLC "Electronic stability control: a273 DIRE rtorque DLC";
CM_ SG_ 981 ESP_a274_DIRERtorqueChecksum "Electronic stability control: a274 DIRE rtorque checksum";
CM_ SG_ 981 ESP_a275_DIRERtorqueCounter "Electronic stability control: a275 DIRE rtorque counter";
CM_ SG_ 981 ESP_a276_DIRERTorqueCommandInval "Electronic stability control: a276 DIRER torque command invalid";
CM_ SG_ 981 ESP_a277_DIRERRPMInvalid "Electronic stability control: a277 DIRERRPM invalid";
CM_ SG_ 981 ESP_a278_DIRERTorqueActualInvali "Electronic stability control: a278 DIRER torque actual invalid";
CM_ SG_ 981 ESP_a279_lifetimeManagementOverr "Electronic stability control: a279 lifetime management overrun";
CM_ SG_ 981 ESP_a280_trackModeABSEnabled "Electronic stability control: a280 track mode ABS enabled";
CM_ SG_ 981 ESP_a281_trackModeABSdisabled "Electronic stability control: a281 track mode AB sdisabled";
CM_ SG_ 981 ESP_a282_trackModeABSRequestInva "Electronic stability control: a282 track mode ABS request invalid";
CM_ SG_ 981 ESP_a283_secondaryCollisionMitig "Electronic stability control: a283 secondary collision mitigation active";
CM_ SG_ 981 ESP_a284_scmRequestInvalidChecks "Electronic stability control: a284 scm request invalid checksum";
CM_ SG_ 981 ESP_a285_scmRequestDLC "Electronic stability control: a285 scm request DLC";
CM_ SG_ 981 ESP_a286_hydroplaneDetected "Electronic stability control: a286 hydroplane detected";
CM_ SG_ 981 ESP_a287_failedBrakeCircuitDetec "Electronic stability control: a287 failed brake circuit detected";
CM_ SG_ 981 ESP_a288_leftBusOff "Electronic stability control: a288 left bus off";
CM_ SG_ 981 ESP_a289_leftBusPassive "Electronic stability control: a289 left bus passive";
CM_ SG_ 981 ESP_a290_brakeBusOff "Electronic stability control: a290 brake bus off";
CM_ SG_ 981 ESP_a291_brakeBusPassive "Electronic stability control: a291 brake bus passive";
CM_ SG_ 981 ESP_a292_PEPSstatusTimeout "Electronic stability control: a292 PEP sstatus timeout";
CM_ SG_ 981 ESP_a293_PEPSstatusDLC "Electronic stability control: a293 PEP sstatus DLC";
CM_ SG_ 981 ESP_a294_PEPSstatusChecksum "Electronic stability control: a294 PEP sstatus checksum";
CM_ SG_ 981 ESP_a295_PEPSstatusCounter "Electronic stability control: a295 PEP sstatus counter";
CM_ SG_ 981 ESP_a296_roadWheelAngleHealthDeg "Electronic stability control: a296 road wheel angle health degraded";
CM_ SG_ 981 ESP_a297_roadWheelAngleHealthFau "Electronic stability control: a297 road wheel angle health faulted";
CM_ SG_ 981 ESP_a298_RSArearSteerStatusTimeo "Electronic stability control: a298 RS arear steer status timeout";
CM_ SG_ 981 ESP_a299_RSArearSteerStatusDLC "Electronic stability control: a299 RS arear steer status DLC";
CM_ SG_ 981 ESP_a300_RSArearSteerStatusCheck "Electronic stability control: a300 RS arear steer status checksum";
CM_ SG_ 981 ESP_a301_PEPSstatusCounter "Electronic stability control: a301 PEP sstatus counter";
CM_ SG_ 981 ESP_a302_rearRoadWheelAngleHealt "Electronic stability control: a302 rear road wheel angle health degraded";
CM_ SG_ 981 ESP_a303_rearRoadWheelAngleHealt "Electronic stability control: a303 rear road wheel angle health faulted";
CM_ SG_ 981 ESP_a304_rearVCLVPowerStateTimeo "Electronic stability control: a304 rear VCLV power state timeout";
CM_ SG_ 981 ESP_a305_rearVCLVPowerStateDLC "Electronic stability control: a305 rear VCLV power state DLC";
CM_ SG_ 981 ESP_a306_rearVCLVPowerStateCheck "Electronic stability control: a306 rear VCLV power state checksum";
CM_ SG_ 981 ESP_a307_rearVCLVPowerStateCount "Electronic stability control: a307 rear VCLV power state counter";
CM_ SG_ 981 ESP_a308_evacFillNotComplete "Electronic stability control: a308 evac fill not complete";
CM_ SG_ 981 ESP_a309_factoryModeActive "Electronic stability control: a309 factory mode active";
CM_ SG_ 981 ESP_a310_brakeLatencyReductionAc "Electronic stability control: a310 brake latency reduction active";
CM_ SG_ 981 ESP_a311_aesActive "Electronic stability control: a311 aes active";
CM_ SG_ 981 ESP_a312_undefinedAlertDetected "Electronic stability control: a312 undefined alert detected";
CM_ SG_ 981 ESP_a313_cdpRequestStateInvalid "Electronic stability control: a313 cdp request state invalid";
CM_ SG_ 981 ESP_a314_aesFault "Electronic stability control: a314 aes fault";
CM_ SG_ 981 ESP_a315_EMCBackup11Timeout "Electronic stability control: a315 EMC backup11 timeout";
CM_ SG_ 981 ESP_a316_EMCBackup11DLC "Electronic stability control: a316 EMC backup11 DLC";
CM_ SG_ 981 ESP_a317_EMCBackup11Checksum "Electronic stability control: a317 EMC backup11 checksum";
CM_ SG_ 981 ESP_a318_EMCBackup11Counter "Electronic stability control: a318 EMC backup11 counter";
CM_ SG_ 981 ESP_a319_AES_BackupActuatorActiv "Electronic stability control: a319 AES backup actuator active";
CM_ SG_ 981 ESP_a320_DPB_actuator1Counter "Electronic stability control: a320 DPB actuator1 counter";
CM_ SG_ 981 ESP_a321_DPB_actuator1Checksum "Electronic stability control: a321 DPB actuator1 checksum";
CM_ SG_ 981 ESP_a322_DPB_actuator1DLC "Electronic stability control: a322 DPB actuator1 DLC";
CM_ SG_ 981 ESP_a323_DPB_actuator1Timeout "Electronic stability control: a323 DPB actuator1 timeout";
CM_ SG_ 981 ESP_a324_DPB_actuator2Counter "Electronic stability control: a324 DPB actuator2 counter";
CM_ SG_ 981 ESP_a325_DPB_actuator2Checksum "Electronic stability control: a325 DPB actuator2 checksum";
CM_ SG_ 981 ESP_a326_DPB_actuator2DLC "Electronic stability control: a326 DPB actuator2 DLC";
CM_ SG_ 981 ESP_a327_DPB_actuator2Timeout "Electronic stability control: a327 DPB actuator2 timeout";
CM_ SG_ 981 ESP_a328_DPB_actuator3Counter "Electronic stability control: a328 DPB actuator3 counter";
CM_ SG_ 981 ESP_a329_DPB_actuator3Checksum "Electronic stability control: a329 DPB actuator3 checksum";
CM_ SG_ 981 ESP_a330_DPB_actuator3DLC "Electronic stability control: a330 DPB actuator3 DLC";
CM_ SG_ 981 ESP_a331_DPB_actuator3Timeout "Electronic stability control: a331 DPB actuator3 timeout";
CM_ SG_ 981 ESP_a332_PressureSensorValHigh "Electronic stability control: a332 pressure sensor val high";
CM_ SG_ 981 ESP_a333_ActCircuitNoPressure "Electronic stability control: a333 act circuit no pressure";
CM_ SG_ 981 ESP_a334_BrakePedalAppliedInvali "Electronic stability control: a334 brake pedal applied invalid";
CM_ SG_ 981 ESP_a335_LdmFxTarBrakeActInvalid "Electronic stability control: a335 ldm fx tar brake act invalid";
CM_ SG_ 981 ESP_a336_FxTargetDriverInvalid "Electronic stability control: a336 fx target driver invalid";
CM_ SG_ 981 ESP_a337_pReductionPotentialInva "Electronic stability control: a337 p reduction potential invalid";
CM_ SG_ 981 ESP_a338_pRunoutInvalid "Electronic stability control: a338 p runout invalid";
CM_ SG_ 981 ESP_a339_sInputRodInvalid "Electronic stability control: a339 s input rod invalid";
CM_ SG_ 981 ESP_a340_RollerBenchMisuse "Electronic stability control: a340 roller bench misuse";
CM_ SG_ 981 ESP_a341_EnhancedPressureBuildAc "Electronic stability control: a341 enhanced pressure build active";
CM_ SG_ 981 ESP_a342_EnhancedPressureBuildNo "Electronic stability control: a342 enhanced pressure build not available";
CM_ SG_ 981 ESP_a343_EnhancedPressureBuildLt "Electronic stability control: a343 enhanced pressure build ltm reached";
CM_ SG_ 981 ESP_a344_DIbrakeCommandCounter "Electronic stability control: a344 d ibrake command counter";
CM_ SG_ 981 ESP_a345_DIbrakeCommandChecksum "Electronic stability control: a345 d ibrake command checksum";
CM_ SG_ 981 ESP_a346_DIbrakeCommandDLC "Electronic stability control: a346 d ibrake command DLC";
CM_ SG_ 981 ESP_a347_DIbrakeCommandTimeout "Electronic stability control: a347 d ibrake command timeout";
CM_ SG_ 981 ESP_a348_brakeCmdStateInvalid "Electronic stability control: a348 brake cmd state invalid";
CM_ SG_ 981 ESP_a349_ForceLampToRed "Electronic stability control: a349 force lamp to red";
CM_ SG_ 981 ESP_a350_ActuatorOff "Electronic stability control: a350 actuator off";
CM_ SG_ 981 ESP_a351_ActuatorYellowLampReque "Electronic stability control: a351 actuator yellow lamp requested";
CM_ SG_ 981 ESP_a352_ActuatorLDMFailure "Electronic stability control: a352 actuator LDM failure";
CM_ SG_ 981 ESP_a353_PressureSensorImplausHi "Electronic stability control: a353 pressure sensor implaus high";
CM_ SG_ 981 ESP_a354_HBCRequestInvalid "Electronic stability control: a354 HBC request invalid";
CM_ SG_ 981 ESP_a355_RecuStatusActInvalid "Electronic stability control: a355 recu status act invalid";
CM_ SG_ 981 ESP_a356_DIFAxleTorqueInvalid "Electronic stability control: a356 DIF axle torque invalid";
CM_ SG_ 981 ESP_a357_DIRAxleTorqueInvalid "Electronic stability control: a357 DIR axle torque invalid";
CM_ SG_ 981 ESP_a358_externalActuatorFallbac "Electronic stability control: a358 external actuator fallback";
CM_ SG_ 981 ESP_a359_externalActuatorNoExtRe "Electronic stability control: a359 external actuator no ext req";
CM_ SG_ 981 ESP_a360_BBbrakeActuationTimeout "Electronic stability control: a360 b bbrake actuation timeout";
CM_ SG_ 981 ESP_a361_BBbrakeActuationDLC "Electronic stability control: a361 b bbrake actuation DLC";
CM_ SG_ 981 ESP_a362_BBbrakeActuationChecksu "Electronic stability control: a362 b bbrake actuation checksum";
CM_ SG_ 981 ESP_a363_BBbrakeActuationCounter "Electronic stability control: a363 b bbrake actuation counter";
CM_ SG_ 981 ESP_a364_DIgearInvalid "Electronic stability control: a364 d igear invalid";
CM_ SG_ 981 ESP_a365_TCSInputQualityTooLow "Electronic stability control: a365 TCS input quality too low";
CM_ SG_ 981 ESP_a366_ActuatorBlendingModeReq "Electronic stability control: a366 actuator blending mode req not available";
CM_ SG_ 981 ESP_a367_CBDS_fillBufferThreshol "Electronic stability control: a367 CBDS fill buffer threshold";
CM_ SG_ 981 ESP_a368_CBDS_fmeInternalEvent "Electronic stability control: a368 CBDS fme internal event";
CM_ SG_ 981 ESP_a369_LargeLeakageDetectedByD "Electronic stability control: a369 large leakage detected by DPB";
CM_ SG_ 981 ESP_a370_DPB_actuator4Timeout "Electronic stability control: a370 DPB actuator4 timeout";
CM_ SG_ 981 ESP_a371_DPB_actuator4DLC "Electronic stability control: a371 DPB actuator4 DLC";
CM_ SG_ 981 ESP_a372_DPB_actuator4Checksum "Electronic stability control: a372 DPB actuator4 checksum";
CM_ SG_ 981 ESP_a373_DPB_actuator4Counter "Electronic stability control: a373 DPB actuator4 counter";
CM_ SG_ 981 ESP_a374_StatInvalid_DI_FullSNA "Electronic stability control: a374 stat invalid DI full SNA";
CM_ SG_ 981 ESP_a375_PM_locStateCounter "Electronic stability control: a375 PM loc state counter";
CM_ SG_ 981 ESP_a376_PM_locStateChecksum "Electronic stability control: a376 PM loc state checksum";
CM_ SG_ 981 ESP_a377_PM_locStateDLC "Electronic stability control: a377 PM loc state DLC";
CM_ SG_ 981 ESP_a378_PM_locStateTimeout "Electronic stability control: a378 PM loc state timeout";
CM_ SG_ 981 ESP_a379_DASredundantBrakingCont "Electronic stability control: a379 DA sredundant braking control party checksum";
CM_ SG_ 981 ESP_a380_DASredundantBrakingCont "Electronic stability control: a380 DA sredundant braking control party counter";
CM_ SG_ 981 ESP_a381_DASredundantBrakingCont "Electronic stability control: a381 DA sredundant braking control party DLC";
CM_ SG_ 981 ESP_a382_DASredundantBrakingCont "Electronic stability control: a382 DA sredundant braking control party timeout";
CM_ SG_ 981 ESP_a383_DASredundantBrakingCont "Electronic stability control: a383 DA sredundant braking control chassis checksum";
CM_ SG_ 981 ESP_a384_DASredundantBrakingCont "Electronic stability control: a384 DA sredundant braking control chassis counter";
CM_ SG_ 981 ESP_a385_DASredundantBrakingCont "Electronic stability control: a385 DA sredundant braking control chassis DLC";
CM_ SG_ 981 ESP_a386_DASredundantBrakingCont "Electronic stability control: a386 DA sredundant braking control chassis timeout";
CM_ SG_ 981 ESP_a387_DIlocStatus2Checksum "Electronic stability control: a387 d iloc status2 checksum";
CM_ SG_ 981 ESP_a388_DIlocStatus2Counter "Electronic stability control: a388 d iloc status2 counter";
CM_ SG_ 981 ESP_a389_DIlocStatus2DLC "Electronic stability control: a389 d iloc status2 DLC";
CM_ SG_ 981 ESP_a390_DIlocStatus2Timeout "Electronic stability control: a390 d iloc status2 timeout";
CM_ SG_ 981 ESP_a391_standaloneEBRActive "Electronic stability control: a391 standalone EBR active";
CM_ SG_ 981 ESP_a392_driverlessArmingUnavail "Electronic stability control: a392 driverless arming unavailable";
CM_ SG_ 981 ESP_a393_EMCBackup21Checksum "Electronic stability control: a393 EMC backup21 checksum";
CM_ SG_ 981 ESP_a394_EMCBackup21Counter "Electronic stability control: a394 EMC backup21 counter";
CM_ SG_ 981 ESP_a395_EMCBackup21DLC "Electronic stability control: a395 EMC backup21 DLC";
CM_ SG_ 981 ESP_a396_EMCBackup21Timeout "Electronic stability control: a396 EMC backup21 timeout";
CM_ SG_ 981 ESP_a397_epbrStatusTimeout "Electronic stability control: a397 epbr status timeout";
CM_ SG_ 981 ESP_a398_epbrStatusChecksum "Electronic stability control: a398 epbr status checksum";
CM_ SG_ 981 ESP_a399_epbrStatusDLC "Electronic stability control: a399 epbr status DLC";
CM_ SG_ 981 ESP_a400_epbrStatusCounter "Electronic stability control: a400 epbr status counter";
CM_ SG_ 981 ESP_a401_bsmCircuitFailure "Electronic stability control: a401 bsm circuit failure";
CM_ SG_ 981 ESP_a402_bsmPtsPlausToPsTooHigh "Electronic stability control: a402 bsm pts plaus to ps too high";
CM_ SG_ 981 ESP_a403_batMotorVoltage "Electronic stability control: a403 bat motor voltage";
CM_ SG_ 981 ESP_a404_batPressureCircuit1 "Electronic stability control: a404 bat pressure circuit1";
CM_ SG_ 981 ESP_a405_batPressureCircuit2 "Electronic stability control: a405 bat pressure circuit2";
CM_ SG_ 981 ESP_a406_DIespActuatorTestTimeou "Electronic stability control: a406 d iesp actuator test timeout";
CM_ SG_ 981 ESP_a407_DIespActuatorTestChecks "Electronic stability control: a407 d iesp actuator test checksum";
CM_ SG_ 981 ESP_a408_DIespActuatorTestDLC "Electronic stability control: a408 d iesp actuator test DLC";
CM_ SG_ 981 ESP_a409_DIespActuatorTestCounte "Electronic stability control: a409 d iesp actuator test counter";
CM_ BO_ 805 "Electronic stability control message: info; frame length from the layout, not yet observed on a vehicle bus";
CM_ SG_ 805 ESP_infoIndex "Electronic stability control: info index";
CM_ SG_ 805 ESP_infoBuildType "Electronic stability control: info build type";
CM_ SG_ 805 ESP_vehFlashMode "Electronic stability control: veh flash mode";
CM_ SG_ 805 ESP_infoComponentID "Electronic stability control: info component ID";
CM_ SG_ 805 ESP_infoPcbaID "Electronic stability control: info pcba ID";
CM_ SG_ 805 ESP_infoAssemblyID "Electronic stability control: info assembly ID";
CM_ SG_ 805 ESP_infoUsageID "Electronic stability control: info usage ID";
CM_ SG_ 805 ESP_infoSubUsageID "Electronic stability control: info sub usage ID";
CM_ SG_ 805 ESP_infoApplicationCRC "Indicating the Application CRC value of firmware running in system.";
CM_ SG_ 805 ESP_infoVehicleVariant "Electronic stability control: info vehicle variant";
CM_ SG_ 805 ESP_infoSubcomponent1 "Electronic stability control: info subcomponent1";
CM_ SG_ 805 ESP_infoBootUdsProtoVersion "Electronic stability control: info boot uds proto version";
CM_ SG_ 805 ESP_infoBootloaderCRC "Electronic stability control: info bootloader CRC";
CM_ SG_ 805 ESP_infoVariantCRC "Indicating the Calibration CRC value of firmware running in system.";
CM_ BO_ 1621 "Electronic stability control message: uds response; frame length from the layout, not yet observed on a vehicle bus";
CM_ SG_ 1621 ESP_udsResponseData "Electronic stability control: uds response data";
CM_ BO_ 861 "Electric brake booster message: alert matrix; frame length from the layout, not yet observed on a vehicle bus";
CM_ SG_ 861 IBST_matrixIndex "Electric brake booster: matrix index";
CM_ SG_ 861 IBST_a001_microSupplyError "Electric brake booster: a001 micro supply error";
CM_ SG_ 861 IBST_a002_HWBISTError "Electric brake booster: a002 HWBIST error";
CM_ SG_ 861 IBST_a003_RAMFault "Electric brake booster: a003 RAM fault";
CM_ SG_ 861 IBST_a004_flashFault "Electric brake booster: a004 flash fault";
CM_ SG_ 861 IBST_a005_microSafetyFault "Electric brake booster: a005 micro safety fault";
CM_ SG_ 861 IBST_a006_microSafetyLogicFault "Electric brake booster: a006 micro safety logic fault";
CM_ SG_ 861 IBST_a007_RBCPUException "Electric brake booster: a007 RBCPU exception";
CM_ SG_ 861 IBST_a008_stackOverUnderFlow "Electric brake booster: a008 stack over under flow";
CM_ SG_ 861 IBST_a009_systemErrorHook "Electric brake booster: a009 system error hook";
CM_ SG_ 861 IBST_a010_OSErrorHook "Electric brake booster: a010 OS error hook";
CM_ SG_ 861 IBST_a011_systemTaskOverRun "Electric brake booster: a011 system task over run";
CM_ SG_ 861 IBST_a012_OSTaskSchemeError "Electric brake booster: a012 OS task scheme error";
CM_ SG_ 861 IBST_a013_systemTaskJitter "Electric brake booster: a013 system task jitter";
CM_ SG_ 861 IBST_a014_DMATransferError "Electric brake booster: a014 DMA transfer error";
CM_ SG_ 861 IBST_a015_asicOscillatorError "Electric brake booster: a015 asic oscillator error";
CM_ SG_ 861 IBST_a016_RBBLMShaftShiftError "Electric brake booster: a016 RBBLM shaft shift error";
CM_ SG_ 861 IBST_a017_assertionFault "Electric brake booster: a017 assertion fault";
CM_ SG_ 861 IBST_a018_unsupportedHW "Electric brake booster: a018 unsupported HW";
CM_ SG_ 861 IBST_a019_supplyASICInitFault "Electric brake booster: a019 supply ASIC init fault";
CM_ SG_ 861 IBST_a020_VPREU5VOutOfRange "Electric brake booster: a020 VPREU5 v out of range";
CM_ SG_ 861 IBST_a021_IREFOutOfRange "Electric brake booster: a021 IREF out of range";
CM_ SG_ 861 IBST_a022_U5VTestFault "Electric brake booster: a022 U5 v test fault";
CM_ SG_ 861 IBST_a023_U5VOutOfRange "Electric brake booster: a023 U5 v out of range";
CM_ SG_ 861 IBST_a024_chargePumpFault "Electric brake booster: a024 charge pump fault";
CM_ SG_ 861 IBST_a025_ecuClockTestFault "Electric brake booster: a025 ecu clock test fault";
CM_ SG_ 861 IBST_a026_ecuBistCmdTestFault "Electric brake booster: a026 ecu bist cmd test fault";
CM_ SG_ 861 IBST_a027_ecuFastWdTestFault "Electric brake booster: a027 ecu fast wd test fault";
CM_ SG_ 861 IBST_a028_ecuBistFaultCtrFault "Electric brake booster: a028 ecu bist fault ctr fault";
CM_ SG_ 861 IBST_a029_ecuErrpinCounterFault "Electric brake booster: a029 ecu errpin counter fault";
CM_ SG_ 861 IBST_a030_ecuEnableElLowFault "Electric brake booster: a030 ecu enable el low fault";
CM_ SG_ 861 IBST_a031_decoupleBitTestFault "Electric brake booster: a031 decouple bit test fault";
CM_ SG_ 861 IBST_a032_ecuEnableElHighFault "Electric brake booster: a032 ecu enable el high fault";
CM_ SG_ 861 IBST_a033_ecuWdStartuptestFault "Electric brake booster: a033 ecu wd startuptest fault";
CM_ SG_ 861 IBST_a034_ecuEnableHyHighFault "Electric brake booster: a034 ecu enable hy high fault";
CM_ SG_ 861 IBST_a035_ecuEnableHyLowFault "Electric brake booster: a035 ecu enable hy low fault";
CM_ SG_ 861 IBST_a036_MRGPathTestFault "Electric brake booster: a036 MRG path test fault";
CM_ SG_ 861 IBST_a037_ecuWdSContinuousError "Electric brake booster: a037 ecu wd s continuous error";
CM_ SG_ 861 IBST_a038_ecuEnContinuousError "Electric brake booster: a038 ecu en continuous error";
CM_ SG_ 861 IBST_a039_GTMRefFrequencyError "Electric brake booster: a039 GTM ref frequency error";
CM_ SG_ 861 IBST_a040_GTMTbuMonError "Electric brake booster: a040 GTM tbu mon error";
CM_ SG_ 861 IBST_a041_micAsicClkInError "Electric brake booster: a041 mic asic clk in error";
CM_ SG_ 861 IBST_a042_micAsicInitTestError "Electric brake booster: a042 mic asic init test error";
CM_ SG_ 861 IBST_a043_micSpiTransferError "Electric brake booster: a043 mic spi transfer error";
CM_ SG_ 861 IBST_a044_NvMEepromWIP "Electric brake booster: a044 nv m eeprom WIP";
CM_ SG_ 861 IBST_a045_WdhAsicWdErrorCntStuck "Electric brake booster: a045 wdh asic wd error cnt stuck";
CM_ SG_ 861 IBST_a046_WdhAsicWdErrorCntLimit "Electric brake booster: a046 wdh asic wd error cnt limit";
CM_ SG_ 861 IBST_a047_WdhAsicWdCmdMissing "Electric brake booster: a047 wdh asic wd cmd missing";
CM_ SG_ 861 IBST_a048_WdhSwBistConCnt "Electric brake booster: a048 wdh sw bist con cnt";
CM_ SG_ 861 IBST_a049_WdhTaskMonConCnt "Electric brake booster: a049 wdh task mon con cnt";
CM_ SG_ 861 IBST_a050_VPreExternalFeeding "Electric brake booster: a050 v pre external feeding";
CM_ SG_ 861 IBST_a051_ecuBandgap "Electric brake booster: a051 ecu bandgap";
CM_ SG_ 861 IBST_a052_AdcPinTest "Electric brake booster: a052 adc pin test";
CM_ SG_ 861 IBST_a053_AdcSelftestC5P "Electric brake booster: a053 adc selftest C5 p";
CM_ SG_ 861 IBST_a054_AdcPeripheralFault "Electric brake booster: a054 adc peripheral fault";
CM_ SG_ 861 IBST_a055_UB6SupplyPathFault "Electric brake booster: a055 UB6 supply path fault";
CM_ SG_ 861 IBST_a056_UB6PlausiMonFault "Electric brake booster: a056 UB6 plausi mon fault";
CM_ SG_ 861 IBST_a057_microRegisterFault "Electric brake booster: a057 micro register fault";
CM_ SG_ 861 IBST_a058_NvMWriteCycleExceed "Electric brake booster: a058 nv m write cycle exceed";
CM_ SG_ 861 IBST_a059_NvMEepromSize "Electric brake booster: a059 nv m eeprom size";
CM_ SG_ 861 IBST_a060_NvMMigrationFault "Electric brake booster: a060 nv m migration fault";
CM_ SG_ 861 IBST_a061_AswSystemTimeOut "Electric brake booster: a061 asw system time out";
CM_ SG_ 861 IBST_a062_MICB6TransferError "Electric brake booster: a062 MICB6 transfer error";
CM_ SG_ 861 IBST_a063_tempSens2ShortToSupply "Electric brake booster: a063 temp sens2 short to supply";
CM_ SG_ 861 IBST_a064_tempSens1ShortToGround "Electric brake booster: a064 temp sens1 short to ground";
CM_ SG_ 861 IBST_a065_tempSens2ShortToGround "Electric brake booster: a065 temp sens2 short to ground";
CM_ SG_ 861 IBST_a066_tempSens1ShortToSupply "Electric brake booster: a066 temp sens1 short to supply";
CM_ SG_ 861 IBST_a067_tempSensImplausVoltage "Electric brake booster: a067 temp sens implaus voltage";
CM_ SG_ 861 IBST_a068_chargePumpUndervoltage "Electric brake booster: a068 charge pump undervoltage";
CM_ SG_ 861 IBST_a069_greasingRoutineFault "Electric brake booster: a069 greasing routine fault";
CM_ SG_ 861 IBST_a070_notShutDownNvMWrite "Electric brake booster: a070 not shut down nv m write";
CM_ SG_ 861 IBST_a071_notShutDownNvMRead "Electric brake booster: a071 not shut down nv m read";
CM_ SG_ 861 IBST_a072_notShutDownRight "Electric brake booster: a072 not shut down right";
CM_ SG_ 861 IBST_a073_jumpInAdjustNvMRead "Electric brake booster: a073 jump in adjust nv m read";
CM_ SG_ 861 IBST_a074_FindIdleDataNvMWrite "Electric brake booster: a074 find idle data nv m write";
CM_ SG_ 861 IBST_a075_FindIdleRoutineFault "Electric brake booster: a075 find idle routine fault";
CM_ SG_ 861 IBST_a076_masterCylLengthRead "Electric brake booster: a076 master cyl length read";
CM_ SG_ 861 IBST_a077_runOutMotorSaturated "Electric brake booster: a077 run out motor saturated";
CM_ SG_ 861 IBST_a078_wearOffsetCompNVMRead "Electric brake booster: a078 wear offset comp NVM read";
CM_ SG_ 861 IBST_a079_motorTempHighLevel1 "Electric brake booster: a079 motor temp high level1";
CM_ SG_ 861 IBST_a080_motorTempHighLevel2 "Electric brake booster: a080 motor temp high level2";
CM_ SG_ 861 IBST_a081_travelDeviation "Electric brake booster: a081 travel deviation";
CM_ SG_ 861 IBST_a082_motorSpeedDeviation "Electric brake booster: a082 motor speed deviation";
CM_ SG_ 861 IBST_a083_spindlePositionTooHigh "Electric brake booster: a083 spindle position too high";
CM_ SG_ 861 IBST_a084_CANTransceiverHWFault "Electric brake booster: a084 CAN transceiver HW fault";
CM_ SG_ 861 IBST_a085_supplyUndervoltageLvl3 "Electric brake booster: a085 supply undervoltage lvl3";
CM_ SG_ 861 IBST_a086_supplyOvervoltageLvl3 "Electric brake booster: a086 supply overvoltage lvl3";
CM_ SG_ 861 IBST_a087_rotorSinOutOfRangeLow "Electric brake booster: a087 rotor sin out of range low";
CM_ SG_ 861 IBST_a088_rotorCosOutOfRangeLow "Electric brake booster: a088 rotor cos out of range low";
CM_ SG_ 861 IBST_a089_rotorSinOutOfRangeHigh "Electric brake booster: a089 rotor sin out of range high";
CM_ SG_ 861 IBST_a090_rotorCosOutOfRangeHigh "Electric brake booster: a090 rotor cos out of range high";
CM_ SG_ 861 IBST_a091_SMMOneRequestsInit "Electric brake booster: a091 SMM one requests init";
CM_ SG_ 861 IBST_a092_systemStartTimeOut "Electric brake booster: a092 system start time out";
CM_ SG_ 861 IBST_a093_UEXSOvertemperature "Electric brake booster: a093 UEXS overtemperature";
CM_ SG_ 861 IBST_a094_XPASSEchoTimeDeviation "Electric brake booster: a094 XPASS echo time deviation";
CM_ SG_ 861 IBST_a095_XPASSTimeOut "Electric brake booster: a095 XPASS time out";
CM_ SG_ 861 IBST_a096_bridgeDriverMonError "Electric brake booster: a096 bridge driver mon error";
CM_ SG_ 861 IBST_a097_bridgeDriverError "Electric brake booster: a097 bridge driver error";
CM_ SG_ 861 IBST_a098_bridgeShortedPhase "Electric brake booster: a098 bridge shorted phase";
CM_ SG_ 861 IBST_a099_bridgeSwitchInitError "Electric brake booster: a099 bridge switch init error";
CM_ SG_ 861 IBST_a100_current2OffsetHigh "Electric brake booster: a100 current2 offset high";
CM_ SG_ 861 IBST_a101_current2OffsetLow "Electric brake booster: a101 current2 offset low";
CM_ SG_ 861 IBST_a102_current1OffsetHigh "Electric brake booster: a102 current1 offset high";
CM_ SG_ 861 IBST_a103_current1OffsetLow "Electric brake booster: a103 current1 offset low";
CM_ SG_ 861 IBST_a104_bridgeDriverShort "Electric brake booster: a104 bridge driver short";
CM_ SG_ 861 IBST_a105_LiPSUndervoltage "Electric brake booster: a105 li PS undervoltage";
CM_ SG_ 861 IBST_a106_LiPS5VSupply "Electric brake booster: a106 li PS5 v supply";
CM_ SG_ 861 IBST_a107_LiPS2PwmLineHigh "Electric brake booster: a107 li PS2 pwm line high";
CM_ SG_ 861 IBST_a108_LiPS2PwmLineLow "Electric brake booster: a108 li PS2 pwm line low";
CM_ SG_ 861 IBST_a109_LiPS2PwmTransmission "Electric brake booster: a109 li PS2 pwm transmission";
CM_ SG_ 861 IBST_a110_LiPS1SentLineHigh "Electric brake booster: a110 li PS1 sent line high";
CM_ SG_ 861 IBST_a111_LiPS1SentLineLow "Electric brake booster: a111 li PS1 sent line low";
CM_ SG_ 861 IBST_a112_LiPS1SentTransmission "Electric brake booster: a112 li PS1 sent transmission";
CM_ SG_ 861 IBST_a113_LiPS1SentSensor "Electric brake booster: a113 li PS1 sent sensor";
CM_ SG_ 861 IBST_a114_partyBusOff "Electric brake booster: a114 party bus off";
CM_ SG_ 861 IBST_a115_chassisBusOff "Electric brake booster: a115 chassis bus off";
CM_ SG_ 861 IBST_a116_supplyUndervoltageLvl2 "Electric brake booster: a116 supply undervoltage lvl2";
CM_ SG_ 861 IBST_a117_supplyOvervoltageLvl2 "Electric brake booster: a117 supply overvoltage lvl2";
CM_ SG_ 861 IBST_a118_RPSNvMReadFault "Electric brake booster: a118 RPS nv m read fault";
CM_ SG_ 861 IBST_a119_RPSWrongCalibData "Electric brake booster: a119 RPS wrong calib data";
CM_ SG_ 861 IBST_a120_RPSVectorRangeHigh "Electric brake booster: a120 RPS vector range high";
CM_ SG_ 861 IBST_a121_RPSVectorRangeLow "Electric brake booster: a121 RPS vector range low";
CM_ SG_ 861 IBST_a122_RPSVectorOscillating "Electric brake booster: a122 RPS vector oscillating";
CM_ SG_ 861 IBST_a123_bridgeDriverUnavail "Electric brake booster: a123 bridge driver unavail";
CM_ SG_ 861 IBST_a124_OBDCurrent1OORHigh "Electric brake booster: a124 OBD current1 OOR high";
CM_ SG_ 861 IBST_a125_OBDCurrent2OORHigh "Electric brake booster: a125 OBD current2 OOR high";
CM_ SG_ 861 IBST_a126_OBDCurrent1OORLow "Electric brake booster: a126 OBD current1 OOR low";
CM_ SG_ 861 IBST_a127_OBDCurrent2OORLow "Electric brake booster: a127 OBD current2 OOR low";
CM_ SG_ 861 IBST_a128_BLMMuxerTimeoutError "Electric brake booster: a128 BLM muxer timeout error";
CM_ SG_ 861 IBST_a129_loadDumpOnFSLTest "Electric brake booster: a129 load dump on FSL test";
CM_ SG_ 861 IBST_a130_DTSFunctionalRangeLow "Electric brake booster: a130 DTS functional range low";
CM_ SG_ 861 IBST_a131_DTSFunctionalRangeHigh "Electric brake booster: a131 DTS functional range high";
CM_ SG_ 861 IBST_a132_DTSPlausiCheck1vs2 "Electric brake booster: a132 DTS plausi check1vs2";
CM_ SG_ 861 IBST_a133_DTSOffsetTooLow "Electric brake booster: a133 DTS offset too low";
CM_ SG_ 861 IBST_a134_DTSOffsetTooHigh "Electric brake booster: a134 DTS offset too high";
CM_ SG_ 861 IBST_a135_ESPparty1DLC "Electric brake booster: a135 ES pparty1 DLC";
CM_ SG_ 861 IBST_a136_ESPparty1Timeout "Electric brake booster: a136 ES pparty1 timeout";
CM_ SG_ 861 IBST_a137_ESPparty1Checksum "Electric brake booster: a137 ES pparty1 checksum";
CM_ SG_ 861 IBST_a138_ESPparty1Counter "Electric brake booster: a138 ES pparty1 counter";
CM_ SG_ 861 IBST_a139_ESPparty2DLC "Electric brake booster: a139 ES pparty2 DLC";
CM_ SG_ 861 IBST_a140_ESPparty2Timeout "Electric brake booster: a140 ES pparty2 timeout";
CM_ SG_ 861 IBST_a141_ESPparty2Checksum "Electric brake booster: a141 ES pparty2 checksum";
CM_ SG_ 861 IBST_a142_ESPparty2Counter "Electric brake booster: a142 ES pparty2 counter";
CM_ SG_ 861 IBST_a143_ESPparty3DLC "Electric brake booster: a143 ES pparty3 DLC";
CM_ SG_ 861 IBST_a144_ESPparty3Timeout "Electric brake booster: a144 ES pparty3 timeout";
CM_ SG_ 861 IBST_a145_ESPparty3Checksum "Electric brake booster: a145 ES pparty3 checksum";
CM_ SG_ 861 IBST_a146_ESPparty3Counter "Electric brake booster: a146 ES pparty3 counter";
CM_ SG_ 861 IBST_a147_PSCMotorSizeReadFault "Electric brake booster: a147 PSC motor size read fault";
CM_ SG_ 861 IBST_a148_MLIGainMechReadFault "Electric brake booster: a148 MLI gain mech read fault";
CM_ SG_ 861 IBST_a149_MLITMCAreaReadFault "Electric brake booster: a149 MLITMC area read fault";
CM_ SG_ 861 IBST_a150_motorTestFault "Electric brake booster: a150 motor test fault";
CM_ SG_ 861 IBST_a151_PSCGearRatioReadFault "Electric brake booster: a151 PSC gear ratio read fault";
CM_ SG_ 861 IBST_a152_PSCVoltageImplausible "Electric brake booster: a152 PSC voltage implausible";
CM_ SG_ 861 IBST_a153_unused "Electric brake booster: a153 unused";
CM_ SG_ 861 IBST_a154_unused "Electric brake booster: a154 unused";
CM_ SG_ 861 IBST_a155_supplyUndervoltageLvl1 "Electric brake booster: a155 supply undervoltage lvl1";
CM_ SG_ 861 IBST_a156_supplyOvervoltageLvl1 "Electric brake booster: a156 supply overvoltage lvl1";
CM_ SG_ 861 IBST_a157_masterCylPressInvalid "Electric brake booster: a157 master cyl press invalid";
CM_ SG_ 861 IBST_a158_DTSOffsHighSuspicious "Electric brake booster: a158 DTS offs high suspicious";
CM_ SG_ 861 IBST_a159_FindIdleNvMReadError "Electric brake booster: a159 find idle nv m read error";
CM_ SG_ 861 IBST_a160_DTSIDTimeOut "Electric brake booster: a160 DTSID time out";
CM_ SG_ 861 IBST_a161_powerPackMismatch "Electric brake booster: a161 power pack mismatch";
CM_ SG_ 861 IBST_a162_idlePosNotDetected "Electric brake booster: a162 idle pos not detected";
CM_ SG_ 861 IBST_a163_ESPpEstMaxInvalid "Electric brake booster: a163 ES pp est max invalid";
CM_ SG_ 861 IBST_a164_ESPVehicleSpeedInvalid "Electric brake booster: a164 ESP vehicle speed invalid";
CM_ SG_ 861 IBST_a165_ESPpForceBlendInvalid "Electric brake booster: a165 ES pp force blend invalid";
CM_ SG_ 861 IBST_a166_ESPpMcVirtualInvalid "Electric brake booster: a166 ES pp mc virtual invalid";
CM_ SG_ 861 IBST_a167_ESPqTargetExterInvalid "Electric brake booster: a167 ES pq target exter invalid";
CM_ SG_ 861 IBST_a168_CANOvervoltage "Electric brake booster: a168 CAN overvoltage";
CM_ SG_ 861 IBST_a169_CANUndervoltage "Electric brake booster: a169 CAN undervoltage";
CM_ SG_ 861 IBST_a170_LVPowerStateTimeout "Electric brake booster: a170 LV power state timeout";
CM_ SG_ 861 IBST_a171_LVPowerStateChecksum "Electric brake booster: a171 LV power state checksum";
CM_ SG_ 861 IBST_a172_LVPowerStateDLC "Electric brake booster: a172 LV power state DLC";
CM_ SG_ 861 IBST_a173_LVPowerStateCounter "Electric brake booster: a173 LV power state counter";
CM_ SG_ 861 IBST_a174_LVOffStateInvalid "Electric brake booster: a174 LV off state invalid";
CM_ SG_ 861 IBST_a175_LVGoingDownInvalid "Electric brake booster: a175 LV going down invalid";
CM_ SG_ 861 IBST_a176_blockedPedalDetected "Electric brake booster: a176 blocked pedal detected";
CM_ SG_ 861 IBST_a177_EPBLsystemStatusMIA "Electric brake booster: a177 EPB lsystem status MIA";
CM_ SG_ 861 IBST_a178_EPBRsystemStatusMIA "Electric brake booster: a178 EPB rsystem status MIA";
CM_ SG_ 861 IBST_a179_VCLEFTepbmStatusMIA "Electric brake booster: a179 VCLEF tepbm status MIA";
CM_ SG_ 861 IBST_a180_VCRIGHTepbmStatusMIA "Electric brake booster: a180 VCRIGH tepbm status MIA";
CM_ SG_ 861 IBST_a181_DIchassisControlDLC "Electric brake booster: a181 d ichassis control DLC";
CM_ SG_ 861 IBST_a182_DIchassisControlTimeou "Electric brake booster: a182 d ichassis control timeout";
CM_ SG_ 861 IBST_a183_DIchassisControlChecks "Electric brake booster: a183 d ichassis control checksum";
CM_ SG_ 861 IBST_a184_DIchassisControlCounte "Electric brake booster: a184 d ichassis control counter";
CM_ SG_ 861 IBST_a185_rightBusOff "Electric brake booster: a185 right bus off";
CM_ SG_ 861 IBST_a186_rightBusPassive "Electric brake booster: a186 right bus passive";
CM_ SG_ 861 IBST_a187_brakeBusOff "Electric brake booster: a187 brake bus off";
CM_ SG_ 861 IBST_a188_brakeBusPassive "Electric brake booster: a188 brake bus passive";
CM_ SG_ 861 IBST_a189_rightVCLVPowerStateTim "Electric brake booster: a189 right VCLV power state timeout";
CM_ SG_ 861 IBST_a190_rightVCLVPowerStateDLC "Electric brake booster: a190 right VCLV power state DLC";
CM_ SG_ 861 IBST_a191_rightVCLVPowerStateChe "Electric brake booster: a191 right VCLV power state checksum";
CM_ SG_ 861 IBST_a192_rightVCLVPowerStateCou "Electric brake booster: a192 right VCLV power state counter";
CM_ SG_ 861 IBST_a193_leftVCLVPowerStateTime "Electric brake booster: a193 left VCLV power state timeout";
CM_ SG_ 861 IBST_a194_leftVCLVPowerStateChec "Electric brake booster: a194 left VCLV power state checksum";
CM_ SG_ 861 IBST_a195_leftVCLVPowerStateDLC "Electric brake booster: a195 left VCLV power state DLC";
CM_ SG_ 861 IBST_a196_leftVCLVPowerStateCoun "Electric brake booster: a196 left VCLV power state counter";
CM_ SG_ 861 IBST_a197_brakeLatencyReductionA "Electric brake booster: a197 brake latency reduction active";
CM_ SG_ 861 IBST_a198_aesActive "Electric brake booster: a198 aes active";
CM_ SG_ 861 IBST_a199_undefinedAlertDetected "Electric brake booster: a199 undefined alert detected";
CM_ SG_ 861 IBST_a200_aesFault "Electric brake booster: a200 aes fault";
CM_ SG_ 861 IBST_a201_EGGREAR1wheelSpeedsRea "Electric brake booster: a201 eggrear1wheel speeds rear time out";
CM_ SG_ 861 IBST_a202_EGGREAR1wheelSpeedsRea "Electric brake booster: a202 eggrear1wheel speeds rear checksum";
CM_ SG_ 861 IBST_a203_EGGREAR1wheelSpeedsRea "Electric brake booster: a203 eggrear1wheel speeds rear DLC";
CM_ SG_ 861 IBST_a204_EGGREAR1wheelSpeedsRea "Electric brake booster: a204 eggrear1wheel speeds rear counter";
CM_ SG_ 861 IBST_a205_EGGRIGHT1wheelSpeedsFr "Electric brake booster: a205 eggright1wheel speeds front time out";
CM_ SG_ 861 IBST_a206_EGGRIGHT1wheelSpeedsFr "Electric brake booster: a206 eggright1wheel speeds front checksum";
CM_ SG_ 861 IBST_a207_EGGRIGHT1wheelSpeedsFr "Electric brake booster: a207 eggright1wheel speeds front DLC";
CM_ SG_ 861 IBST_a208_EGGRIGHT1wheelSpeedsFr "Electric brake booster: a208 eggright1wheel speeds front counter";
CM_ SG_ 861 IBST_a209_reducedBrakePowerActiv "Electric brake booster: a209 reduced brake power active";
CM_ SG_ 861 IBST_a210_reducedBrakePowerNotAv "Electric brake booster: a210 reduced brake power not available";
CM_ SG_ 861 IBST_a211_DETReportError "Electric brake booster: a211 DET report error";
CM_ SG_ 861 IBST_a212_infoFailureWrongCUBASH "Electric brake booster: a212 info failure wrong CUBAS handling detected";
CM_ SG_ 861 IBST_a213_PDURouterinitializatio "Electric brake booster: a213 PDU routerinitialization failed";
CM_ SG_ 861 IBST_a214_LossOfPDUInstanceDetec "Electric brake booster: a214 loss of PDU instance detected";
CM_ SG_ 861 IBST_a215_UnsupportedSeriesHWDet "Electric brake booster: a215 unsupported series HW detected";
CM_ SG_ 861 IBST_a216_AsicMalfunctionDetecte "Electric brake booster: a216 asic malfunction detected";
CM_ SG_ 861 IBST_a217_AsicTrimmingNotComplet "Electric brake booster: a217 asic trimming not completed";
CM_ SG_ 861 IBST_a218_uCSafetyNotificationGR "Electric brake booster: a218 u c safety notification GRAM";
CM_ SG_ 861 IBST_a219_uCSafetyNotification "Electric brake booster: a219 u c safety notification";
CM_ SG_ 861 IBST_a220_ASICOvercurrentOnGPIO2 "Electric brake booster: a220 ASIC overcurrent on GPIO250 2";
CM_ SG_ 861 IBST_a221_ASICOvercurrentOnGPIO2 "Electric brake booster: a221 ASIC overcurrent on GPIO250 1";
CM_ SG_ 861 IBST_a222_ASICOvercurrentOnGPIO5 "Electric brake booster: a222 ASIC overcurrent on GPIO50 4";
CM_ SG_ 861 IBST_a223_ASICOvercurrentOnGPIO5 "Electric brake booster: a223 ASIC overcurrent on GPIO50 3";
CM_ SG_ 861 IBST_a224_ASICOvercurrentOnGPIO5 "Electric brake booster: a224 ASIC overcurrent on GPIO50 2";
CM_ SG_ 861 IBST_a225_ASICOvercurrentOnGPIO5 "Electric brake booster: a225 ASIC overcurrent on GPIO50 1";
CM_ SG_ 861 IBST_a226_ASICOvercurrentOnWRHS "Electric brake booster: a226 ASIC overcurrent on WRHS";
CM_ SG_ 861 IBST_a227_wakeRequestMismatchDet "Electric brake booster: a227 wake request mismatch detected";
CM_ SG_ 861 IBST_a228_BlockedPedalDetectedDu "Electric brake booster: a228 blocked pedal detected during HAD";
CM_ SG_ 861 IBST_a229_BlockedPedalDetected "Electric brake booster: a229 blocked pedal detected";
CM_ SG_ 861 IBST_a230_DTS2FunctionalRangeLow "Electric brake booster: a230 DTS2 functional range low";
CM_ SG_ 861 IBST_a231_DTS2FunctionalRangeLow "Electric brake booster: a231 DTS2 functional range low";
CM_ SG_ 861 IBST_a232_PostAssemblyRoutineFai "Electric brake booster: a232 post assembly routine failed";
CM_ SG_ 861 IBST_a233_ReferenceRunAbortByECU "Electric brake booster: a233 reference run abort by ECU reset";
CM_ SG_ 861 IBST_a234_LiPSOutOfRangeHigh "Electric brake booster: a234 li PS out of range high";
CM_ SG_ 861 IBST_a235_LiPSOutOfRangeLow "Electric brake booster: a235 li PS out of range low";
CM_ SG_ 861 IBST_a246_DASredundantBrakingCon "Electric brake booster: a246 DA sredundant braking control party checksum";
CM_ SG_ 861 IBST_a247_DASredundantBrakingCon "Electric brake booster: a247 DA sredundant braking control party counter";
CM_ SG_ 861 IBST_a248_DASredundantBrakingCon "Electric brake booster: a248 DA sredundant braking control party DLC";
CM_ SG_ 861 IBST_a249_DASredundantBrakingCon "Electric brake booster: a249 DA sredundant braking control party timeout";
CM_ SG_ 861 IBST_a250_DASredundantBrakingCon "Electric brake booster: a250 DA sredundant braking control chassis checksum";
CM_ SG_ 861 IBST_a251_DASredundantBrakingCon "Electric brake booster: a251 DA sredundant braking control chassis counter";
CM_ SG_ 861 IBST_a252_DASredundantBrakingCon "Electric brake booster: a252 DA sredundant braking control chassis DLC";
CM_ SG_ 861 IBST_a253_DASredundantBrakingCon "Electric brake booster: a253 DA sredundant braking control chassis timeout";
CM_ SG_ 861 IBST_a254_DIlocStatus2Checksum "Electric brake booster: a254 d iloc status2 checksum";
CM_ SG_ 861 IBST_a255_DIlocStatus2Counter "Electric brake booster: a255 d iloc status2 counter";
CM_ SG_ 861 IBST_a256_DIlocStatus2DLC "Electric brake booster: a256 d iloc status2 DLC";
CM_ SG_ 861 IBST_a257_DIlocStatus2Timeout "Electric brake booster: a257 d iloc status2 timeout";
CM_ SG_ 861 IBST_a258_standaloneEBRActive "Electric brake booster: a258 standalone EBR active";
CM_ SG_ 861 IBST_a259_EMCMain11Checksum "Electric brake booster: a259 EMC main11 checksum";
CM_ SG_ 861 IBST_a260_EMCMain11Counter "Electric brake booster: a260 EMC main11 counter";
CM_ SG_ 861 IBST_a261_EMCMain11DLC "Electric brake booster: a261 EMC main11 DLC";
CM_ SG_ 861 IBST_a262_EMCMain11Timeout "Electric brake booster: a262 EMC main11 timeout";
CM_ SG_ 861 IBST_a263_EMCMain21Checksum "Electric brake booster: a263 EMC main21 checksum";
CM_ SG_ 861 IBST_a264_EMCMain21Counter "Electric brake booster: a264 EMC main21 counter";
CM_ SG_ 861 IBST_a265_EMCMain21DLC "Electric brake booster: a265 EMC main21 DLC";
CM_ SG_ 861 IBST_a266_EMCMain21Timeout "Electric brake booster: a266 EMC main21 timeout";
CM_ BO_ 813 "Electric brake booster message: info; frame length from the layout, not yet observed on a vehicle bus";
CM_ SG_ 813 IBST_infoIndex "Electric brake booster: info index";
CM_ SG_ 813 IBST_infoBuildType "Electric brake booster: info build type";
CM_ SG_ 813 IBST_infoComponentID "Electric brake booster: info component ID";
CM_ SG_ 813 IBST_infoPcbaID "Electric brake booster: info pcba ID";
CM_ SG_ 813 IBST_infoAssemblyID "Electric brake booster: info assembly ID";
CM_ SG_ 813 IBST_infoUsageID "Electric brake booster: info usage ID";
CM_ SG_ 813 IBST_infoSubUsageID "Electric brake booster: info sub usage ID";
CM_ SG_ 813 IBST_infoApplicationCRC "Indicating the Application CRC value of firmware running in system.";
CM_ SG_ 813 IBST_infoBootUdsProtoVersion "Electric brake booster: info boot uds proto version";
CM_ SG_ 813 IBST_infoBootloaderCRC "Electric brake booster: info bootloader CRC";
CM_ SG_ 813 IBST_infoVariantCRC "Indicating the Calibration CRC value of firmware running in system.";
CM_ BO_ 1629 "Electric brake booster message: uds response; frame length from the layout, not yet observed on a vehicle bus";
CM_ SG_ 1629 IBST_udsResponseData "Electric brake booster: uds response data";
BA_DEF_ BO_ "GenMsgCycleTime" INT 0 3600000;
BA_DEF_ BO_ "GenMsgSendType" ENUM "Cyclic","NotUsed","NotUsed","NotUsed","NotUsed","NotUsed","NotUsed","IfActive","NoMsgSendType","NotUsed";
BA_DEF_ BO_ "VFrameFormat" ENUM "StandardCAN","ExtendedCAN","reserved","J1939PG","reserved","reserved","reserved","reserved","reserved","reserved","reserved","reserved","reserved","reserved","StandardCAN_FD","ExtendedCAN_FD";
BA_DEF_ BO_ "CANFD_BRS" ENUM "0","1";
BA_DEF_ SG_ "GenSigSNA" STRING;
BA_DEF_ SG_ "SystemSignalLongSymbol" STRING;
BA_DEF_ SG_ "Confidence" ENUM "validated","plausible","layout-only","contradicted";
BA_DEF_DEF_ "GenMsgCycleTime" 0;
BA_DEF_DEF_ "GenMsgSendType" "NoMsgSendType";
BA_DEF_DEF_ "VFrameFormat" "StandardCAN";
BA_DEF_DEF_ "CANFD_BRS" "1";
BA_DEF_DEF_ "GenSigSNA" "";
BA_DEF_DEF_ "SystemSignalLongSymbol" "";
BA_DEF_DEF_ "Confidence" "layout-only";
BA_ "GenMsgCycleTime" BO_ 913 1000;
BA_ "GenMsgSendType" BO_ 913 0;
BA_ "GenMsgCycleTime" BO_ 977 1000;
BA_ "GenMsgSendType" BO_ 977 0;
BA_ "GenMsgCycleTime" BO_ 785 1000;
BA_ "GenMsgSendType" BO_ 785 0;
BA_ "GenMsgCycleTime" BO_ 880 10;
BA_ "GenMsgSendType" BO_ 880 0;
BA_ "GenMsgCycleTime" BO_ 981 1000;
BA_ "GenMsgSendType" BO_ 981 0;
BA_ "GenMsgCycleTime" BO_ 805 10000;
BA_ "GenMsgSendType" BO_ 805 0;
BA_ "GenMsgCycleTime" BO_ 1621 100;
BA_ "GenMsgSendType" BO_ 1621 0;
BA_ "GenMsgCycleTime" BO_ 861 1000;
BA_ "GenMsgSendType" BO_ 861 0;
BA_ "GenMsgCycleTime" BO_ 813 10000;
BA_ "GenMsgSendType" BO_ 813 0;
BA_ "Confidence" SG_ 913 EPAS3S_matrixIndex 1;
BA_ "SystemSignalLongSymbol" SG_ 913 EPAS3S_a149_currentSensPathSwitc "EPAS3S_a149_currentSensPathSwitch";
BA_ "SystemSignalLongSymbol" SG_ 913 EPAS3S_a150_currentSensOffsetDet "EPAS3S_a150_currentSensOffsetDetect";
BA_ "SystemSignalLongSymbol" SG_ 913 EPAS3S_a156_angleSensorDivergenc "EPAS3S_a156_angleSensorDivergence";
BA_ "SystemSignalLongSymbol" SG_ 913 EPAS3S_a160_latentFaultTestResul "EPAS3S_a160_latentFaultTestResult";
BA_ "SystemSignalLongSymbol" SG_ 913 EPAS3S_a161_initTestPhaDisconnIn "EPAS3S_a161_initTestPhaDisconnInfo";
BA_ "SystemSignalLongSymbol" SG_ 913 EPAS3S_a168_torsionBarTorqueQfDe "EPAS3S_a168_torsionBarTorqueQfDegraded";
BA_ "Confidence" SG_ 977 EPAS3S_appliedAngleOffset 0;
BA_ "Confidence" SG_ 977 EPAS3S_calculatedAngleOffset 0;
BA_ "Confidence" SG_ 977 EPAS3S_resyncStatus 0;
BA_ "Confidence" SG_ 977 EPAS3S_pullDriftLongTermTrq 0;
BA_ "Confidence" SG_ 977 EPAS3S_pullDriftCompTrq 0;
BA_ "Confidence" SG_ 977 EPAS3S_learnedSCCMOffset 0;
BA_ "Confidence" SG_ 785 EPAS3S_infoIndex 1;
BA_ "Confidence" SG_ 785 EPAS3S_infoBuildType 0;
BA_ "Confidence" SG_ 785 EPAS3S_infoComponentID 0;
BA_ "Confidence" SG_ 785 EPAS3S_infoPcbaID 0;
BA_ "Confidence" SG_ 785 EPAS3S_infoAssemblyID 0;
BA_ "Confidence" SG_ 785 EPAS3S_infoUsageID 0;
BA_ "Confidence" SG_ 785 EPAS3S_infoApplicationCRC 0;
BA_ "Confidence" SG_ 785 EPAS3S_infoBootUdsProtoVersion 0;
BA_ "Confidence" SG_ 785 EPAS3S_infoBootloaderCRC 0;
BA_ "Confidence" SG_ 785 EPAS3S_infoSubcomponent2 0;
BA_ "Confidence" SG_ 880 EPAS3S_steeringRackForce 1;
BA_ "GenSigSNA" SG_ 880 EPAS3S_steeringRackForce "1023";
BA_ "Confidence" SG_ 880 EPAS3S_steeringFault 1;
BA_ "Confidence" SG_ 880 EPAS3S_steeringReduced 1;
BA_ "Confidence" SG_ 880 EPAS3S_internalSASQF 1;
BA_ "Confidence" SG_ 880 EPAS3S_currentTuneMode 1;
BA_ "Confidence" SG_ 880 EPAS3S_torsionBarTorque 1;
BA_ "GenSigSNA" SG_ 880 EPAS3S_torsionBarTorque "4095";
BA_ "Confidence" SG_ 880 EPAS3S_eacErrorCode 1;
BA_ "GenSigSNA" SG_ 880 EPAS3S_eacErrorCode "15";
BA_ "Confidence" SG_ 880 EPAS3S_internalSAS 1;
BA_ "Confidence" SG_ 880 EPAS3S_handsOnLevel 1;
BA_ "Confidence" SG_ 880 EPAS3S_driverlessState 1;
BA_ "Confidence" SG_ 880 EPAS3S_eacStatus 1;
BA_ "Confidence" SG_ 1848 EPAS3S_udsResponseData 1;
BA_ "Confidence" SG_ 981 ESP_matrixIndex 1;
BA_ "SystemSignalLongSymbol" SG_ 981 ESP_a193_DIchassisControlChecksu "ESP_a193_DIchassisControlChecksum";
BA_ "SystemSignalLongSymbol" SG_ 981 ESP_a269_DIRELTorqueCommandInval "ESP_a269_DIRELTorqueCommandInvalid";
BA_ "SystemSignalLongSymbol" SG_ 981 ESP_a271_DIRELTorqueActualInvali "ESP_a271_DIRELTorqueActualInvalid";
BA_ "SystemSignalLongSymbol" SG_ 981 ESP_a276_DIRERTorqueCommandInval "ESP_a276_DIRERTorqueCommandInvalid";
BA_ "SystemSignalLongSymbol" SG_ 981 ESP_a278_DIRERTorqueActualInvali "ESP_a278_DIRERTorqueActualInvalid";
BA_ "SystemSignalLongSymbol" SG_ 981 ESP_a279_lifetimeManagementOverr "ESP_a279_lifetimeManagementOverrun";
BA_ "SystemSignalLongSymbol" SG_ 981 ESP_a282_trackModeABSRequestInva "ESP_a282_trackModeABSRequestInvalid";
BA_ "SystemSignalLongSymbol" SG_ 981 ESP_a283_secondaryCollisionMitig "ESP_a283_secondaryCollisionMitigationActive";
BA_ "SystemSignalLongSymbol" SG_ 981 ESP_a284_scmRequestInvalidChecks "ESP_a284_scmRequestInvalidChecksum";
BA_ "SystemSignalLongSymbol" SG_ 981 ESP_a287_failedBrakeCircuitDetec "ESP_a287_failedBrakeCircuitDetected";
BA_ "SystemSignalLongSymbol" SG_ 981 ESP_a296_roadWheelAngleHealthDeg "ESP_a296_roadWheelAngleHealthDegraded";
BA_ "SystemSignalLongSymbol" SG_ 981 ESP_a297_roadWheelAngleHealthFau "ESP_a297_roadWheelAngleHealthFaulted";
BA_ "SystemSignalLongSymbol" SG_ 981 ESP_a298_RSArearSteerStatusTimeo "ESP_a298_RSArearSteerStatusTimeout";
BA_ "SystemSignalLongSymbol" SG_ 981 ESP_a300_RSArearSteerStatusCheck "ESP_a300_RSArearSteerStatusChecksum";
BA_ "SystemSignalLongSymbol" SG_ 981 ESP_a302_rearRoadWheelAngleHealt "ESP_a302_rearRoadWheelAngleHealthDegraded";
BA_ "SystemSignalLongSymbol" SG_ 981 ESP_a303_rearRoadWheelAngleHealt "ESP_a303_rearRoadWheelAngleHealthFaulted";
BA_ "SystemSignalLongSymbol" SG_ 981 ESP_a304_rearVCLVPowerStateTimeo "ESP_a304_rearVCLVPowerStateTimeout";
BA_ "SystemSignalLongSymbol" SG_ 981 ESP_a306_rearVCLVPowerStateCheck "ESP_a306_rearVCLVPowerStateChecksum";
BA_ "SystemSignalLongSymbol" SG_ 981 ESP_a307_rearVCLVPowerStateCount "ESP_a307_rearVCLVPowerStateCounter";
BA_ "SystemSignalLongSymbol" SG_ 981 ESP_a310_brakeLatencyReductionAc "ESP_a310_brakeLatencyReductionActive";
BA_ "SystemSignalLongSymbol" SG_ 981 ESP_a319_AES_BackupActuatorActiv "ESP_a319_AES_BackupActuatorActive";
BA_ "SystemSignalLongSymbol" SG_ 981 ESP_a334_BrakePedalAppliedInvali "ESP_a334_BrakePedalAppliedInvalid";
BA_ "SystemSignalLongSymbol" SG_ 981 ESP_a337_pReductionPotentialInva "ESP_a337_pReductionPotentialInvalid";
BA_ "SystemSignalLongSymbol" SG_ 981 ESP_a341_EnhancedPressureBuildAc "ESP_a341_EnhancedPressureBuildActive";
BA_ "SystemSignalLongSymbol" SG_ 981 ESP_a342_EnhancedPressureBuildNo "ESP_a342_EnhancedPressureBuildNotAvailable";
BA_ "SystemSignalLongSymbol" SG_ 981 ESP_a343_EnhancedPressureBuildLt "ESP_a343_EnhancedPressureBuildLtmReached";
BA_ "SystemSignalLongSymbol" SG_ 981 ESP_a351_ActuatorYellowLampReque "ESP_a351_ActuatorYellowLampRequested";
BA_ "SystemSignalLongSymbol" SG_ 981 ESP_a353_PressureSensorImplausHi "ESP_a353_PressureSensorImplausHigh";
BA_ "SystemSignalLongSymbol" SG_ 981 ESP_a358_externalActuatorFallbac "ESP_a358_externalActuatorFallback";
BA_ "SystemSignalLongSymbol" SG_ 981 ESP_a359_externalActuatorNoExtRe "ESP_a359_externalActuatorNoExtReq";
BA_ "SystemSignalLongSymbol" SG_ 981 ESP_a362_BBbrakeActuationChecksu "ESP_a362_BBbrakeActuationChecksum";
BA_ "SystemSignalLongSymbol" SG_ 981 ESP_a366_ActuatorBlendingModeReq "ESP_a366_ActuatorBlendingModeReqNotAvailable";
BA_ "SystemSignalLongSymbol" SG_ 981 ESP_a367_CBDS_fillBufferThreshol "ESP_a367_CBDS_fillBufferThreshold";
BA_ "SystemSignalLongSymbol" SG_ 981 ESP_a369_LargeLeakageDetectedByD "ESP_a369_LargeLeakageDetectedByDPB";
BA_ "SystemSignalLongSymbol" SG_ 981 ESP_a379_DASredundantBrakingCont "ESP_a379_DASredundantBrakingControlPartyChecksum";
BA_ "SystemSignalLongSymbol" SG_ 981 ESP_a380_DASredundantBrakingCont "ESP_a380_DASredundantBrakingControlPartyCounter";
BA_ "SystemSignalLongSymbol" SG_ 981 ESP_a381_DASredundantBrakingCont "ESP_a381_DASredundantBrakingControlPartyDLC";
BA_ "SystemSignalLongSymbol" SG_ 981 ESP_a382_DASredundantBrakingCont "ESP_a382_DASredundantBrakingControlPartyTimeout";
BA_ "SystemSignalLongSymbol" SG_ 981 ESP_a383_DASredundantBrakingCont "ESP_a383_DASredundantBrakingControlChassisChecksum";
BA_ "SystemSignalLongSymbol" SG_ 981 ESP_a384_DASredundantBrakingCont "ESP_a384_DASredundantBrakingControlChassisCounter";
BA_ "SystemSignalLongSymbol" SG_ 981 ESP_a385_DASredundantBrakingCont "ESP_a385_DASredundantBrakingControlChassisDLC";
BA_ "SystemSignalLongSymbol" SG_ 981 ESP_a386_DASredundantBrakingCont "ESP_a386_DASredundantBrakingControlChassisTimeout";
BA_ "SystemSignalLongSymbol" SG_ 981 ESP_a392_driverlessArmingUnavail "ESP_a392_driverlessArmingUnavailable";
BA_ "SystemSignalLongSymbol" SG_ 981 ESP_a406_DIespActuatorTestTimeou "ESP_a406_DIespActuatorTestTimeout";
BA_ "SystemSignalLongSymbol" SG_ 981 ESP_a407_DIespActuatorTestChecks "ESP_a407_DIespActuatorTestChecksum";
BA_ "SystemSignalLongSymbol" SG_ 981 ESP_a409_DIespActuatorTestCounte "ESP_a409_DIespActuatorTestCounter";
BA_ "Confidence" SG_ 805 ESP_infoIndex 1;
BA_ "Confidence" SG_ 805 ESP_infoBuildType 0;
BA_ "Confidence" SG_ 805 ESP_vehFlashMode 0;
BA_ "Confidence" SG_ 805 ESP_infoComponentID 0;
BA_ "Confidence" SG_ 805 ESP_infoPcbaID 0;
BA_ "Confidence" SG_ 805 ESP_infoAssemblyID 0;
BA_ "Confidence" SG_ 805 ESP_infoUsageID 0;
BA_ "Confidence" SG_ 805 ESP_infoSubUsageID 0;
BA_ "Confidence" SG_ 805 ESP_infoApplicationCRC 1;
BA_ "Confidence" SG_ 805 ESP_infoVehicleVariant 0;
BA_ "Confidence" SG_ 805 ESP_infoSubcomponent1 0;
BA_ "Confidence" SG_ 805 ESP_infoBootUdsProtoVersion 0;
BA_ "Confidence" SG_ 805 ESP_infoBootloaderCRC 0;
BA_ "Confidence" SG_ 805 ESP_infoVariantCRC 1;
BA_ "Confidence" SG_ 1621 ESP_udsResponseData 1;
BA_ "Confidence" SG_ 861 IBST_matrixIndex 1;
BA_ "SystemSignalLongSymbol" SG_ 861 IBST_a182_DIchassisControlTimeou "IBST_a182_DIchassisControlTimeout";
BA_ "SystemSignalLongSymbol" SG_ 861 IBST_a183_DIchassisControlChecks "IBST_a183_DIchassisControlChecksum";
BA_ "SystemSignalLongSymbol" SG_ 861 IBST_a184_DIchassisControlCounte "IBST_a184_DIchassisControlCounter";
BA_ "SystemSignalLongSymbol" SG_ 861 IBST_a189_rightVCLVPowerStateTim "IBST_a189_rightVCLVPowerStateTimeout";
BA_ "SystemSignalLongSymbol" SG_ 861 IBST_a191_rightVCLVPowerStateChe "IBST_a191_rightVCLVPowerStateChecksum";
BA_ "SystemSignalLongSymbol" SG_ 861 IBST_a192_rightVCLVPowerStateCou "IBST_a192_rightVCLVPowerStateCounter";
BA_ "SystemSignalLongSymbol" SG_ 861 IBST_a193_leftVCLVPowerStateTime "IBST_a193_leftVCLVPowerStateTimeout";
BA_ "SystemSignalLongSymbol" SG_ 861 IBST_a194_leftVCLVPowerStateChec "IBST_a194_leftVCLVPowerStateChecksum";
BA_ "SystemSignalLongSymbol" SG_ 861 IBST_a196_leftVCLVPowerStateCoun "IBST_a196_leftVCLVPowerStateCounter";
BA_ "SystemSignalLongSymbol" SG_ 861 IBST_a197_brakeLatencyReductionA "IBST_a197_brakeLatencyReductionActive";
BA_ "SystemSignalLongSymbol" SG_ 861 IBST_a201_EGGREAR1wheelSpeedsRea "IBST_a201_EGGREAR1wheelSpeedsRearTimeOut";
BA_ "SystemSignalLongSymbol" SG_ 861 IBST_a202_EGGREAR1wheelSpeedsRea "IBST_a202_EGGREAR1wheelSpeedsRearChecksum";
BA_ "SystemSignalLongSymbol" SG_ 861 IBST_a203_EGGREAR1wheelSpeedsRea "IBST_a203_EGGREAR1wheelSpeedsRearDLC";
BA_ "SystemSignalLongSymbol" SG_ 861 IBST_a204_EGGREAR1wheelSpeedsRea "IBST_a204_EGGREAR1wheelSpeedsRearCounter";
BA_ "SystemSignalLongSymbol" SG_ 861 IBST_a205_EGGRIGHT1wheelSpeedsFr "IBST_a205_EGGRIGHT1wheelSpeedsFrontTimeOut";
BA_ "SystemSignalLongSymbol" SG_ 861 IBST_a206_EGGRIGHT1wheelSpeedsFr "IBST_a206_EGGRIGHT1wheelSpeedsFrontChecksum";
BA_ "SystemSignalLongSymbol" SG_ 861 IBST_a207_EGGRIGHT1wheelSpeedsFr "IBST_a207_EGGRIGHT1wheelSpeedsFrontDLC";
BA_ "SystemSignalLongSymbol" SG_ 861 IBST_a208_EGGRIGHT1wheelSpeedsFr "IBST_a208_EGGRIGHT1wheelSpeedsFrontCounter";
BA_ "SystemSignalLongSymbol" SG_ 861 IBST_a209_reducedBrakePowerActiv "IBST_a209_reducedBrakePowerActive";
BA_ "SystemSignalLongSymbol" SG_ 861 IBST_a210_reducedBrakePowerNotAv "IBST_a210_reducedBrakePowerNotAvailable";
BA_ "SystemSignalLongSymbol" SG_ 861 IBST_a212_infoFailureWrongCUBASH "IBST_a212_infoFailureWrongCUBASHandlingDetected";
BA_ "SystemSignalLongSymbol" SG_ 861 IBST_a213_PDURouterinitializatio "IBST_a213_PDURouterinitializationFailed";
BA_ "SystemSignalLongSymbol" SG_ 861 IBST_a214_LossOfPDUInstanceDetec "IBST_a214_LossOfPDUInstanceDetected";
BA_ "SystemSignalLongSymbol" SG_ 861 IBST_a215_UnsupportedSeriesHWDet "IBST_a215_UnsupportedSeriesHWDetected";
BA_ "SystemSignalLongSymbol" SG_ 861 IBST_a216_AsicMalfunctionDetecte "IBST_a216_AsicMalfunctionDetected";
BA_ "SystemSignalLongSymbol" SG_ 861 IBST_a217_AsicTrimmingNotComplet "IBST_a217_AsicTrimmingNotCompleted";
BA_ "SystemSignalLongSymbol" SG_ 861 IBST_a218_uCSafetyNotificationGR "IBST_a218_uCSafetyNotificationGRAM";
BA_ "SystemSignalLongSymbol" SG_ 861 IBST_a220_ASICOvercurrentOnGPIO2 "IBST_a220_ASICOvercurrentOnGPIO250_2";
BA_ "SystemSignalLongSymbol" SG_ 861 IBST_a221_ASICOvercurrentOnGPIO2 "IBST_a221_ASICOvercurrentOnGPIO250_1";
BA_ "SystemSignalLongSymbol" SG_ 861 IBST_a222_ASICOvercurrentOnGPIO5 "IBST_a222_ASICOvercurrentOnGPIO50_4";
BA_ "SystemSignalLongSymbol" SG_ 861 IBST_a223_ASICOvercurrentOnGPIO5 "IBST_a223_ASICOvercurrentOnGPIO50_3";
BA_ "SystemSignalLongSymbol" SG_ 861 IBST_a224_ASICOvercurrentOnGPIO5 "IBST_a224_ASICOvercurrentOnGPIO50_2";
BA_ "SystemSignalLongSymbol" SG_ 861 IBST_a225_ASICOvercurrentOnGPIO5 "IBST_a225_ASICOvercurrentOnGPIO50_1";
BA_ "SystemSignalLongSymbol" SG_ 861 IBST_a227_wakeRequestMismatchDet "IBST_a227_wakeRequestMismatchDetected";
BA_ "SystemSignalLongSymbol" SG_ 861 IBST_a228_BlockedPedalDetectedDu "IBST_a228_BlockedPedalDetectedDuringHAD";
BA_ "SystemSignalLongSymbol" SG_ 861 IBST_a232_PostAssemblyRoutineFai "IBST_a232_PostAssemblyRoutineFailed";
BA_ "SystemSignalLongSymbol" SG_ 861 IBST_a233_ReferenceRunAbortByECU "IBST_a233_ReferenceRunAbortByECUReset";
BA_ "SystemSignalLongSymbol" SG_ 861 IBST_a246_DASredundantBrakingCon "IBST_a246_DASredundantBrakingControlPartyChecksum";
BA_ "SystemSignalLongSymbol" SG_ 861 IBST_a247_DASredundantBrakingCon "IBST_a247_DASredundantBrakingControlPartyCounter";
BA_ "SystemSignalLongSymbol" SG_ 861 IBST_a248_DASredundantBrakingCon "IBST_a248_DASredundantBrakingControlPartyDLC";
BA_ "SystemSignalLongSymbol" SG_ 861 IBST_a249_DASredundantBrakingCon "IBST_a249_DASredundantBrakingControlPartyTimeout";
BA_ "SystemSignalLongSymbol" SG_ 861 IBST_a250_DASredundantBrakingCon "IBST_a250_DASredundantBrakingControlChassisChecksum";
BA_ "SystemSignalLongSymbol" SG_ 861 IBST_a251_DASredundantBrakingCon "IBST_a251_DASredundantBrakingControlChassisCounter";
BA_ "SystemSignalLongSymbol" SG_ 861 IBST_a252_DASredundantBrakingCon "IBST_a252_DASredundantBrakingControlChassisDLC";
BA_ "SystemSignalLongSymbol" SG_ 861 IBST_a253_DASredundantBrakingCon "IBST_a253_DASredundantBrakingControlChassisTimeout";
BA_ "Confidence" SG_ 813 IBST_infoIndex 1;
BA_ "Confidence" SG_ 813 IBST_infoBuildType 0;
BA_ "Confidence" SG_ 813 IBST_infoPcbaID 0;
BA_ "Confidence" SG_ 813 IBST_infoAssemblyID 0;
BA_ "Confidence" SG_ 813 IBST_infoUsageID 0;
BA_ "Confidence" SG_ 813 IBST_infoSubUsageID 0;
BA_ "Confidence" SG_ 813 IBST_infoApplicationCRC 0;
BA_ "Confidence" SG_ 813 IBST_infoBootUdsProtoVersion 0;
BA_ "Confidence" SG_ 813 IBST_infoBootloaderCRC 0;
BA_ "Confidence" SG_ 813 IBST_infoVariantCRC 0;
BA_ "Confidence" SG_ 1629 IBST_udsResponseData 1;
VAL_ 913 EPAS3S_matrixIndex 2 "AlertMatrix2" 1 "AlertMatrix1" 0 "AlertMatrix0" ;
VAL_ 977 EPAS3S_resyncStatus 1 "RESYNC_COMPLETE" 0 "RESYNC_PENDING" ;
VAL_ 785 EPAS3S_infoIndex 255 "END" 31 "SUBCOMPONENT_GITHASH" 30 "PACKAGE_SN_8_14" 29 "PACKAGE_SN_1_7" 27 "PACKAGE_PN_15_20" 26 "PACKAGE_PN_8_14" 25 "PACKAGE_PN_1_7" 23 "SUBCOMPONENT2" 22 "VARIANTCRC" 20 "UDS_PROTOCOL_BOOTCRC" 19 "VERSION_DEPRECATED" 18 "BOOTLOADER_GITHASH" 17 "APP_GITHASH" 16 "SUBCOMPONENT" 15 "BOOTLOADER_CRC" 14 "BOOTLOADER_SVN" 13 "APP_CRC" 11 "PCBAID_ASSYID_USAGEID" 10 "BUILD_HWID_COMPONENTID" 9 "DEPRECATED_9" 8 "DEPRECATED_8" 7 "DEPRECATED_7" 6 "DEPRECATED_6" 5 "DEPRECATED_5" 4 "DEPRECATED_4" 3 "DEPRECATED_3" 2 "DEPRECATED_2" 1 "DEPRECATED_1" 0 "DEPRECATED_0" ;
VAL_ 785 EPAS3S_infoBuildType 4 "INFO_MFG_BUILD" 3 "INFO_TRACEABLE_CI_BUILD" 2 "INFO_LOCAL_BUILD" 1 "INFO_PLATFORM_BUILD" 0 "INFO_UNKNOWN_BUILD" ;
VAL_ 880 EPAS3S_steeringRackForce 1023 "SNA" 1022 "NOT_IN_SPEC" ;
VAL_ 880 EPAS3S_steeringFault 1 "FAULT" 0 "NO_FAULT" ;
VAL_ 880 EPAS3S_steeringReduced 1 "REDUCED_ASSIST" 0 "NORMAL_ASSIST" ;
VAL_ 880 EPAS3S_internalSASQF 1 "IN_SPEC" 0 "UNDEFINABLE_ACCURACY" ;
VAL_ 880 EPAS3S_currentTuneMode 5 "STEERING_TUNE_RWD_SPORT" 4 "STEERING_TUNE_RWD_STANDARD" 3 "STEERING_TUNE_RWD_COMFORT" 2 "STEERING_TUNE_DM_SPORT" 1 "STEERING_TUNE_DM_STANDARD" 0 "STEERING_TUNE_DM_COMFORT" ;
VAL_ 880 EPAS3S_torsionBarTorque 4095 "SNA" 4094 "UNDEFINABLE_DATA" ;
VAL_ 880 EPAS3S_eacErrorCode 15 "SNA" 14 "EAC_EXTERNAL_MONITOR_INHIBIT" 13 "EAC_ERROR_PINION_VEL_DIFF" 12 "EAC_ERROR_LOW_ASSIST" 11 "EAC_ERROR_HIGH_TORSION_SAFETY" 10 "EAC_ERROR_HIGH_MMOT_SAFETY" 9 "EAC_ERROR_HIGH_ANGLE_RATE_SAFETY" 8 "EAC_ERROR_HIGH_ANGLE_SAFETY" 7 "EAC_ERROR_HIGH_ANGLE_RATE_REQ" 6 "EAC_ERROR_HIGH_ANGLE_REQ" 5 "EAR_ERROR_MAX_STEER_DELTA" 4 "EAC_ERROR_TMP_FAULT" 3 "EAC_ERROR_HANDS_ON" 2 "EAC_ERROR_MAX_SPEED" 1 "EAC_ERROR_MIN_SPEED" 0 "EAC_ERROR_IDLE" ;
VAL_ 880 EPAS3S_handsOnLevel 3 "LEVEL_3" 2 "LEVEL_2" 1 "LEVEL_1" 0 "LEVEL_0" ;
VAL_ 880 EPAS3S_driverlessState 1 "EAC_DRIVERLESS_ACTIVE" 0 "EAC_DRIVERLESS_INACTIVE" ;
VAL_ 880 EPAS3S_eacStatus 7 "EAC_ELK_ACTIVE" 6 "EAC_ELK_AVAILABLE" 5 "EAC_LKA_ACTIVE" 4 "EAC_LKA_ELK_AVAILABLE" 3 "EAC_FAULT" 2 "EAC_ACTIVE" 1 "EAC_AVAILABLE" 0 "EAC_INHIBITED" ;
VAL_ 981 ESP_matrixIndex 6 "AlertMatrix6" 5 "AlertMatrix5" 4 "AlertMatrix4" 3 "AlertMatrix3" 2 "AlertMatrix2" 1 "AlertMatrix1" 0 "AlertMatrix0" ;
VAL_ 805 ESP_infoIndex 255 "END" 31 "SUBCOMPONENT_GITHASH" 30 "PACKAGE_SN_8_14" 29 "PACKAGE_SN_1_7" 27 "PACKAGE_PN_15_20" 26 "PACKAGE_PN_8_14" 25 "PACKAGE_PN_1_7" 23 "SUBCOMPONENT2" 22 "VARIANTCRC" 20 "UDS_PROTOCOL_BOOTCRC" 19 "VERSION_DEPRECATED" 18 "BOOTLOADER_GITHASH" 17 "APP_GITHASH" 16 "SUBCOMPONENT" 15 "BOOTLOADER_CRC" 14 "BOOTLOADER_SVN" 13 "APP_CRC" 11 "PCBAID_ASSYID_USAGEID" 10 "BUILD_HWID_COMPONENTID" 9 "DEPRECATED_9" 8 "DEPRECATED_8" 7 "DEPRECATED_7" 6 "DEPRECATED_6" 5 "DEPRECATED_5" 4 "DEPRECATED_4" 3 "DEPRECATED_3" 2 "DEPRECATED_2" 1 "DEPRECATED_1" 0 "DEPRECATED_0" ;
VAL_ 805 ESP_infoBuildType 4 "INFO_MFG_BUILD" 3 "INFO_TRACEABLE_CI_BUILD" 2 "INFO_LOCAL_BUILD" 1 "INFO_PLATFORM_BUILD" 0 "INFO_UNKNOWN_BUILD" ;
VAL_ 805 ESP_vehFlashMode 1 "Development_Mode" 0 "Production_Mode" ;
VAL_ 805 ESP_infoSubUsageID 16 "XCP_Dfive_ESP_CP_CB" 8 "nonXCP_Dfour_ESP_CP_CB" 4 "XCP_Gladiator_ESP" 2 "nonXCP_Rev_C_ESP_Cappella" 0 "nonXCP_Rev_B_ESP_Cappella" ;
VAL_ 805 ESP_infoVehicleVariant 9 "MODEL_3_VARIANT_09" 8 "MODEL_3_VARIANT_08" 7 "MODEL_3_VARIANT_07" 6 "MODEL_3_VARIANT_06" 5 "MODEL_3_VARIANT_05" 4 "MODEL_3_VARIANT_04" 3 "MODEL_3_VARIANT_03" 2 "MODEL_3_VARIANT_02" 1 "MODEL_3_VARIANT_01" ;
VAL_ 861 IBST_matrixIndex 4 "AlertMatrix4" 3 "AlertMatrix3" 2 "AlertMatrix2" 1 "AlertMatrix1" 0 "AlertMatrix0" ;
VAL_ 813 IBST_infoIndex 255 "END" 31 "SUBCOMPONENT_GITHASH" 30 "PACKAGE_SN_8_14" 29 "PACKAGE_SN_1_7" 27 "PACKAGE_PN_15_20" 26 "PACKAGE_PN_8_14" 25 "PACKAGE_PN_1_7" 23 "SUBCOMPONENT2" 22 "VARIANTCRC" 20 "UDS_PROTOCOL_BOOTCRC" 19 "VERSION_DEPRECATED" 18 "BOOTLOADER_GITHASH" 17 "APP_GITHASH" 16 "SUBCOMPONENT" 15 "BOOTLOADER_CRC" 14 "BOOTLOADER_SVN" 13 "APP_CRC" 11 "PCBAID_ASSYID_USAGEID" 10 "BUILD_HWID_COMPONENTID" 9 "DEPRECATED_9" 8 "DEPRECATED_8" 7 "DEPRECATED_7" 6 "DEPRECATED_6" 5 "DEPRECATED_5" 4 "DEPRECATED_4" 3 "DEPRECATED_3" 2 "DEPRECATED_2" 1 "DEPRECATED_1" 0 "DEPRECATED_0" ;
VAL_ 813 IBST_infoBuildType 4 "INFO_MFG_BUILD" 3 "INFO_TRACEABLE_CI_BUILD" 2 "INFO_LOCAL_BUILD" 1 "INFO_PLATFORM_BUILD" 0 "INFO_UNKNOWN_BUILD" ;
